VERSION "HNNBNNNYNNNNNNNNNNNNNNNNNNNNNNNNNNNNNNNNNN/4/%%%/4/'%**4NNN///"

NS_ :

BS_:

BU_: AEM BAP_Tester E_Sound FBK FLA Gateway Gateway_PAG ISE MRR_HL MRR_HR NightVision RDK SAK SAK2 SCR STH_MLBevo TopView

BO_ 977 TSG_BT_01: 8 Gateway
 SG_ BT_Tuer_geoeffnet : 0|1@1+ (1.0,0.0) [0.0|1] ""  Vector__XXX
 SG_ BT_verriegelt : 1|1@1+ (1.0,0.0) [0.0|1] ""  Vector__XXX
 SG_ BT_gesafet : 2|1@1+ (1.0,0.0) [0.0|1] ""  Vector__XXX
 SG_ BT_Schluesselschalter_auf : 3|1@1+ (1.0,0.0) [0.0|1] ""  Vector__XXX
 SG_ BT_Schluesselschalter_zu : 4|1@1+ (1.0,0.0) [0.0|1] ""  Vector__XXX
 SG_ BT_Unlock_Taster : 5|1@1+ (1.0,0.0) [0.0|1] ""  Vector__XXX
 SG_ BT_Lock_Taster : 6|1@1+ (1.0,0.0) [0.0|1] ""  Vector__XXX
 SG_ BT_Sperrklinke : 7|1@1+ (1.0,0.0) [0.0|1] ""  Vector__XXX
 SG_ BT_TAG_betaetigt : 8|1@1+ (1.0,0.0) [0.0|1] ""  Vector__XXX
 SG_ BT_TIG_betaetigt : 9|1@1+ (1.0,0.0) [0.0|1] ""  Vector__XXX
 SG_ BT_EC_Spiegel_Helligkeit : 10|5@1+ (3.125,0) [0.000|96.875] "Unit_PerCent"  Vector__XXX
 SG_ BT_Sp_Heizung_Anf : 15|1@1+ (100,0) [0|100] "Unit_PerCent"  Vector__XXX
 SG_ BT_Tuer_Status : 16|2@1+ (1.0,0.0) [0.0|3] ""  Vector__XXX
 SG_ BT_TSG_hinten_verbaut : 18|1@1+ (1.0,0.0) [0.0|1] ""  Vector__XXX
 SG_ BT_Sp_Blk_def : 19|1@1+ (1.0,0.0) [0.0|1] ""  Vector__XXX
 SG_ BT_FH_S_ManHoch : 20|1@1+ (1.0,0.0) [0.0|1] ""  Vector__XXX
 SG_ BT_FH_S_AutoHoch : 21|1@1+ (1.0,0.0) [0.0|1] ""  Vector__XXX
 SG_ BT_FH_S_ManTief : 22|1@1+ (1.0,0.0) [0.0|1] ""  Vector__XXX
 SG_ BT_FH_S_AutoTief : 23|1@1+ (1.0,0.0) [0.0|1] ""  Vector__XXX
 SG_ BT_FH_Oeffnung : 24|8@1+ (0.5,0) [0.0|100.0] "Unit_PerCent"  Vector__XXX
 SG_ BT_FH_Bew_hoch : 32|1@1+ (1.0,0.0) [0.0|1] ""  Vector__XXX
 SG_ BT_FH_Bew_tief : 33|1@1+ (1.0,0.0) [0.0|1] ""  Vector__XXX
 SG_ BT_FH_Fang : 34|1@1+ (1.0,0.0) [0.0|1] ""  Vector__XXX
 SG_ BT_FH_Block : 35|1@1+ (1.0,0.0) [0.0|1] ""  Vector__XXX
 SG_ BT_FH_Thermo : 36|1@1+ (1.0,0.0) [0.0|1] ""  Vector__XXX
 SG_ BT_UEKB_aktiviert : 37|1@1+ (1.0,0.0) [0.0|1] ""  Vector__XXX
 SG_ BT_Kisi_Fehler : 38|1@1+ (1.0,0.0) [0.0|1] ""  Vector__XXX
 SG_ BT_FH_normiert : 39|1@1+ (1.0,0.0) [0.0|1] ""  Vector__XXX
 SG_ BT_Schliesstaster : 40|1@1+ (1.0,0.0) [0.0|1] ""  Vector__XXX
 SG_ BT_Zuziehhilfe_aktiv : 41|1@1+ (1.0,0.0) [0.0|1] ""  Vector__XXX
 SG_ BT_SP_ausgerastet : 42|1@1+ (1.0,0.0) [0.0|1] ""  Vector__XXX
 SG_ BT_SP_lr_aktiv : 43|1@1+ (1.0,0.0) [0.0|1] ""  Vector__XXX
 SG_ BT_SP_ht_aktiv : 44|1@1+ (1.0,0.0) [0.0|1] ""  Vector__XXX
 SG_ BT_SP_Heizung_aktiv : 45|1@1+ (1.0,0.0) [0.0|1] ""  Vector__XXX
 SG_ BT_Oben_Block_erw : 46|1@1+ (1.0,0.0) [0.0|1] ""  Vector__XXX
 SG_ BT_Unten_Block_erw : 47|1@1+ (1.0,0.0) [0.0|1] ""  Vector__XXX
 SG_ BT_Tuer_Status_QBit : 48|1@1+ (1.0,0.0) [0.0|1] ""  Vector__XXX
 SG_ BFS_Status_eTAG : 49|2@1+ (1.0,0.0) [0.0|3] ""  Vector__XXX
 SG_ BT_TCR_Mode_aktiv : 51|1@1+ (1.0,0.0) [0.0|1] ""  Vector__XXX
 SG_ BT_SP_Heizung_Status : 55|1@1+ (1.0,0.0) [0.0|1] ""  Vector__XXX
 SG_ ASW_Warnung_aktiv_BFS : 56|1@1+ (1.0,0.0) [0.0|1] ""  MRR_HL,MRR_HR
 SG_ BT_FH_Pos_oben : 57|1@1+ (1.0,0.0) [0.0|1] ""  Vector__XXX
 SG_ BT_Tuerschloss_defekt : 58|1@1+ (1.0,0.0) [0.0|1] ""  Vector__XXX
 SG_ BT_Tueroeffnen_Warnung : 59|1@1+ (1.0,0.0) [0.0|1] ""  Vector__XXX
 SG_ BT_Lock_Taster_inv : 60|1@1+ (1.0,0.0) [0.0|1] ""  Vector__XXX
 SG_ BT_Schluesselschalter_zu_inv : 61|1@1+ (1.0,0.0) [0.0|1] ""  Vector__XXX
 SG_ BT_SWA_HMI_defekt : 62|1@1+ (1.0,0.0) [0.0|1] ""  Vector__XXX
 SG_ BT_ASW_HMI_defekt : 63|1@1+ (1.0,0.0) [0.0|1] ""  Vector__XXX

BO_ 976 TSG_FT_01: 8 Gateway
 SG_ FT_Tuer_geoeffnet : 0|1@1+ (1.0,0.0) [0.0|1] ""  Vector__XXX
 SG_ FT_verriegelt : 1|1@1+ (1.0,0.0) [0.0|1] ""  Vector__XXX
 SG_ FT_gesafet : 2|1@1+ (1.0,0.0) [0.0|1] ""  Vector__XXX
 SG_ FT_Schluesselschalter_auf : 3|1@1+ (1.0,0.0) [0.0|1] ""  Vector__XXX
 SG_ FT_Schluesselschalter_zu : 4|1@1+ (1.0,0.0) [0.0|1] ""  Vector__XXX
 SG_ FT_Unlock_Taster : 5|1@1+ (1.0,0.0) [0.0|1] ""  Vector__XXX
 SG_ FT_Lock_Taster : 6|1@1+ (1.0,0.0) [0.0|1] ""  Vector__XXX
 SG_ FT_Sperrklinke : 7|1@1+ (1.0,0.0) [0.0|1] ""  Vector__XXX
 SG_ FT_TAG_betaetigt : 8|1@1+ (1.0,0.0) [0.0|1] ""  Vector__XXX
 SG_ FT_TIG_betaetigt : 9|1@1+ (1.0,0.0) [0.0|1] ""  Vector__XXX
 SG_ FT_IRUE_Taste : 10|1@1+ (1.0,0.0) [0.0|1] ""  Vector__XXX
 SG_ FT_HD_Taste : 11|1@1+ (1.0,0.0) [0.0|1] ""  Vector__XXX
 SG_ FT_TD_Taste_Fehler : 12|1@1+ (1.0,0.0) [0.0|1] ""  Vector__XXX
 SG_ FT_TD_Taste : 13|1@1+ (1.0,0.0) [0.0|1] ""  Vector__XXX
 SG_ SSR_Temp_Freigabe : 14|1@1+ (1.0,0.0) [0.0|1] ""  Vector__XXX
 SG_ FT_Sp_Heizung_Anf : 15|1@1+ (100,0) [0|100] "Unit_PerCent"  Vector__XXX
 SG_ FT_HD_Taste_2 : 16|1@1+ (1.0,0.0) [0.0|1] ""  Vector__XXX
 SG_ FT_TSG_hinten_verbaut : 18|1@1+ (1.0,0.0) [0.0|1] ""  Vector__XXX
 SG_ FT_Sp_Blk_def : 19|1@1+ (1.0,0.0) [0.0|1] ""  Vector__XXX
 SG_ FT_FH_S_ManHoch : 20|1@1+ (1.0,0.0) [0.0|1] ""  Vector__XXX
 SG_ FT_FH_S_AutoHoch : 21|1@1+ (1.0,0.0) [0.0|1] ""  Vector__XXX
 SG_ FT_FH_S_ManTief : 22|1@1+ (1.0,0.0) [0.0|1] ""  Vector__XXX
 SG_ FT_FH_S_AutoTief : 23|1@1+ (1.0,0.0) [0.0|1] ""  Vector__XXX
 SG_ FT_FH_Oeffnung : 24|8@1+ (0.5,0) [0.0|100.0] "Unit_PerCent"  Vector__XXX
 SG_ FT_FH_Bew_hoch : 32|1@1+ (1.0,0.0) [0.0|1] ""  Vector__XXX
 SG_ FT_FH_Bew_tief : 33|1@1+ (1.0,0.0) [0.0|1] ""  Vector__XXX
 SG_ FT_FH_Fang : 34|1@1+ (1.0,0.0) [0.0|1] ""  Vector__XXX
 SG_ FT_FH_Block : 35|1@1+ (1.0,0.0) [0.0|1] ""  Vector__XXX
 SG_ FT_FH_Thermo : 36|1@1+ (1.0,0.0) [0.0|1] ""  Vector__XXX
 SG_ FT_UEKB_aktiviert : 37|1@1+ (1.0,0.0) [0.0|1] ""  Vector__XXX
 SG_ ASW_HMI_defekt : 38|1@1+ (1.0,0.0) [0.0|1] ""  MRR_HL,MRR_HR
 SG_ FT_FH_normiert : 39|1@1+ (1.0,0.0) [0.0|1] ""  Vector__XXX
 SG_ FT_Schliesstaster : 40|1@1+ (1.0,0.0) [0.0|1] ""  Vector__XXX
 SG_ FT_Zuziehhilfe_aktiv : 41|1@1+ (1.0,0.0) [0.0|1] ""  Vector__XXX
 SG_ FT_SP_ausgerastet : 42|1@1+ (1.0,0.0) [0.0|1] ""  Vector__XXX
 SG_ FT_SP_lr_aktiv : 43|1@1+ (1.0,0.0) [0.0|1] ""  Vector__XXX
 SG_ FT_SP_ht_aktiv : 44|1@1+ (1.0,0.0) [0.0|1] ""  Vector__XXX
 SG_ ASW_wakeup : 45|1@1+ (1.0,0.0) [0.0|1] ""  MRR_HL,MRR_HR
 SG_ FT_Oben_Block_erw : 46|1@1+ (1.0,0.0) [0.0|1] ""  Vector__XXX
 SG_ FT_Unten_Block_erw : 47|1@1+ (1.0,0.0) [0.0|1] ""  Vector__XXX
 SG_ FT_Kisi_li_aktiv : 48|1@1+ (1.0,0.0) [0.0|1] ""  Vector__XXX
 SG_ FT_Kisi_re_aktiv : 49|1@1+ (1.0,0.0) [0.0|1] ""  Vector__XXX
 SG_ FT_Kisi_Taster_li : 50|1@1+ (1.0,0.0) [0.0|1] ""  Vector__XXX
 SG_ FT_Kisi_Taster_re : 51|1@1+ (1.0,0.0) [0.0|1] ""  Vector__XXX
 SG_ FT_BFS_Fond_Freigabe : 52|1@1+ (1.0,0.0) [0.0|1] ""  Vector__XXX
 SG_ FT_Kisi_Fehler : 53|1@1+ (1.0,0.0) [0.0|1] ""  Vector__XXX
 SG_ FT_Daemmglas : 54|1@1+ (1.0,0.0) [0.0|1] ""  Vector__XXX
 SG_ FT_SP_Heizung_Status : 55|1@1+ (1.0,0.0) [0.0|1] ""  Vector__XXX
 SG_ ASW_Warnung_aktiv_FS : 56|1@1+ (1.0,0.0) [0.0|1] ""  MRR_HL,MRR_HR
 SG_ FT_FH_Pos_oben : 57|1@1+ (1.0,0.0) [0.0|1] ""  Vector__XXX
 SG_ FT_Tuerschloss_defekt : 58|1@1+ (1.0,0.0) [0.0|1] ""  Vector__XXX
 SG_ FT_SWA_Taster : 59|1@1+ (1.0,0.0) [0.0|1] ""  MRR_HR
 SG_ SWA_HMI_Diagnose : 60|2@1+ (1.0,0.0) [0.0|3] ""  MRR_HL,MRR_HR
 SG_ FS_Status_eTAG : 62|2@1+ (1.0,0.0) [0.0|3] ""  Vector__XXX

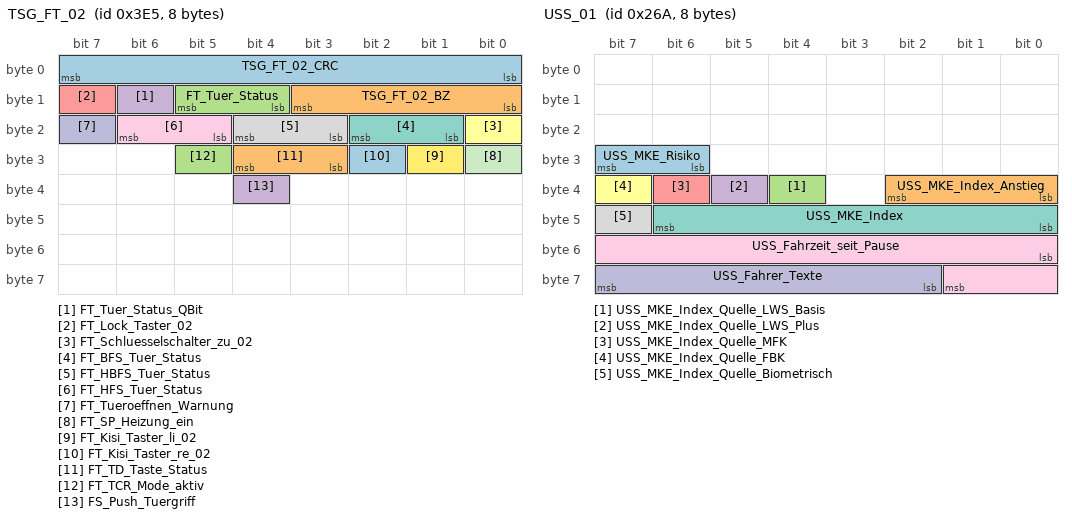
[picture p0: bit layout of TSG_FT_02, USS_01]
BO_ 997 TSG_FT_02: 8 Gateway
 SG_ TSG_FT_02_CRC : 0|8@1+ (1,0) [0|255] ""  Vector__XXX
 SG_ TSG_FT_02_BZ : 8|4@1+ (1,0) [0|15] ""  Vector__XXX
 SG_ FT_Tuer_Status : 12|2@1+ (1.0,0.0) [0.0|3] ""  FBK
 SG_ FT_Tuer_Status_QBit : 14|1@1+ (1.0,0.0) [0.0|1] ""  FBK
 SG_ FT_Lock_Taster_02 : 15|1@1+ (1.0,0.0) [0.0|1] ""  Vector__XXX
 SG_ FT_Schluesselschalter_zu_02 : 16|1@1+ (1.0,0.0) [0.0|1] ""  Vector__XXX
 SG_ FT_BFS_Tuer_Status : 17|2@1+ (1.0,0.0) [0.0|3] ""  Vector__XXX
 SG_ FT_HBFS_Tuer_Status : 19|2@1+ (1.0,0.0) [0.0|3] ""  Vector__XXX
 SG_ FT_HFS_Tuer_Status : 21|2@1+ (1.0,0.0) [0.0|3] ""  Vector__XXX
 SG_ FT_Tueroeffnen_Warnung : 23|1@1+ (1.0,0.0) [0.0|1] ""  Vector__XXX
 SG_ FT_SP_Heizung_ein : 24|1@1+ (1.0,0.0) [0.0|1] ""  Vector__XXX
 SG_ FT_Kisi_Taster_li_02 : 25|1@1+ (1.0,0.0) [0.0|1] ""  Vector__XXX
 SG_ FT_Kisi_Taster_re_02 : 26|1@1+ (1.0,0.0) [0.0|1] ""  Vector__XXX
 SG_ FT_TD_Taste_Status : 27|2@1+ (1.0,0.0) [0.0|3] ""  Vector__XXX
 SG_ FT_TCR_Mode_aktiv : 29|1@1+ (1.0,0.0) [0.0|1] ""  Vector__XXX
 SG_ FS_Push_Tuergriff : 36|1@1+ (1.0,0.0) [0.0|1] ""  Vector__XXX

BO_ 975 TSG_HBFS_01: 8 Gateway
 SG_ HBFS_Tuer_geoeffnet : 0|1@1+ (1.0,0.0) [0.0|1] ""  Vector__XXX
 SG_ HBFS_verriegelt : 1|1@1+ (1.0,0.0) [0.0|1] ""  Vector__XXX
 SG_ HBFS_gesafet : 2|1@1+ (1.0,0.0) [0.0|1] ""  Vector__XXX
 SG_ HBFS_Heckrollotaster_betaetigt : 3|1@1+ (1.0,0.0) [0.0|1] ""  Vector__XXX
 SG_ HBFS_Tuerschloss_defekt : 4|1@1+ (1.0,0.0) [0.0|1] ""  Vector__XXX
 SG_ HBFS_Unlock_Taster : 5|1@1+ (1.0,0.0) [0.0|1] ""  Vector__XXX
 SG_ HBFS_Lock_Taster : 6|1@1+ (1.0,0.0) [0.0|1] ""  Vector__XXX
 SG_ HBFS_Sperrklinke : 7|1@1+ (1.0,0.0) [0.0|1] ""  Vector__XXX
 SG_ HBFS_TAG_betaetigt : 8|1@1+ (1.0,0.0) [0.0|1] ""  Vector__XXX
 SG_ HBFS_TIG_betaetigt : 9|1@1+ (1.0,0.0) [0.0|1] ""  Vector__XXX
 SG_ HBFS_FH_S_HFS_AutoHoch : 10|1@1+ (1.0,0.0) [0.0|1] ""  Vector__XXX
 SG_ HBFS_FH_S_HFS_AutoTief : 11|1@1+ (1.0,0.0) [0.0|1] ""  Vector__XXX
 SG_ HBFS_FH_S_HFS_ManHoch : 12|1@1+ (1.0,0.0) [0.0|1] ""  Vector__XXX
 SG_ HBFS_FH_S_HFS_ManTief : 13|1@1+ (1.0,0.0) [0.0|1] ""  Vector__XXX
 SG_ HBFS_Tuer_Status : 14|2@1+ (1.0,0.0) [0.0|3] ""  Vector__XXX
 SG_ HBFS_SAD_Schalter : 16|4@1+ (1.0,0.0) [0.0|15] ""  Vector__XXX
 SG_ HBFS_FH_S_ManHoch : 20|1@1+ (1.0,0.0) [0.0|1] ""  Vector__XXX
 SG_ HBFS_FH_S_AutoHoch : 21|1@1+ (1.0,0.0) [0.0|1] ""  Vector__XXX
 SG_ HBFS_FH_S_ManTief : 22|1@1+ (1.0,0.0) [0.0|1] ""  Vector__XXX
 SG_ HBFS_FH_S_AutoTief : 23|1@1+ (1.0,0.0) [0.0|1] ""  Vector__XXX
 SG_ HBFS_FH_Oeffnung : 24|8@1+ (0.5,0) [0.0|100.0] "Unit_PerCent"  Vector__XXX
 SG_ HBFS_FH_Bew_hoch : 32|1@1+ (1.0,0.0) [0.0|1] ""  Vector__XXX
 SG_ HBFS_FH_Bew_tief : 33|1@1+ (1.0,0.0) [0.0|1] ""  Vector__XXX
 SG_ HBFS_FH_Fang : 34|1@1+ (1.0,0.0) [0.0|1] ""  Vector__XXX
 SG_ HBFS_FH_Block : 35|1@1+ (1.0,0.0) [0.0|1] ""  Vector__XXX
 SG_ HBFS_FH_Thermo : 36|1@1+ (1.0,0.0) [0.0|1] ""  Vector__XXX
 SG_ HBFS_UEKB_aktiviert : 37|1@1+ (1.0,0.0) [0.0|1] ""  Vector__XXX
 SG_ HBFS_Tueroeffnen_Warnung : 38|1@1+ (1.0,0.0) [0.0|1] ""  Vector__XXX
 SG_ HBFS_FH_normiert : 39|1@1+ (1.0,0.0) [0.0|1] ""  Vector__XXX
 SG_ ASW_Warnung_aktiv_HBFS : 40|1@1+ (1.0,0.0) [0.0|1] ""  MRR_HL,MRR_HR
 SG_ HBFS_Zuziehhilfe_aktiv : 41|1@1+ (1.0,0.0) [0.0|1] ""  Vector__XXX
 SG_ HBFS_Seitenrollo_hoch : 42|1@1+ (1.0,0.0) [0.0|1] ""  Vector__XXX
 SG_ HBFS_Seitenrollo_tief : 43|1@1+ (1.0,0.0) [0.0|1] ""  Vector__XXX
 SG_ HBFS_Status_KiSi : 44|1@1+ (1.0,0.0) [0.0|1] ""  Vector__XXX
 SG_ SSR_HBFS_Pos_Unten : 45|1@1+ (1.0,0.0) [0.0|1] ""  Vector__XXX
 SG_ HBFS_Oben_Block_erw : 46|1@1+ (1.0,0.0) [0.0|1] ""  Vector__XXX
 SG_ HBFS_Unten_Block_erw : 47|1@1+ (1.0,0.0) [0.0|1] ""  Vector__XXX
 SG_ MTHBFS_M_Taste : 48|1@1+ (1.0,0.0) [0.0|1] ""  Vector__XXX
 SG_ MTHBFS_Pos1 : 49|1@1+ (1.0,0.0) [0.0|1] ""  Vector__XXX
 SG_ MTHBFS_Pos2 : 50|1@1+ (1.0,0.0) [0.0|1] ""  Vector__XXX
 SG_ MTHBFS_Pos3 : 51|1@1+ (1.0,0.0) [0.0|1] ""  Vector__XXX
 SG_ HBFS_MRollo_Schalter : 52|3@1+ (1.0,0.0) [0.0|7] ""  Vector__XXX
 SG_ HBFS_Lock_Taster_inv : 55|1@1+ (1.0,0.0) [0.0|1] ""  Vector__XXX
 SG_ HBFS_Status_KiSi_inv : 56|1@1+ (1.0,0.0) [0.0|1] ""  Vector__XXX
 SG_ HBFS_Status_eTAG : 57|2@1+ (1.0,0.0) [0.0|3] ""  Vector__XXX
 SG_ HBFS_Tuer_Status_QBit : 59|1@1+ (1.0,0.0) [0.0|1] ""  Vector__XXX
 SG_ HBFS_TIG_betaetigt_schliessen : 60|1@1+ (1.0,0.0) [0.0|1] ""  Vector__XXX

BO_ 974 TSG_HFS_01: 8 Gateway
 SG_ HFS_Tuer_geoeffnet : 0|1@1+ (1.0,0.0) [0.0|1] ""  Vector__XXX
 SG_ HFS_verriegelt : 1|1@1+ (1.0,0.0) [0.0|1] ""  Vector__XXX
 SG_ HFS_gesafet : 2|1@1+ (1.0,0.0) [0.0|1] ""  Vector__XXX
 SG_ HFS_Heckrollotaster_betaetigt : 3|1@1+ (1.0,0.0) [0.0|1] ""  Vector__XXX
 SG_ HFS_Tuerschloss_defekt : 4|1@1+ (1.0,0.0) [0.0|1] ""  Vector__XXX
 SG_ HFS_Unlock_Taster : 5|1@1+ (1.0,0.0) [0.0|1] ""  Vector__XXX
 SG_ HFS_Lock_Taster : 6|1@1+ (1.0,0.0) [0.0|1] ""  Vector__XXX
 SG_ HFS_Sperrklinke : 7|1@1+ (1.0,0.0) [0.0|1] ""  Vector__XXX
 SG_ HFS_TAG_betaetigt : 8|1@1+ (1.0,0.0) [0.0|1] ""  Vector__XXX
 SG_ HFS_TIG_betaetigt : 9|1@1+ (1.0,0.0) [0.0|1] ""  Vector__XXX
 SG_ HFS_FH_S_HBFS_AutoHoch : 10|1@1+ (1.0,0.0) [0.0|1] ""  Vector__XXX
 SG_ HFS_FH_S_HBFS_AutoTief : 11|1@1+ (1.0,0.0) [0.0|1] ""  Vector__XXX
 SG_ HFS_FH_S_HBFS_ManHoch : 12|1@1+ (1.0,0.0) [0.0|1] ""  Vector__XXX
 SG_ HFS_FH_S_HBFS_ManTief : 13|1@1+ (1.0,0.0) [0.0|1] ""  Vector__XXX
 SG_ HFS_Tuer_Status : 14|2@1+ (1.0,0.0) [0.0|3] ""  Vector__XXX
 SG_ HFS_SAD_Schalter : 16|4@1+ (1.0,0.0) [0.0|15] ""  Vector__XXX
 SG_ HFS_FH_S_ManHoch : 20|1@1+ (1.0,0.0) [0.0|1] ""  Vector__XXX
 SG_ HFS_FH_S_AutoHoch : 21|1@1+ (1.0,0.0) [0.0|1] ""  Vector__XXX
 SG_ HFS_FH_S_ManTief : 22|1@1+ (1.0,0.0) [0.0|1] ""  Vector__XXX
 SG_ HFS_FH_S_AutoTief : 23|1@1+ (1.0,0.0) [0.0|1] ""  Vector__XXX
 SG_ HFS_FH_Oeffnung : 24|8@1+ (0.5,0) [0.0|100.0] "Unit_PerCent"  Vector__XXX
 SG_ HFS_FH_Bew_hoch : 32|1@1+ (1.0,0.0) [0.0|1] ""  Vector__XXX
 SG_ HFS_FH_Bew_tief : 33|1@1+ (1.0,0.0) [0.0|1] ""  Vector__XXX
 SG_ HFS_FH_Fang : 34|1@1+ (1.0,0.0) [0.0|1] ""  Vector__XXX
 SG_ HFS_FH_Block : 35|1@1+ (1.0,0.0) [0.0|1] ""  Vector__XXX
 SG_ HFS_FH_Thermo : 36|1@1+ (1.0,0.0) [0.0|1] ""  Vector__XXX
 SG_ HFS_UEKB_aktiviert : 37|1@1+ (1.0,0.0) [0.0|1] ""  Vector__XXX
 SG_ HFS_Tueroeffnen_Warnung : 38|1@1+ (1.0,0.0) [0.0|1] ""  Vector__XXX
 SG_ HFS_FH_normiert : 39|1@1+ (1.0,0.0) [0.0|1] ""  Vector__XXX
 SG_ ASW_Warnung_aktiv_HFS : 40|1@1+ (1.0,0.0) [0.0|1] ""  MRR_HL,MRR_HR
 SG_ HFS_Zuziehhilfe_aktiv : 41|1@1+ (1.0,0.0) [0.0|1] ""  Vector__XXX
 SG_ HFS_Seitenrollo_hoch : 42|1@1+ (1.0,0.0) [0.0|1] ""  Vector__XXX
 SG_ HFS_Seitenrollo_tief : 43|1@1+ (1.0,0.0) [0.0|1] ""  Vector__XXX
 SG_ HFS_Status_KiSi : 44|1@1+ (1.0,0.0) [0.0|1] ""  Vector__XXX
 SG_ SSR_HFS_Pos_Unten : 45|1@1+ (1.0,0.0) [0.0|1] ""  Vector__XXX
 SG_ HFS_Oben_Block_erw : 46|1@1+ (1.0,0.0) [0.0|1] ""  Vector__XXX
 SG_ HFS_Unten_Block_erw : 47|1@1+ (1.0,0.0) [0.0|1] ""  Vector__XXX
 SG_ MTHFS_M_Taste : 48|1@1+ (1.0,0.0) [0.0|1] ""  Vector__XXX
 SG_ MTHFS_Pos1 : 49|1@1+ (1.0,0.0) [0.0|1] ""  Vector__XXX
 SG_ MTHFS_Pos2 : 50|1@1+ (1.0,0.0) [0.0|1] ""  Vector__XXX
 SG_ MTHFS_Pos3 : 51|1@1+ (1.0,0.0) [0.0|1] ""  Vector__XXX
 SG_ HFS_MRollo_Schalter : 52|3@1+ (1.0,0.0) [0.0|7] ""  Vector__XXX
 SG_ HFS_Lock_Taster_inv : 55|1@1+ (1.0,0.0) [0.0|1] ""  Vector__XXX
 SG_ HFS_Status_eTAG : 56|2@1+ (1.0,0.0) [0.0|3] ""  Vector__XXX
 SG_ HFS_Tuer_Status_QBit : 58|1@1+ (1.0,0.0) [0.0|1] ""  Vector__XXX
 SG_ HFS_TCR_Mode_aktiv : 59|1@1+ (1.0,0.0) [0.0|1] ""  Vector__XXX

BO_ 618 USS_01: 8 Gateway
 SG_ USS_MKE_Risiko : 30|2@1+ (1.0,0.0) [0.0|3] ""  NightVision
 SG_ USS_MKE_Index_Anstieg : 32|3@1+ (1.0,0.0) [0.0|7] ""  NightVision
 SG_ USS_MKE_Index_Quelle_LWS_Basis : 36|1@1+ (1.0,0.0) [0.0|1] ""  NightVision
 SG_ USS_MKE_Index_Quelle_LWS_Plus : 37|1@1+ (1.0,0.0) [0.0|1] ""  NightVision
 SG_ USS_MKE_Index_Quelle_MFK : 38|1@1+ (1.0,0.0) [0.0|1] ""  NightVision
 SG_ USS_MKE_Index_Quelle_FBK : 39|1@1+ (1.0,0.0) [0.0|1] ""  NightVision
 SG_ USS_MKE_Index : 40|7@1+ (0.1,0) [0.0|10.0] ""  NightVision
 SG_ USS_MKE_Index_Quelle_Biometrisch : 47|1@1+ (1.0,0.0) [0.0|1] ""  NightVision
 SG_ USS_Fahrzeit_seit_Pause : 48|10@1+ (1,0) [0|1020] "Unit_Minut"  NightVision
 SG_ USS_Fahrer_Texte : 58|6@1+ (1.0,0.0) [0.0|63] ""  NightVision

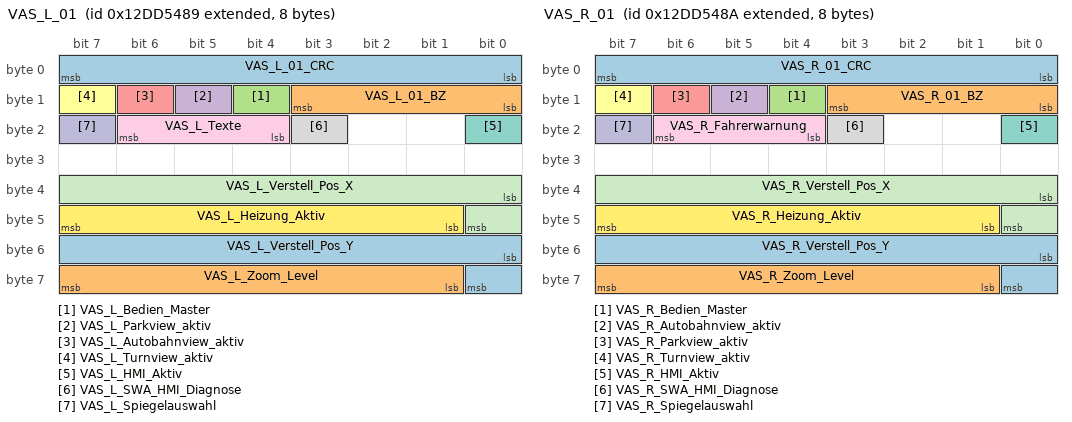
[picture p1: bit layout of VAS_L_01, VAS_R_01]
BO_ 2463978633 VAS_L_01: 8 Gateway
 SG_ VAS_L_01_CRC : 0|8@1+ (1,0) [0|255] ""  Vector__XXX
 SG_ VAS_L_01_BZ : 8|4@1+ (1,0) [0|15] ""  Vector__XXX
 SG_ VAS_L_Bedien_Master : 12|1@1+ (1.0,0.0) [0.0|1] ""  Vector__XXX
 SG_ VAS_L_Parkview_aktiv : 13|1@1+ (1.0,0.0) [0.0|1] ""  Vector__XXX
 SG_ VAS_L_Autobahnview_aktiv : 14|1@1+ (1.0,0.0) [0.0|1] ""  Vector__XXX
 SG_ VAS_L_Turnview_aktiv : 15|1@1+ (1.0,0.0) [0.0|1] ""  Vector__XXX
 SG_ VAS_L_HMI_Aktiv : 16|1@1+ (1.0,0.0) [0.0|1] ""  Vector__XXX
 SG_ VAS_L_SWA_HMI_Diagnose : 19|1@1+ (1.0,0.0) [0.0|1] ""  MRR_HL,MRR_HR
 SG_ VAS_L_Texte : 20|3@1+ (1.0,0.0) [0.0|7] ""  Vector__XXX
 SG_ VAS_L_Spiegelauswahl : 23|1@1+ (1.0,0.0) [0.0|1] ""  Vector__XXX
 SG_ VAS_L_Verstell_Pos_X : 32|9@1+ (1,0) [0|400] "Unit_None"  Vector__XXX
 SG_ VAS_L_Heizung_Aktiv : 41|7@1+ (1,0) [0|100] "Unit_PerCent"  Vector__XXX
 SG_ VAS_L_Verstell_Pos_Y : 48|9@1+ (1,0) [0|400] "Unit_None"  Vector__XXX
 SG_ VAS_L_Zoom_Level : 57|7@1+ (1,0) [0|100] "Unit_PerCent"  Vector__XXX

BO_ 2463978634 VAS_R_01: 8 Gateway
 SG_ VAS_R_01_CRC : 0|8@1+ (1,0) [0|255] ""  Vector__XXX
 SG_ VAS_R_01_BZ : 8|4@1+ (1,0) [0|15] ""  Vector__XXX
 SG_ VAS_R_Bedien_Master : 12|1@1+ (1.0,0.0) [0.0|1] ""  Vector__XXX
 SG_ VAS_R_Autobahnview_aktiv : 13|1@1+ (1.0,0.0) [0.0|1] ""  Vector__XXX
 SG_ VAS_R_Parkview_aktiv : 14|1@1+ (1.0,0.0) [0.0|1] ""  Vector__XXX
 SG_ VAS_R_Turnview_aktiv : 15|1@1+ (1.0,0.0) [0.0|1] ""  Vector__XXX
 SG_ VAS_R_HMI_Aktiv : 16|1@1+ (1.0,0.0) [0.0|1] ""  Vector__XXX
 SG_ VAS_R_SWA_HMI_Diagnose : 19|1@1+ (1.0,0.0) [0.0|1] ""  MRR_HL,MRR_HR
 SG_ VAS_R_Fahrerwarnung : 20|3@1+ (1.0,0.0) [0.0|7] ""  Vector__XXX
 SG_ VAS_R_Spiegelauswahl : 23|1@1+ (1.0,0.0) [0.0|1] ""  Vector__XXX
 SG_ VAS_R_Verstell_Pos_X : 32|9@1+ (1,0) [0|400] "Unit_None"  Vector__XXX
 SG_ VAS_R_Heizung_Aktiv : 41|7@1+ (1,0) [0|100] "Unit_PerCent"  Vector__XXX
 SG_ VAS_R_Verstell_Pos_Y : 48|9@1+ (1,0) [0|400] "Unit_None"  Vector__XXX
 SG_ VAS_R_Zoom_Level : 57|7@1+ (1,0) [0|100] "Unit_PerCent"  Vector__XXX

BO_ 995 Verdeck_01: 8 Gateway
 SG_ Verdeck_01_CRC : 0|8@1+ (1,0) [0|255] ""  Vector__XXX
 SG_ Verdeck_01_BZ : 8|4@1+ (1,0) [0|15] ""  Vector__XXX
 SG_ VS_VD_zu_ver : 16|1@1+ (1.0,0.0) [0.0|1] ""  ISE,SAK,SAK2
 SG_ VS_VD_entriegelt : 17|1@1+ (1.0,0.0) [0.0|1] ""  SAK,SAK2
 SG_ VS_VD_offen_ver : 18|1@1+ (1.0,0.0) [0.0|1] ""  ISE,SAK,SAK2
 SG_ VS_VD_Zwischenposition : 19|1@1+ (1.0,0.0) [0.0|1] ""  SAK,SAK2
 SG_ VS_VD_Bew_auf : 20|1@1+ (1.0,0.0) [0.0|1] ""  Vector__XXX
 SG_ VS_VD_Bew_zu : 21|1@1+ (1.0,0.0) [0.0|1] ""  Vector__XXX
 SG_ VS_Verdeck_Anf : 22|1@1+ (1.0,0.0) [0.0|1] ""  Vector__XXX
 SG_ VS_Hardtop : 23|1@1+ (1.0,0.0) [0.0|1] ""  Vector__XXX
 SG_ VS_VD_Fehler : 24|1@1+ (1.0,0.0) [0.0|1] ""  Vector__XXX
 SG_ VS_Lampe_Blk : 25|1@1+ (1.0,0.0) [0.0|1] ""  Vector__XXX
 SG_ VS_Buzzer : 26|1@1+ (1.0,0.0) [0.0|1] ""  Vector__XXX
 SG_ VS_HD_sperren : 27|1@1+ (1.0,0.0) [0.0|1] ""  Vector__XXX
 SG_ VS_HHS_enable : 28|1@1+ (1.0,0.0) [0.0|1] ""  Vector__XXX
 SG_ VD_SpannungsAnf : 29|2@1+ (1.0,0.0) [0.0|3] ""  Vector__XXX
 SG_ VS_VDKD_auf : 31|1@1+ (1.0,0.0) [0.0|1] ""  Vector__XXX
 SG_ VS_FS_AutoHoch : 32|1@1+ (1.0,0.0) [0.0|1] ""  Vector__XXX
 SG_ VS_FS_AutoTief : 33|1@1+ (1.0,0.0) [0.0|1] ""  Vector__XXX
 SG_ VS_FS_ManHoch : 34|1@1+ (1.0,0.0) [0.0|1] ""  Vector__XXX
 SG_ VS_FS_ManTief : 35|1@1+ (1.0,0.0) [0.0|1] ""  Vector__XXX
 SG_ VS_BFS_AutoHoch : 36|1@1+ (1.0,0.0) [0.0|1] ""  Vector__XXX
 SG_ VS_BFS_AutoTief : 37|1@1+ (1.0,0.0) [0.0|1] ""  Vector__XXX
 SG_ VS_BFS_ManHoch : 38|1@1+ (1.0,0.0) [0.0|1] ""  Vector__XXX
 SG_ VS_BFS_ManTief : 39|1@1+ (1.0,0.0) [0.0|1] ""  Vector__XXX
 SG_ VS_HFS_AutoHoch : 40|1@1+ (1.0,0.0) [0.0|1] ""  Vector__XXX
 SG_ VS_HFS_AutoTief : 41|1@1+ (1.0,0.0) [0.0|1] ""  Vector__XXX
 SG_ VS_HFS_ManHoch : 42|1@1+ (1.0,0.0) [0.0|1] ""  Vector__XXX
 SG_ VS_HFS_ManTief : 43|1@1+ (1.0,0.0) [0.0|1] ""  Vector__XXX
 SG_ VS_HBFS_AutoHoch : 44|1@1+ (1.0,0.0) [0.0|1] ""  Vector__XXX
 SG_ VS_HBFS_AutoTief : 45|1@1+ (1.0,0.0) [0.0|1] ""  Vector__XXX
 SG_ VS_HBFS_ManHoch : 46|1@1+ (1.0,0.0) [0.0|1] ""  Vector__XXX
 SG_ VS_HBFS_ManTief : 47|1@1+ (1.0,0.0) [0.0|1] ""  Vector__XXX
 SG_ VS_FH_FT_Langhub : 49|1@1+ (1.0,0.0) [0.0|1] ""  Vector__XXX
 SG_ VS_Windschott_nicht_abgelegt : 50|1@1+ (1.0,0.0) [0.0|1] ""  Vector__XXX
 SG_ VS_FH_BT_Langhub : 51|1@1+ (1.0,0.0) [0.0|1] ""  Vector__XXX
 SG_ VS_FH_HFS_Langhub : 53|1@1+ (1.0,0.0) [0.0|1] ""  Vector__XXX
 SG_ VS_Heckschloss_auf : 54|1@1+ (1.0,0.0) [0.0|1] ""  Vector__XXX
 SG_ VS_FH_HBFS_Langhub : 55|1@1+ (1.0,0.0) [0.0|1] ""  Vector__XXX
 SG_ VSG_Meldungen : 56|6@1+ (1,0) [1|63] "Unit_None"  Vector__XXX
 SG_ VS_StartStopp_Info : 62|2@1+ (1.0,0.0) [0.0|3] ""  Vector__XXX

BO_ 1716 VIN_01: 8 Gateway
 SG_ VIN_01_MUX M  : 0|2@1+ (1,0) [0|3] ""  AEM,E_Sound,ISE,NightVision,SAK,SAK2,SCR
 SG_ KS_Geheimnis_1 m0  : 8|8@1+ (1,0) [0|255] ""  Vector__XXX
 SG_ VIN_4 m1  : 8|8@1+ (1,0) [0|255] ""  AEM,E_Sound,ISE,NightVision,SAK,SAK2
 SG_ VIN_11 m2  : 8|8@1+ (1,0) [0|255] ""  AEM,E_Sound,ISE,NightVision,SAK,SAK2
 SG_ KS_Geheimnis_2 m0  : 16|8@1+ (1,0) [0|255] ""  Vector__XXX
 SG_ VIN_5 m1  : 16|8@1+ (1,0) [0|255] ""  AEM,E_Sound,ISE,NightVision,SAK,SAK2
 SG_ VIN_12 m2  : 16|8@1+ (1,0) [0|255] ""  AEM,E_Sound,ISE,NightVision,SAK,SAK2
 SG_ KS_Geheimnis_3 m0  : 24|8@1+ (1,0) [0|255] ""  Vector__XXX
 SG_ VIN_6 m1  : 24|8@1+ (1,0) [0|255] ""  AEM,E_Sound,ISE,NightVision,SAK,SAK2
 SG_ VIN_13 m2  : 24|8@1+ (1,0) [0|255] ""  AEM,E_Sound,ISE,NightVision,SAK,SAK2
 SG_ KS_Geheimnis_4 m0  : 32|8@1+ (1,0) [0|255] ""  Vector__XXX
 SG_ VIN_7 m1  : 32|8@1+ (1,0) [0|255] ""  AEM,E_Sound,ISE,NightVision,SAK,SAK2,SCR
 SG_ VIN_14 m2  : 32|8@1+ (1,0) [0|255] ""  AEM,E_Sound,ISE,NightVision,SAK,SAK2
 SG_ VIN_1 m0  : 40|8@1+ (1,0) [0|255] ""  AEM,E_Sound,ISE,NightVision,SAK,SAK2
 SG_ VIN_8 m1  : 40|8@1+ (1,0) [0|255] ""  AEM,E_Sound,ISE,NightVision,SAK,SAK2,SCR
 SG_ VIN_15 m2  : 40|8@1+ (1,0) [0|255] ""  AEM,E_Sound,ISE,NightVision,SAK,SAK2
 SG_ VIN_2 m0  : 48|8@1+ (1,0) [0|255] ""  AEM,E_Sound,ISE,NightVision,SAK,SAK2
 SG_ VIN_9 m1  : 48|8@1+ (1,0) [0|255] ""  AEM,E_Sound,ISE,NightVision,SAK,SAK2
 SG_ VIN_16 m2  : 48|8@1+ (1,0) [0|255] ""  AEM,E_Sound,ISE,NightVision,SAK,SAK2
 SG_ VIN_3 m0  : 56|8@1+ (1,0) [0|255] ""  AEM,E_Sound,ISE,NightVision,SAK,SAK2
 SG_ VIN_10 m1  : 56|8@1+ (1,0) [0|255] ""  AEM,E_Sound,ISE,NightVision,SAK,SAK2
 SG_ VIN_17 m2  : 56|8@1+ (1,0) [0|255] ""  AEM,E_Sound,ISE,NightVision,SAK,SAK2,SCR

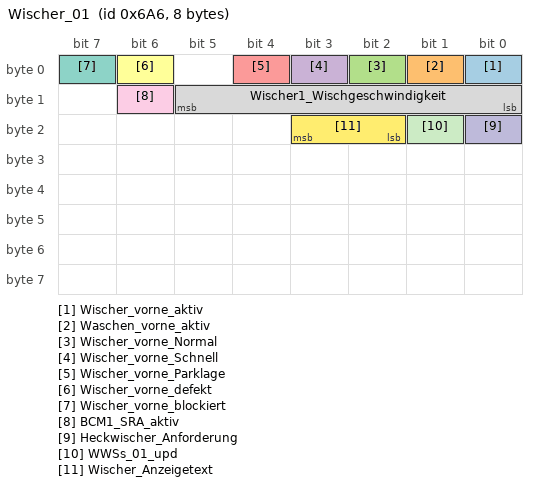
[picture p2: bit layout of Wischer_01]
BO_ 1702 Wischer_01: 8 Gateway
 SG_ Wischer_vorne_aktiv : 0|1@1+ (1.0,0.0) [0.0|1] ""  Vector__XXX
 SG_ Waschen_vorne_aktiv : 1|1@1+ (1.0,0.0) [0.0|1] ""  Vector__XXX
 SG_ Wischer_vorne_Normal : 2|1@1+ (1.0,0.0) [0.0|1] ""  Vector__XXX
 SG_ Wischer_vorne_Schnell : 3|1@1+ (1.0,0.0) [0.0|1] ""  Vector__XXX
 SG_ Wischer_vorne_Parklage : 4|1@1+ (1.0,0.0) [0.0|1] ""  Vector__XXX
 SG_ Wischer_vorne_defekt : 6|1@1+ (1.0,0.0) [0.0|1] ""  Vector__XXX
 SG_ Wischer_vorne_blockiert : 7|1@1+ (1.0,0.0) [0.0|1] ""  Vector__XXX
 SG_ Wischer1_Wischgeschwindigkeit : 8|6@1+ (1,9) [10|70] "Unit_MinutInver"  Vector__XXX
 SG_ BCM1_SRA_aktiv : 14|1@1+ (1.0,0.0) [0.0|1] ""  NightVision
 SG_ Heckwischer_Anforderung : 16|1@1+ (1.0,0.0) [0.0|1] ""  Vector__XXX
 SG_ WWSs_01_upd : 17|1@1+ (1.0,0.0) [0.0|1] ""  Vector__XXX
 SG_ Wischer_Anzeigetext : 18|2@1+ (1.0,0.0) [0.0|3] ""  Vector__XXX

BO_ 2617079296 XCP_AEM_CRO_01: 8 Vector__XXX
 SG_ XCP_AEM_CRO_01_Data : 0|64@1+ (1,0) [0|1] ""  AEM

BO_ 2617079297 XCP_AEM_DTO_01: 8 AEM
 SG_ XCP_AEM_DTO_01_Data : 0|64@1+ (1,0) [0|1] ""  Vector__XXX

BO_ 2617083392 XCP_FLA_CRO_01: 8 Vector__XXX
 SG_ XCP_FLA_CRO_01_Data : 0|64@1+ (1,0) [0|1] ""  FLA

BO_ 2617083393 XCP_FLA_DTO_01: 8 FLA
 SG_ XCP_FLA_DTO_01_Data : 0|64@1+ (1,0) [0|1] ""  Vector__XXX

BO_ 2617064960 XCP_Nightvision_CRO_01: 8 Vector__XXX
 SG_ XCP_Nightvision_CRO_01_Data : 0|64@1+ (1,0) [0|1] ""  NightVision

BO_ 2617064961 XCP_Nightvision_DTO_01: 8 NightVision
 SG_ XCP_Nightvision_DTO_01_Data : 0|64@1+ (1,0) [0|1] ""  Vector__XXX

BO_ 2617007616 XCP_RDK_CRO_01: 8 Vector__XXX
 SG_ XCP_RDK_CRO_01_Data : 0|64@1+ (1,0) [0|1] ""  RDK

BO_ 2617007617 XCP_RDK_DTO_01: 8 RDK
 SG_ XCP_RDK_DTO_01_Data : 0|64@1+ (1,0) [0|1] ""  Vector__XXX

BO_ 2617200128 XCP_RearView_CRO_01: 8 Vector__XXX
 SG_ XCP_TopView_CRO_01_Data : 0|64@1+ (1,0) [0|1] ""  TopView

BO_ 2617200129 XCP_RearView_DTO_01: 8 TopView
 SG_ XCP_TopView_DTO_01_Data : 0|64@1+ (1,0) [0|1] ""  Vector__XXX

BO_ 2617071104 XCP_SCR_CRO_01: 8 Vector__XXX
 SG_ XCP_SCR_CRO_01_Data : 0|64@1+ (1,0) [0|1] ""  SCR

BO_ 2617071105 XCP_SCR_DTO_01: 8 SCR
 SG_ XCP_SCR_DTO_01_Data : 0|64@1+ (1,0) [0|1] ""  Vector__XXX

BO_ 2617202176 XCP_STH_CRO_01: 8 Vector__XXX
 SG_ XCP_STH_CRO_01_Data : 0|64@1+ (1,0) [0|1] ""  STH_MLBevo

BO_ 2617202177 XCP_STH_DTO_01: 8 STH_MLBevo
 SG_ XCP_STH_DTO_01_Data : 0|64@1+ (1,0) [0|1] ""  Vector__XXX

BO_ 2617005824 XCP_SWA_2_CRO_01: 8 Vector__XXX
 SG_ XCP_SWA_2_CRO_01_Data : 0|64@1+ (1,0) [0|1] ""  MRR_HL

BO_ 2617005825 XCP_SWA_2_DTO_01: 8 MRR_HL
 SG_ XCP_SWA_2_DTO_01_Data : 0|64@1+ (1,0) [0|1] ""  Vector__XXX

BO_ 2617144832 XCP_SWA_CRO_01: 8 Vector__XXX
 SG_ XCP_SWA_CRO_01_Data : 0|64@1+ (1,0) [0|1] ""  MRR_HR

BO_ 2617144833 XCP_SWA_DTO_01: 8 MRR_HR
 SG_ XCP_SWA_DTO_01_Data : 0|64@1+ (1,0) [0|1] ""  Vector__XXX

BO_ 1411 ZV_02: 8 Gateway
 SG_ BCM_FH_Freigabe : 12|1@1+ (1.0,0.0) [0.0|1] ""  Vector__XXX
 SG_ BCM_Komfortfkt_Freigabe : 13|1@1+ (1.0,0.0) [0.0|1] ""  Vector__XXX
 SG_ BCM_HSK_Freigabe : 14|1@1+ (1.0,0.0) [0.0|1] ""  Vector__XXX
 SG_ BCM_Verdeck_Freigabe : 15|1@1+ (1.0,0.0) [0.0|1] ""  Vector__XXX
 SG_ ZV_verriegelt_intern_ist : 16|1@1+ (1.0,0.0) [0.0|1] ""  Vector__XXX
 SG_ ZV_verriegelt_extern_ist : 17|1@1+ (1.0,0.0) [0.0|1] ""  Vector__XXX
 SG_ ZV_verriegelt_intern_soll : 18|1@1+ (1.0,0.0) [0.0|1] ""  Vector__XXX
 SG_ ZV_verriegelt_extern_soll : 19|1@1+ (1.0,0.0) [0.0|1] ""  MRR_HL,MRR_HR
 SG_ ZV_gesafet_extern_ist : 20|1@1+ (1.0,0.0) [0.0|1] ""  Vector__XXX
 SG_ ZV_gesafet_extern_soll : 21|1@1+ (1.0,0.0) [0.0|1] ""  Vector__XXX
 SG_ ZV_Einzeltuerentriegelung : 22|1@1+ (1.0,0.0) [0.0|1] ""  Vector__XXX
 SG_ ZV_Heckeinzelentriegelung : 23|1@1+ (1.0,0.0) [0.0|1] ""  Vector__XXX
 SG_ ZV_FT_offen : 24|1@1+ (1.0,0.0) [0.0|1] ""  TopView
 SG_ ZV_BT_offen : 25|1@1+ (1.0,0.0) [0.0|1] ""  TopView
 SG_ ZV_HFS_offen : 26|1@1+ (1.0,0.0) [0.0|1] ""  Vector__XXX
 SG_ ZV_HBFS_offen : 27|1@1+ (1.0,0.0) [0.0|1] ""  Vector__XXX
 SG_ ZV_HD_offen : 28|1@1+ (1.0,0.0) [0.0|1] ""  TopView
 SG_ ZV_HS_offen : 29|1@1+ (1.0,0.0) [0.0|1] ""  Vector__XXX
 SG_ IRUE_aktiv : 30|1@1+ (1.0,0.0) [0.0|1] ""  Vector__XXX
 SG_ DWA_aktiv : 31|1@1+ (1.0,0.0) [0.0|1] ""  Vector__XXX
 SG_ HD_Hauptraste : 32|1@1+ (1.0,0.0) [0.0|1] ""  Vector__XXX
 SG_ HD_Vorraste : 33|1@1+ (1.0,0.0) [0.0|1] ""  Vector__XXX
 SG_ FFB_CarFinder : 38|1@1+ (1.0,0.0) [0.0|1] ""  Vector__XXX
 SG_ FFB_Komfortoeffnen : 39|1@1+ (1.0,0.0) [0.0|1] ""  Vector__XXX
 SG_ FFB_Komfortschliessen : 40|1@1+ (1.0,0.0) [0.0|1] ""  Vector__XXX
 SG_ ZV_Schluessel_Zugang : 42|4@1+ (1.0,0.0) [0.0|15] ""  MRR_HR
 SG_ ZV_SafeFunktion_aktiv : 46|1@1+ (1.0,0.0) [0.0|1] ""  Vector__XXX
 SG_ FBS_Warn_Schluessel_Batt : 47|1@1+ (1.0,0.0) [0.0|1] ""  Vector__XXX
 SG_ ZV_Oeffnungsmodus : 48|2@1+ (1.0,0.0) [0.0|3] ""  Vector__XXX
 SG_ HFS_verriegelt : 50|1@1+ (1.0,0.0) [0.0|1] ""  Vector__XXX
 SG_ HFS_gesafet : 51|1@1+ (1.0,0.0) [0.0|1] ""  Vector__XXX
 SG_ HBFS_verriegelt : 52|1@1+ (1.0,0.0) [0.0|1] ""  Vector__XXX
 SG_ HBFS_gesafet : 53|1@1+ (1.0,0.0) [0.0|1] ""  Vector__XXX
 SG_ ZV_ist_Zustand_verfuegbar : 54|1@1+ (1.0,0.0) [0.0|1] ""  Vector__XXX
 SG_ IRUE_Taster_Fkts_LED : 55|1@1+ (1.0,0.0) [0.0|1] ""  Vector__XXX
 SG_ ZV_Tankklappe_offen : 56|1@1+ (1.0,0.0) [0.0|1] ""  Vector__XXX
 SG_ ZV_Rollo_auf : 57|1@1+ (1.0,0.0) [0.0|1] ""  Vector__XXX
 SG_ ZV_Rollo_zu : 58|1@1+ (1.0,0.0) [0.0|1] ""  Vector__XXX
 SG_ ZV_SAD_auf : 59|1@1+ (1.0,0.0) [0.0|1] ""  Vector__XXX
 SG_ ZV_SAD_zu : 60|1@1+ (1.0,0.0) [0.0|1] ""  Vector__XXX
 SG_ BCM_Tankklappensteller_Fehler : 61|1@1+ (1.0,0.0) [0.0|1] ""  Vector__XXX
 SG_ ZV_verriegelt_soll : 62|2@1+ (1.0,0.0) [0.0|3] ""  Vector__XXX

BO_TX_BU_ 977 :Gateway,Gateway_PAG;
BO_TX_BU_ 976 :Gateway,Gateway_PAG;
BO_TX_BU_ 997 :Gateway,Gateway_PAG;
BO_TX_BU_ 975 :Gateway,Gateway_PAG;
BO_TX_BU_ 974 :Gateway,Gateway_PAG;
BO_TX_BU_ 618 :Gateway,Gateway_PAG;
BO_TX_BU_ 2463978633 :Gateway,Gateway_PAG;
BO_TX_BU_ 2463978634 :Gateway,Gateway_PAG;
BO_TX_BU_ 995 :Gateway,Gateway_PAG;
BO_TX_BU_ 1716 :Gateway,Gateway_PAG;
BO_TX_BU_ 1702 :Gateway,Gateway_PAG;
BO_TX_BU_ 1411 :Gateway,Gateway_PAG;
CM_ BO_ 977 "ab MQB 7.05";
CM_ BO_ 976 "ab MQB 7.05";
CM_ BO_ 995 "ab MQB IS5";
CM_ BO_ 1716 "200ms bei D4 und folgende";
CM_ BO_ 1702 "MLBevo";

CM_ SG_ 977 ASW_Warnung_aktiv_BFS "Abschaltung der Ambientefunktion Beifahrertür bei aktiver ASW Warnung an der Fahrertür";
CM_ SG_ 977 BFS_Status_eTAG "Status des elektrischen Tueraussengriffes Beifahrertuer";
CM_ SG_ 977 BT_ASW_HMI_defekt "Zeigt an, ob die ASW-Anzeige defekt ist.";
CM_ SG_ 977 BT_EC_Spiegel_Helligkeit "Dimmung für den Aussenspiegel in %";
CM_ SG_ 977 BT_FH_Bew_hoch "Fensterheber in Bewegung Richtung hoch";
CM_ SG_ 977 BT_FH_Bew_tief "Fensterheber in Bewegung Richtung tief";
CM_ SG_ 977 BT_FH_Block "Fensterscheibe befindet sich im mechanischen Block (oben oder unten)";
CM_ SG_ 977 BT_FH_Fang "Fangbereich ist 4mm von oberer Lippendichtung";
CM_ SG_ 977 BT_FH_normiert "Die Position der Fensterheberscheibe ist bekannt";
CM_ SG_ 977 BT_FH_Oeffnung "Gibt den Fensteröffnungswert in % an.";
CM_ SG_ 977 BT_FH_S_AutoHoch "FH Schalter automatisch hoch gedrückt";
CM_ SG_ 977 BT_FH_S_AutoTief "FH Schalter automatisch tief gedrückt";
CM_ SG_ 977 BT_FH_S_ManHoch "FH Schalter manuell hoch gedrückt";
CM_ SG_ 977 BT_FH_S_ManTief "FH Schalter manuell tief gedrückt";
CM_ SG_ 977 BT_FH_Thermo "gibt an ob Fensterheber im Thermoschutz ist";
CM_ SG_ 977 BT_gesafet "Im Zustand Safe wird auch das Signal BT_verriegelt = 1 gesendet";
CM_ SG_ 977 BT_Kisi_Fehler "Fehlerstatus Kindersicherungsfunktion";
CM_ SG_ 977 BT_Lock_Taster "Verriegelungstaster";
CM_ SG_ 977 BT_Lock_Taster_inv "Lock Taster nicht betätigt";
CM_ SG_ 977 BT_Oben_Block_erw "Fensterheber in Blockerwartung oben";
CM_ SG_ 977 BT_Schluesselschalter_auf "Schlüsselschalter Richtung auf betätigt";
CM_ SG_ 977 BT_Schluesselschalter_zu "Schluesselschalter Richtung zu betaetigt";
CM_ SG_ 977 BT_Schluesselschalter_zu_inv "Schluesselschalter zu nicht betaetigt";
CM_ SG_ 977 BT_SP_ausgerastet "Spiegel ausgerastet";
CM_ SG_ 977 BT_Sp_Blk_def "Blinker am Spiegel defekt";
CM_ SG_ 977 BT_Sp_Heizung_Anf "Kundenanforderung der Außenspiegelheizung Beifahrertür";
CM_ SG_ 977 BT_SP_Heizung_Status "Status der Spiegelheizung";
CM_ SG_ 977 BT_SP_ht_aktiv "Spiegelverstellung in Richtung hoch/tief aktiv";
CM_ SG_ 977 BT_SP_lr_aktiv "Spiegelverstellung in Richtung links/rechts aktiv";
CM_ SG_ 977 BT_Sperrklinke "Vorraste für Schloß

zwischen Vor- und Hauptraste Signal kurz auf 1, danach wieder auf 0 wenn Tür in Hauptraste (Tür ist sicher zu wenn Sperrklinke und Türkontakt auf 0 sind)";
CM_ SG_ 977 BT_SWA_HMI_defekt "Zeigt an, ob die SWA-Anzeige defekt ist.";
CM_ SG_ 977 BT_TAG_betaetigt "Türaussengriff";
CM_ SG_ 977 BT_TCR_Mode_aktiv "Signal zeigt eine aktive mechanische Redundanz am Türschloss an.";
CM_ SG_ 977 BT_TIG_betaetigt "Türinnengriff";
CM_ SG_ 977 BT_Tuer_geoeffnet "Zeigt eine geöffnete Tür an";
CM_ SG_ 977 BT_Tuer_Status "Türstatus mit Fehler und Initwert";
CM_ SG_ 977 BT_Tuer_Status_QBit "Dieses Bit gibt die Zuverlässigkeit des Türkontakts an. Ein auf dieses Bit folgender Fehlereintrag ist mit dem Sender des Bits abzustimmen (gültig ab PPE).";
CM_ SG_ 977 BT_Tueroeffnen_Warnung "Bit wird gesetzt, wenn Tür während der Fahrt geoeffnet werden soll.";
CM_ SG_ 977 BT_Tuerschloss_defekt "Das Beifahrertürschloss ist nicht mehr funktionsfähig.";
CM_ SG_ 977 BT_UEKB_aktiviert "Überschutzbegrenzungskraft bei Reversieren";
CM_ SG_ 977 BT_Unlock_Taster "Entriegelungstaster betätigt";
CM_ SG_ 977 BT_Unten_Block_erw "Fensterheber in Blockerwartung unten";
CM_ SG_ 977 BT_verriegelt "Zeigt eine verriegelte Tür an ( Status wird erst nach vollständiger Schlossansteuerung ausgegeben (<=1,5sek))";
CM_ SG_ 977 BT_Zuziehhilfe_aktiv "Zuziehhilfe aktiv";

CM_ SG_ 976 ASW_HMI_defekt "HMI Status der Funktion AusstiegsWarnung (ASW). HMI wird durch das TSG angesteuert.";
CM_ SG_ 976 ASW_wakeup "Trigger Start Nachlaufzeit t_1 für die Funktion Ausstieswarnung (ASW)";
CM_ SG_ 976 ASW_Warnung_aktiv_FS "Abschaltung der Ambientefunktion Fahrertür bei aktiver ASW Warnung an der Fahrertür";
CM_ SG_ 976 FS_Status_eTAG "Status des elektrischen Tueraussengriffes Fahrertuer";
CM_ SG_ 976 FT_BFS_Fond_Freigabe "Freigabe für Fondverstellung";
CM_ SG_ 976 FT_Daemmglas "Daemmglas verbaut";
CM_ SG_ 976 FT_FH_Bew_hoch "Fensterheber in Bewegung Richtung hoch";
CM_ SG_ 976 FT_FH_Bew_tief "Fensterheber in Bewegung Richtung tief";
CM_ SG_ 976 FT_FH_Block "Fensterscheibe befindet sich im mechanischen Block (oben oder unten)";
CM_ SG_ 976 FT_FH_Fang "Fangbereich ist 4mm von oberer Lippendichtung";
CM_ SG_ 976 FT_FH_normiert "Die Position der Fensterheberscheibe ist bekannt";
CM_ SG_ 976 FT_FH_Oeffnung "Gibt den Fensteröffnungswert in % an.";
CM_ SG_ 976 FT_FH_S_AutoHoch "FH Schalter automatisch hoch gedrückt";
CM_ SG_ 976 FT_FH_S_AutoTief "FH Schalter automatisch tief gedrückt";
CM_ SG_ 976 FT_FH_S_ManHoch "FH Schalter manuell hoch gedrückt";
CM_ SG_ 976 FT_FH_S_ManTief "FH Schalter manuell tief gedrückt";
CM_ SG_ 976 FT_FH_Thermo "gibt an ob Fensterheber im Thermoschutz ist";
CM_ SG_ 976 FT_gesafet "Im Zustand Safe wird auch das Signal FT_verriegelt = 1 gesendet";
CM_ SG_ 976 FT_HD_Taste "Taste in der Fahrertür zum Öffnen des Heckschlosses";
CM_ SG_ 976 FT_HD_Taste_2 "2. HD-Taste im Bedienfeld 
Funktion: Heckdeckel schließen";
CM_ SG_ 976 FT_IRUE_Taste "Betätigung IRUE-Taster (Innenraumüberwachung)
MQB: Bei Verbau eines einzelnen Taster zur Deaktivierung von IRUE und NGS wird dieses Signal als Deaktivierungsanforderung beider DWA-Alarmquellen gesendet.";
CM_ SG_ 976 FT_Kisi_Fehler "Fehlerstatus Kindersicherungsfunktion";
CM_ SG_ 976 FT_Kisi_li_aktiv "Aktivierungsstatus der Kindersicherung links";
CM_ SG_ 976 FT_Kisi_re_aktiv "Aktivierungsstatus der Kindersicherung rechts";
CM_ SG_ 976 FT_Kisi_Taster_li "Linker Kisi Taster betaetigt";
CM_ SG_ 976 FT_Kisi_Taster_re "Rechter Kisi Taster betaetigt";
CM_ SG_ 976 FT_Lock_Taster "Verriegelungstaster betätigt";
CM_ SG_ 976 FT_Oben_Block_erw "Fensterheber in Blockerwartung oben";
CM_ SG_ 976 FT_Schliesstaster "Vorhalt";
CM_ SG_ 976 FT_Schluesselschalter_auf "Schlüsselschalter Richtung auf betätigt";
CM_ SG_ 976 FT_SP_ausgerastet "Spiegel ausgerastet";
CM_ SG_ 976 FT_Sp_Blk_def "Blinker am Spiegel defekt";
CM_ SG_ 976 FT_Sp_Heizung_Anf "Kundenanforderung der Außenspiegelheizung Fahrertür";
CM_ SG_ 976 FT_SP_Heizung_Status "Status der Spiegelheizung";
CM_ SG_ 976 FT_SP_ht_aktiv "Spiegelverstellung in Richtung hoch/tief aktiv";
CM_ SG_ 976 FT_SP_lr_aktiv "Spiegelverstellung in Richtung links/rechts aktiv";
CM_ SG_ 976 FT_Sperrklinke "Vorraste für Schloß

zwischen Vor- und Hauptraste Signal kurz auf 1, danach wieder auf 0 wenn Tür in Hauptraste (Tür ist sicher zu wenn Sperrklinke und Türkontakt auf 0 sind)";
CM_ SG_ 976 FT_SWA_Taster "SWA/ASW Taster Fahrertür";
CM_ SG_ 976 FT_TAG_betaetigt "Türaussengriff

wird nicht im MLB-B8 verwendet";
CM_ SG_ 976 FT_TD_Taste "Tankdeckelentriegelungs-Taste betätigt";
CM_ SG_ 976 FT_TD_Taste_Fehler "Fehlerstatus des Tankdeckelentriegelungstasters. Wird bei Drucktankkonzepten vom MSG zusammen mit dem Signal FT_TD_Taste ausgewertet, um Tankbereitschaft herzustellen.
Der Fehler beschreibt einen hängenden TD_Taster. Ein Kurzschluss oder Leitungsunterbre";
CM_ SG_ 976 FT_TIG_betaetigt "Türinnengriff

wird nicht im MLB-B8 verwendet";
CM_ SG_ 976 FT_Tuer_geoeffnet "Zeigt eine geöffnete Tür an";
CM_ SG_ 976 FT_Tuerschloss_defekt "Das Fahrertürschloss ist nicht mehr funktionsfähig.";
CM_ SG_ 976 FT_UEKB_aktiviert "Überschutzbegrenzungskraft bei Reversieren";
CM_ SG_ 976 FT_Unlock_Taster "Entriegelungstaster betätigt";
CM_ SG_ 976 FT_Unten_Block_erw "Fensterheber in Blockerwartung unten";
CM_ SG_ 976 FT_verriegelt "Zeigt eine verriegelte Tür an ( Status wird erst nach vollständiger Schlossansteuerung ausgegeben (<=1,5sek))";
CM_ SG_ 976 FT_Zuziehhilfe_aktiv "Zuziehhilfe aktiv";
CM_ SG_ 976 SSR_Temp_Freigabe "Freigabe des Seitenscheibenrollos. Bit wird  für die Deaktivierung des SSR bei Innenraumtemperaturen kleiner -10 Grad verwendet.";
CM_ SG_ 976 SWA_HMI_Diagnose "SWA HMI Diagnose beim TSG";

CM_ SG_ 997 FS_Push_Tuergriff "Push zum Ausfahren der Flush-Tuergriffe";
CM_ SG_ 997 FT_BFS_Tuer_Status "Gesammelte Türstatusbotschaft";
CM_ SG_ 997 FT_HBFS_Tuer_Status "Türstatus mit Fehler und Initwert";
CM_ SG_ 997 FT_HFS_Tuer_Status "Türstatus mit Fehler und Initwert";
CM_ SG_ 997 FT_Kisi_Taster_li_02 "Der Kindersicherungstaster hinten links aktiv.";
CM_ SG_ 997 FT_Kisi_Taster_re_02 "Der Kindersicherungstaster hinten rechts aktiv.";
CM_ SG_ 997 FT_Lock_Taster_02 "Lock-Taster betätigt";
CM_ SG_ 997 FT_Schluesselschalter_zu_02 "Schlüsselschalter für Schließen betätigt";
CM_ SG_ 997 FT_SP_Heizung_ein "Dieses Signal zeigt die tatsächliche Ansteuerung der  Spiegelheizung incl. PWM an. 
Zudem wird aufgrund des Teilnetzbetriebs das Signal zur Ansteuerung der Beifahrer-Spiegelheizung benutzt.

";
CM_ SG_ 997 FT_TCR_Mode_aktiv "Signal zeigt eine aktive mechanische Redundanz am Türschloss an.";
CM_ SG_ 997 FT_TD_Taste_Status "Status Taste für Tankdeckel";
CM_ SG_ 997 FT_Tuer_Status "Tür geöffnet oder Tür geschlossen";
CM_ SG_ 997 FT_Tuer_Status_QBit "Dieses Bit gibt die Zuverlässigkeit des Türkontakts an.";
CM_ SG_ 997 FT_Tueroeffnen_Warnung "Bit wird gesetzt, wenn Tür während der Fahrt geoeffnet werden soll.";
CM_ SG_ 997 TSG_FT_02_BZ "4bit Botschaftszaehler, wird mit jeder Sendebotschaft inkrementiert";
CM_ SG_ 997 TSG_FT_02_CRC "Für MLB:
'Berechnung siehe Lastenheft 'Kommunikationsabsicherung für FlexRay und CAN''

Ab MQB und MLBevo:
'Berechnung siehe Lastenheft 'End-to-End Kommunikationsabsicherung''

Endwerte siehe Begleitdokument 'S-PDU Kennungsfolgen'";

CM_ SG_ 975 ASW_Warnung_aktiv_HBFS "Abschaltung der Ambientefunktion Tür hinten der Beifahrerseite bei aktiver ASW Warnung an der Fahrertür";
CM_ SG_ 975 HBFS_FH_Bew_hoch "HBFS Fenster bewegt sich in Richtung hoch";
CM_ SG_ 975 HBFS_FH_Bew_tief "HBFS Fenster bewegt sich in Richtung tief";
CM_ SG_ 975 HBFS_FH_Block "Fensterscheibe befindet sich im mechanischen Block (oben oder unten)";
CM_ SG_ 975 HBFS_FH_Fang "Fangbereich ist 4mm von oberer Lippendichtung";
CM_ SG_ 975 HBFS_FH_normiert "Die Position der Fensterheberscheibe ist bekannt.";
CM_ SG_ 975 HBFS_FH_Oeffnung "Gibt den Fensteröffnungswert in % an.";
CM_ SG_ 975 HBFS_FH_S_AutoHoch "Betaetigung FH Schalter auto tief ";
CM_ SG_ 975 HBFS_FH_S_AutoTief "Betaetigung FH Schalter auto hoch";
CM_ SG_ 975 HBFS_FH_S_HFS_AutoHoch "Automatisches Hochfahren der Seitenscheibe HFS";
CM_ SG_ 975 HBFS_FH_S_HFS_AutoTief "Automatisches Absenken der Seitenscheibe HFS";
CM_ SG_ 975 HBFS_FH_S_HFS_ManHoch "Manuelles Hochfahren der Seitenscheibe HFS";
CM_ SG_ 975 HBFS_FH_S_HFS_ManTief "Manuelles Absenken der Seitenscheibe HFS";
CM_ SG_ 975 HBFS_FH_S_ManHoch "Betaetigung FH Schalter man hoch ";
CM_ SG_ 975 HBFS_FH_S_ManTief "Betaetigung FH Schalter man tief";
CM_ SG_ 975 HBFS_FH_Thermo "gibt an ob Fensterheber im Thermoschutz ist";
CM_ SG_ 975 HBFS_gesafet "HBFS Tuer gesafet.
Im Zustand Safe wird auch das Signal HBFS_verriegelt = 1 gesendet.";
CM_ SG_ 975 HBFS_Heckrollotaster_betaetigt "Verfahren des Heckrollos in Richtung Hoch

Bei Einfachtaster wird Bit als Togglebit verwendet (Heckrollo hoch, tief)";
CM_ SG_ 975 HBFS_Lock_Taster "Betaetigung Lock-Taster";
CM_ SG_ 975 HBFS_Lock_Taster_inv "Lock Taster nicht betätigt";
CM_ SG_ 975 HBFS_MRollo_Schalter "  | MRollo2
-----------------------------
0 | nicht_betaetigt
1 | (m) Zu
2 | (a) Zu
3 | (m) Auf
4 | (a) Auf
5 | Schalter nicht verfuegbar
6 | Init
7 | Fehlerfall";
CM_ SG_ 975 HBFS_Oben_Block_erw "Fensterheber in Blockerwartung oben";
CM_ SG_ 975 HBFS_SAD_Schalter "  |   Ausstelldach MD3
-----------------------------
0 | nicht_betaetigt
1 |
2 |
3 |
4 |
5 | (m) Auf
6 | (a) Auf
7 | (m) Zu
8 | (a) Zu
13| Schalter nicht verfuegbar
14| Init
15| Fehlerfall";
CM_ SG_ 975 HBFS_Seitenrollo_tief "Seitenrollo in Bewegung Richtung tief";
CM_ SG_ 975 HBFS_Sperrklinke "Vorraste für Schloß

zwischen Vor- und Hauptraste Signal kurz auf 1, danach wieder auf 0 wenn Tür in Hauptraste (Tür ist sicher zu wenn Sperrklinke und Türkontakt auf 0 sind)";
CM_ SG_ 975 HBFS_Status_eTAG "Status des elektrischen Tueraussengriffes Tuer Beifahrerseite hinten";
CM_ SG_ 975 HBFS_Status_KiSi "Status Kindersicherung HBFS
";
CM_ SG_ 975 HBFS_Status_KiSi_inv "Inverser Status der elektrischen Kindersicherung Beifahrerseite hinten";
CM_ SG_ 975 HBFS_TAG_betaetigt "Betaetigung Türaussengriff";
CM_ SG_ 975 HBFS_TIG_betaetigt "Betaetigung Tuerinnengriff";
CM_ SG_ 975 HBFS_TIG_betaetigt_schliessen "Türinnenbetätigung, Taster Tür schließen.";
CM_ SG_ 975 HBFS_Tuer_geoeffnet "HBFS Tuer geoeffnet";
CM_ SG_ 975 HBFS_Tuer_Status "Türstatus mit Fehler und Initwert";
CM_ SG_ 975 HBFS_Tuer_Status_QBit "Dieses Bit gibt die Zuverlässigkeit des Türkontakts an. Ein auf dieses Bit folgender Fehlereintrag ist mit dem Sender des Bits abzustimmen (gültig ab PPE).";
CM_ SG_ 975 HBFS_Tueroeffnen_Warnung "Bit wird gesetzt, wenn Tür während der Fahrt geoeffnet werden soll.";
CM_ SG_ 975 HBFS_Tuerschloss_defekt "Das hintere Tuerschloss auf der Beifahrerseite ist nicht mehr funktionsfähig.";
CM_ SG_ 975 HBFS_UEKB_aktiviert "Überschutzbegrenzungskraft bei Reversieren";
CM_ SG_ 975 HBFS_Unlock_Taster "Betaetigung Unlock Taster";
CM_ SG_ 975 HBFS_Unten_Block_erw "Fensterheber in Blockerwartung unten";
CM_ SG_ 975 HBFS_verriegelt "Verriegelungsstatus Tür";
CM_ SG_ 975 HBFS_Zuziehhilfe_aktiv "Zuziehhilfe aktiv";
CM_ SG_ 975 MTHBFS_M_Taste "Betätigung M-Taste HBFS";
CM_ SG_ 975 MTHBFS_Pos1 "Betätigung Postionstaste 1 HBFS";
CM_ SG_ 975 MTHBFS_Pos2 "Betätigung Postionstaste 2 HBFS
";
CM_ SG_ 975 MTHBFS_Pos3 "Betätigung Postionstaste 3 HBFS";
CM_ SG_ 975 SSR_HBFS_Pos_Unten "Signal für die 'Global Close'. Über dieses Bit wissen die anderen TSGs, ob der SSR oder der FH verfahren werden darf.";

CM_ SG_ 974 ASW_Warnung_aktiv_HFS "Abschaltung der Ambientefunktion Tür hinten der Fahrerseite bei aktiver ASW Warnung an der Fahrertür";
CM_ SG_ 974 HFS_FH_Bew_hoch "HFS Fenster bewegt sich in Richtung hoch";
CM_ SG_ 974 HFS_FH_Bew_tief "HFS Fenster bewegt sich in Richtung tief";
CM_ SG_ 974 HFS_FH_Block "Fensterscheibe befindet sich im mechanischen Block (oben oder unten)";
CM_ SG_ 974 HFS_FH_Fang "Fangbereich ist 4mm von oberer Lippendichtung";
CM_ SG_ 974 HFS_FH_normiert "Die Position der Fensterheberscheibe ist bekannt.";
CM_ SG_ 974 HFS_FH_Oeffnung "Gibt den Fensteröffnungswert in % an.";
CM_ SG_ 974 HFS_FH_S_AutoHoch "Betaetigung FH Schalter auto hoch";
CM_ SG_ 974 HFS_FH_S_AutoTief "Betaetigung FH Schalter auto tief ";
CM_ SG_ 974 HFS_FH_S_HBFS_AutoHoch "Automatisches Hochfahren der Seitenscheibe HBFS";
CM_ SG_ 974 HFS_FH_S_HBFS_AutoTief "Automatisches Absenken der Seitenscheibe HBFS";
CM_ SG_ 974 HFS_FH_S_HBFS_ManHoch "Manuelles Hochfahren der Seitenscheibe HBFS";
CM_ SG_ 974 HFS_FH_S_HBFS_ManTief "Manuelles Absenken der Seitenscheibe HBFS";
CM_ SG_ 974 HFS_FH_S_ManHoch "Betaetigung FH Schalter man hoch ";
CM_ SG_ 974 HFS_FH_S_ManTief "Betaetigung FH Schalter man tief";
CM_ SG_ 974 HFS_FH_Thermo "gibt an ob Fensterheber im Thermoschutz ist";
CM_ SG_ 974 HFS_gesafet "HFS Tuer gesafet.
Im Zustand Safe wird auch das Signal HFS_verriegelt = 1 gesendet.";
CM_ SG_ 974 HFS_Heckrollotaster_betaetigt "Verfahren des Heckrollos in Richtung Hoch

Bei Einfachtaster wird Bit als Togglebit verwendet (Heckrollo hoch, tief)";
CM_ SG_ 974 HFS_Lock_Taster "Betätigung Lock-Taster";
CM_ SG_ 974 HFS_Lock_Taster_inv "Lock Taster nicht betätigt";
CM_ SG_ 974 HFS_MRollo_Schalter "  | MRollo2
-----------------------------
0 | nicht_betaetigt
1 | (m) Zu
2 | (a) Zu
3 | (m) Auf
4 | (a) Auf
5 | Schalter nicht verfuegbar
6 | Init
7 | Fehlerfall";
CM_ SG_ 974 HFS_Oben_Block_erw "Fensterheber in Blockerwartung oben";
CM_ SG_ 974 HFS_SAD_Schalter "  |   Ausstelldach MD3
-----------------------------
0 | nicht_betaetigt
1 |
2 |
3 |
4 |
5 | (m) Auf
6 | (a) Auf
7 | (m) Zu
8 | (a) Zu
13| Schalter nicht verfuegbar
14| Init
15| Fehlerfall";
CM_ SG_ 974 HFS_Seitenrollo_hoch "Seitenrollo in Bewegung Richtung hoch";
CM_ SG_ 974 HFS_Seitenrollo_tief "Seitenrollo in Bewegung Richtung tief";
CM_ SG_ 974 HFS_Sperrklinke "Vorraste für Schloß

zwischen Vor- und Hauptraste Signal kurz auf 1, danach wieder auf 0 wenn Tür in Hauptraste (Tür ist sicher zu wenn Sperrklinke und Türkontakt auf 0 sind)";
CM_ SG_ 974 HFS_Status_eTAG "Status des elektrischen Tueraussengriffes Tuer Fahrerseite hinten";
CM_ SG_ 974 HFS_Status_KiSi "Status Kindersicherung hinten Fahrerseite";
CM_ SG_ 974 HFS_TAG_betaetigt "Betaetigung Türaussengriff";
CM_ SG_ 974 HFS_TCR_Mode_aktiv "Signal zeigt eine aktive mechanische Redundanz am Türschloss an.";
CM_ SG_ 974 HFS_TIG_betaetigt "Betaetigung Türinnengriff";
CM_ SG_ 974 HFS_Tuer_geoeffnet "HFS Tuer geoeffnet";
CM_ SG_ 974 HFS_Tuer_Status "Türstatus mit Fehler und Initwert";
CM_ SG_ 974 HFS_Tuer_Status_QBit "Dieses Bit gibt die Zuverlässigkeit des Türkontakts an. Ein auf dieses Bit folgender Fehlereintrag ist mit dem Sender des Bits abzustimmen (gültig ab PPE).";
CM_ SG_ 974 HFS_Tueroeffnen_Warnung "Bit wird gesetzt, wenn Tür während der Fahrt geoeffnet werden soll.";
CM_ SG_ 974 HFS_Tuerschloss_defekt "Das hintere Tuerschloss auf der Fahrerseite ist nicht mehr funktionsfähig.";
CM_ SG_ 974 HFS_UEKB_aktiviert "Überschutzbegrenzungskraft bei Reversieren";
CM_ SG_ 974 HFS_Unlock_Taster "Betaetigung Unlock Taster";
CM_ SG_ 974 HFS_Unten_Block_erw "Fensterheber in Blockerwartung unten";
CM_ SG_ 974 HFS_verriegelt "HFS Tuer verriegelt";
CM_ SG_ 974 HFS_Zuziehhilfe_aktiv "Zuziehhilfe aktiv";
CM_ SG_ 974 MTHFS_M_Taste "Betätigung M-Taste HFS";
CM_ SG_ 974 MTHFS_Pos1 "Betätigung Postionstaste 1 HFS";
CM_ SG_ 974 MTHFS_Pos2 "Betätigung Postionstaste 2 HFS
";
CM_ SG_ 974 MTHFS_Pos3 "Betätigung Postionstaste 3 HFS";
CM_ SG_ 974 SSR_HFS_Pos_Unten "Signal für die 'Global Close'. Über dieses Bit wissen die anderen TSGs, ob der SSR oder der FH verfahren werden darf.";

CM_ SG_ 618 USS_Fahrer_Texte "Textdefinitionen";
CM_ SG_ 618 USS_Fahrzeit_seit_Pause "Fahrzeit seit Pause";
CM_ SG_ 618 USS_MKE_Index "Aktuell abgeschätzter Wert Fahrerzustand. 0 - 10 mit Auflösung 1/10.";
CM_ SG_ 618 USS_MKE_Index_Anstieg "Anstieg des Indexwertes";
CM_ SG_ 618 USS_MKE_Index_Quelle_Biometrisch "Verwendung von einer biometrischen Quelle für die Berechnung MKE Index";
CM_ SG_ 618 USS_MKE_Index_Quelle_FBK "Verwendung FBK für Berechnung MKE Index (kMKE)";
CM_ SG_ 618 USS_MKE_Index_Quelle_LWS_Basis "Verwendung LWS Basis für Berechnung MKE Index";
CM_ SG_ 618 USS_MKE_Index_Quelle_LWS_Plus "Verwendung LWS Plus für Berechnung MKE Index";
CM_ SG_ 618 USS_MKE_Index_Quelle_MFK "Verwendung MFK für Berechnung MKE Index";
CM_ SG_ 618 USS_MKE_Risiko "MKE-Risikoeinschätzung des Fahrers.";

CM_ SG_ 2463978633 VAS_L_01_BZ "4bit Botschaftszähler, wird mit jeder Sendebotschaft inkrementiert";
CM_ SG_ 2463978633 VAS_L_01_CRC "Für MLB:
Berechnung siehe Lastenheft 'Kommunikationsabsicherung für FlexRay und CAN'
Ab MQB und MLBevo:
Berechnung siehe Lastenheft 'End-to-End Kommunikationsabsicherung'

Endwerte siehe Begleitdokument 'S-PDU Kennungsfolgen'";
CM_ SG_ 2463978633 VAS_L_Autobahnview_aktiv "Status ob Autobahnview aktiv ist oder nicht";
CM_ SG_ 2463978633 VAS_L_Bedien_Master "Gibt an dass das linke Steuergerät Bedien Master ist";
CM_ SG_ 2463978633 VAS_L_Heizung_Aktiv "VAS rechts Heizung aktiv";
CM_ SG_ 2463978633 VAS_L_HMI_Aktiv "Gibt an ob das HMI angezeigt wird";
CM_ SG_ 2463978633 VAS_L_Parkview_aktiv "VAS links Parkview aktiv";
CM_ SG_ 2463978633 VAS_L_Spiegelauswahl "VAS links Spiegelauswahl";
CM_ SG_ 2463978633 VAS_L_SWA_HMI_Diagnose "SWA HMI Diagnose beim VAS";
CM_ SG_ 2463978633 VAS_L_Texte "Signal uebermittelt die Fahrerhinweise zum Kombi muss E2E abgesichert werden";
CM_ SG_ 2463978633 VAS_L_Turnview_aktiv "Status Turnview Anzeige";
CM_ SG_ 2463978633 VAS_L_Verstell_Pos_X "VAS links Spiegel Verstellposition X";
CM_ SG_ 2463978633 VAS_L_Verstell_Pos_Y "VAS links Spiegel Verstellposition Y";
CM_ SG_ 2463978633 VAS_L_Zoom_Level "VAS links Zoom Level Display";

CM_ SG_ 2463978634 VAS_R_01_BZ "4bit Botschaftszähler, wird mit jeder Sendebotschaft inkrementiert";
CM_ SG_ 2463978634 VAS_R_01_CRC "Für MLB:
Berechnung siehe Lastenheft 'Kommunikationsabsicherung für FlexRay und CAN'
Ab MQB und MLBevo:
Berechnung siehe Lastenheft 'End-to-End Kommunikationsabsicherung'

Endwerte siehe Begleitdokument 'S-PDU Kennungsfolgen'";
CM_ SG_ 2463978634 VAS_R_Autobahnview_aktiv "Status der Autobahnview ob aktiv oder deaktiv";
CM_ SG_ 2463978634 VAS_R_Bedien_Master "Gibt an dass das rechte Steuergerät Bedien Master ist";
CM_ SG_ 2463978634 VAS_R_Fahrerwarnung "Signal beinhaltet alle Fahrerwarnungen welche am Kombi angezeigt werden";
CM_ SG_ 2463978634 VAS_R_Heizung_Aktiv "VAS rechts aktive Heizung";
CM_ SG_ 2463978634 VAS_R_HMI_Aktiv "Gibt an ob das HMI angezeigt wird";
CM_ SG_ 2463978634 VAS_R_Parkview_aktiv "VAS rechts Parkview aktiv";
CM_ SG_ 2463978634 VAS_R_Spiegelauswahl "VAS rechts Spiegelauswahl";
CM_ SG_ 2463978634 VAS_R_SWA_HMI_Diagnose "SWA HMI Diagnose beim VAS";
CM_ SG_ 2463978634 VAS_R_Turnview_aktiv "Status Anzeige Turnview des rechten VAS";
CM_ SG_ 2463978634 VAS_R_Verstell_Pos_X "VAS rechts Spiegel Verstellposition X";
CM_ SG_ 2463978634 VAS_R_Verstell_Pos_Y "VAS rechts Spiegel Verstellposition Y";
CM_ SG_ 2463978634 VAS_R_Zoom_Level "VAS rechts Zoom level CMS System";

CM_ SG_ 995 VD_SpannungsAnf "Anforderung Forderung des Verdecks zur Spannungsanhebung des Bordnetzes.";
CM_ SG_ 995 Verdeck_01_BZ "4bit Botschaftszähler, wird mit jeder Sendebotschaft inkrementiert";
CM_ SG_ 995 Verdeck_01_CRC "Für MLB:
Berechnung siehe Lastenheft 'Kommunikationsabsicherung für FlexRay und CAN'
Ab MQB und MLBevo:
Berechnung siehe Lastenheft 'End-to-End Kommunikationsabsicherung'

Endwerte siehe Begleitdokument 'S-PDU Kennungsfolgen'";
CM_ SG_ 995 VS_BFS_AutoHoch "automatischer Hochlauf des BFS Fenster ausgelöst durch die Verdecksteuerung";
CM_ SG_ 995 VS_BFS_AutoTief "automatischer Tieflauf des BFS Fenster ausgelöst durch die Verdecksteuerung";
CM_ SG_ 995 VS_BFS_ManHoch "manueller Hochlauf des BFS Fenster ausgelöst durch die Verdecksteuerung";
CM_ SG_ 995 VS_BFS_ManTief "manueller Tieflauf des BFS Fenster ausgelöst durch die Verdecksteuerung";
CM_ SG_ 995 VS_Buzzer "Buzzeransteuerung: 'Buzzeransteuerung' für Gong 200ms (Kombi)";
CM_ SG_ 995 VS_FH_BT_Langhub "Ansteuerung Fensterheber vom Verdecksteuergeraet";
CM_ SG_ 995 VS_FH_FT_Langhub "Ansteuerung Fensterheber vom Verdecksteuergeraet";
CM_ SG_ 995 VS_FH_HBFS_Langhub "Ansteuerung Fensterheber vom Verdecksteuergeraet";
CM_ SG_ 995 VS_FH_HFS_Langhub "Ansteuerung Fensterheber vom Verdecksteuergeraet";
CM_ SG_ 995 VS_FS_AutoHoch "automatischer Hochlauf des FS Fenster ausgelöst durch die Verdecksteuerung";
CM_ SG_ 995 VS_FS_AutoTief "automatischer Tieflauf des FS Fenster ausgelöst durch die Verdecksteuerung";
CM_ SG_ 995 VS_FS_ManHoch "manueller Hochlauf des FS Fenster ausgelöst durch die Verdecksteuerung";
CM_ SG_ 995 VS_FS_ManTief "manueller Tieflauf des FS Fenster ausgelöst durch die Verdecksteuerung";
CM_ SG_ 995 VS_Hardtop "Hardtop montiert";
CM_ SG_ 995 VS_HBFS_AutoHoch "automatischer Hochlauf des HBFS Fenster ausgelöst durch die Verdecksteuerung";
CM_ SG_ 995 VS_HBFS_AutoTief "automatischer Tieflauf des HBFS Fenster ausgelöst durch die Verdecksteuerung";
CM_ SG_ 995 VS_HBFS_ManHoch "manueller Hochlauf des HBFS Fenster ausgelöst durch die Verdecksteuerung";
CM_ SG_ 995 VS_HBFS_ManTief "manueller Tieflauf des HBFS Fenster ausgelöst durch die Verdecksteuerung";
CM_ SG_ 995 VS_HD_sperren "Bei gesetztem Signal wird der Kofferraum/Heckdeckel durch den BCM2 nicht entriegelt werden.";
CM_ SG_ 995 VS_Heckschloss_auf "Signal wird gesetzt, wenn fuer einen Verdeckbetrieb das Öffnen des Heckschlosses erforderlich ist.";
CM_ SG_ 995 VS_HFS_AutoHoch "automatischer Hochlauf des HFS Fenster ausgelöst durch die Verdecksteuerung";
CM_ SG_ 995 VS_HFS_AutoTief "automatischer Tieflauf des HFS Fenster ausgelöst durch die Verdecksteuerung";
CM_ SG_ 995 VS_HFS_ManHoch "manueller Hochlauf des HFS Fenster ausgelöst durch die Verdecksteuerung";
CM_ SG_ 995 VS_HFS_ManTief "manueller Tieflauf des HFS Fenster ausgelöst durch die Verdecksteuerung";
CM_ SG_ 995 VS_HHS_enable "Fehlende Beschreibung (Import)";
CM_ SG_ 995 VS_Lampe_Blk "Ansteuerung Lampe im Kombi

Wird aktiviert bei Aufprüfen, Verdecklauf und Fehlerfall (blinkend).


";
CM_ SG_ 995 VS_StartStopp_Info "Stopp-Freigabe und Start-Anforderung an den Start-Stopp-Koordinator";
CM_ SG_ 995 VS_VD_Bew_auf "



";
CM_ SG_ 995 VS_VD_Bew_zu "


";
CM_ SG_ 995 VS_VD_entriegelt "Zustand des Verdeck entriegelt";
CM_ SG_ 995 VS_VD_Fehler "Fehlerzustand Verdeck";
CM_ SG_ 995 VS_VD_offen_ver "Zustand des Verdecks verriegelt und offen";
CM_ SG_ 995 VS_VD_zu_ver "
";
CM_ SG_ 995 VS_VD_Zwischenposition "Verdeck in Zwischenposition";
CM_ SG_ 995 VS_VDKD_auf "Signal wird gesetzt, wenn der Verdeckkastendeckel vollstaendig geoeffnet ist



";
CM_ SG_ 995 VS_Verdeck_Anf "Verdeckanforderung (Signalisierung der Bereitschaft zur Verdeckbetaetigung ueber Komfortfunktion)";
CM_ SG_ 995 VS_Windschott_nicht_abgelegt "Windschott ist aufgestellt, in Zwischenposition oder die Position ist unbekannt";
CM_ SG_ 995 VSG_Meldungen "Meldungen fuers Kombi lt. konzernübergreifender Abstimmung

0 -> keine Meldung
1 -> 'Verdeckbetrieb RDW aktiv'
2 -> 'Verdeckbetrieb NAR aktiv'
3 -> 'stehendes Verdeck in Zwischenposition (ZP)'
4 -> 'autom. Verdeck in ZP und KL15 aus'
5 -> 'manuelle";

CM_ SG_ 1716 VIN_01_MUX "Achtung:
Die Botschaft ist nicht linear gemultiplext!!!
Sondern 0,1,0,2,0, usw.";
CM_ SG_ 1716 VIN_1 "Initwert:
0x2D bei Fahrzeugen mit Wegfahrsperrengeneration >= 5 
0x58 bei Fahrzeugen mit Wegfahrsperrengeneration < 5 (z.B. WFS-4)";
CM_ SG_ 1716 VIN_10 "Initwert:
0x2D bei Fahrzeugen mit Wegfahrsperrengeneration >= 5 
0x58 bei Fahrzeugen mit Wegfahrsperrengeneration < 5 (z.B. WFS-4)";
CM_ SG_ 1716 VIN_11 "Initwert:
0x2D bei Fahrzeugen mit Wegfahrsperrengeneration >= 5 
0x58 bei Fahrzeugen mit Wegfahrsperrengeneration < 5 (z.B. WFS-4)";
CM_ SG_ 1716 VIN_12 "Initwert:
0x2D bei Fahrzeugen mit Wegfahrsperrengeneration >= 5 
0x58 bei Fahrzeugen mit Wegfahrsperrengeneration < 5 (z.B. WFS-4)";
CM_ SG_ 1716 VIN_13 "Initwert:
0x2D bei Fahrzeugen mit Wegfahrsperrengeneration >= 5 
0x58 bei Fahrzeugen mit Wegfahrsperrengeneration < 5 (z.B. WFS-4)";
CM_ SG_ 1716 VIN_14 "Initwert:
0x2D bei Fahrzeugen mit Wegfahrsperrengeneration >= 5 
0x58 bei Fahrzeugen mit Wegfahrsperrengeneration < 5 (z.B. WFS-4)";
CM_ SG_ 1716 VIN_15 "Initwert:
0x2D bei Fahrzeugen mit Wegfahrsperrengeneration >= 5 
0x58 bei Fahrzeugen mit Wegfahrsperrengeneration < 5 (z.B. WFS-4)";
CM_ SG_ 1716 VIN_16 "Initwert:
0x2D bei Fahrzeugen mit Wegfahrsperrengeneration >= 5 
0x58 bei Fahrzeugen mit Wegfahrsperrengeneration < 5 (z.B. WFS-4)";
CM_ SG_ 1716 VIN_17 "Initwert:
0x2D bei Fahrzeugen mit Wegfahrsperrengeneration >= 5 
0x58 bei Fahrzeugen mit Wegfahrsperrengeneration < 5 (z.B. WFS-4)";
CM_ SG_ 1716 VIN_2 "Initwert:
0x2D bei Fahrzeugen mit Wegfahrsperrengeneration >= 5 
0x58 bei Fahrzeugen mit Wegfahrsperrengeneration < 5 (z.B. WFS-4)";
CM_ SG_ 1716 VIN_3 "Initwert:
0x2D bei Fahrzeugen mit Wegfahrsperrengeneration >= 5 
0x58 bei Fahrzeugen mit Wegfahrsperrengeneration < 5 (z.B. WFS-4)";
CM_ SG_ 1716 VIN_4 "Initwert:
0x2D bei Fahrzeugen mit Wegfahrsperrengeneration >= 5 
0x58 bei Fahrzeugen mit Wegfahrsperrengeneration < 5 (z.B. WFS-4)";
CM_ SG_ 1716 VIN_5 "Initwert:
0x2D bei Fahrzeugen mit Wegfahrsperrengeneration >= 5 
0x58 bei Fahrzeugen mit Wegfahrsperrengeneration < 5 (z.B. WFS-4)";
CM_ SG_ 1716 VIN_6 "Initwert:
0x2D bei Fahrzeugen mit Wegfahrsperrengeneration >= 5 
0x58 bei Fahrzeugen mit Wegfahrsperrengeneration < 5 (z.B. WFS-4)";
CM_ SG_ 1716 VIN_7 "Initwert:
0x2D bei Fahrzeugen mit Wegfahrsperrengeneration >= 5 
0x58 bei Fahrzeugen mit Wegfahrsperrengeneration < 5 (z.B. WFS-4)";
CM_ SG_ 1716 VIN_8 "Initwert:
0x2D bei Fahrzeugen mit Wegfahrsperrengeneration >= 5 
0x58 bei Fahrzeugen mit Wegfahrsperrengeneration < 5 (z.B. WFS-4)";
CM_ SG_ 1716 VIN_9 "Initwert:
0x2D bei Fahrzeugen mit Wegfahrsperrengeneration >= 5 
0x58 bei Fahrzeugen mit Wegfahrsperrengeneration < 5 (z.B. WFS-4)";

CM_ SG_ 1702 BCM1_SRA_aktiv "Status Scheinwerferreinigungsanlage";
CM_ SG_ 1702 Heckwischer_Anforderung "Das Signal beschreibt die Anforderung an den Signalausgang im BCM2 zur Ansteuerung des Heckwischers.";
CM_ SG_ 1702 Waschen_vorne_aktiv "Status: Waschen vorne aktiv";
CM_ SG_ 1702 Wischer1_Wischgeschwindigkeit "aktuelle, durch Sensorik gemessene Wischgeschwindigkeit";
CM_ SG_ 1702 Wischer_Anzeigetext "Das Signal fordert einen Kombi-Pop-Up mit entsprechenden Texten an";
CM_ SG_ 1702 Wischer_vorne_aktiv "Status: Wischer vorne";
CM_ SG_ 1702 Wischer_vorne_blockiert "Blockade Wischer vorne (z.B. durch Schnee)";
CM_ SG_ 1702 Wischer_vorne_defekt "Fehlerstatus Wischer vorne (Anzeige im Kombi)";
CM_ SG_ 1702 Wischer_vorne_Normal "Wischer Front normal aktiv";
CM_ SG_ 1702 Wischer_vorne_Parklage "Wischer Front in Parklage";
CM_ SG_ 1702 Wischer_vorne_Schnell "Wischer vorne schnell aktiv";
CM_ SG_ 1702 WWSs_01_upd "Update-Bit für die LIN-Botschaft WWSs_01.

Betroffene Signale:

Wischer_vorne_aktiv
Wischer1_Wischgeschwindigkeit";

CM_ SG_ 1411 BCM_FH_Freigabe "Funktionsfreigabe Fensterheber";
CM_ SG_ 1411 BCM_HSK_Freigabe "Handschuhkastenfreigabe";
CM_ SG_ 1411 BCM_Komfortfkt_Freigabe "globale Freigabe der Komfortfunktion";
CM_ SG_ 1411 BCM_Tankklappensteller_Fehler "Fehler: nicht Funktionalität des Tankklappenstellers";
CM_ SG_ 1411 BCM_Verdeck_Freigabe "Freigabe Verdeckbetrieb
";
CM_ SG_ 1411 DWA_aktiv "Status DWA  aktiv";
CM_ SG_ 1411 FBS_Warn_Schluessel_Batt "Kombi Prio Warnung Schluessel Batterie
'Bitte Schlüsselbatterie wechseln!'";
CM_ SG_ 1411 FFB_CarFinder "Car Finder Funktion (Blinken ohne zu entriegeln)";
CM_ SG_ 1411 FFB_Komfortoeffnen "Komfortoeffnen Funk
";
CM_ SG_ 1411 FFB_Komfortschliessen "Komfortschliessen Funk
";
CM_ SG_ 1411 HBFS_gesafet "HBFS Tuer gesafet.
Im Zustand Safe wird auch das Signal HBFS_verriegelt = 1 gesendet.";
CM_ SG_ 1411 HBFS_verriegelt "Verriegelungsstatus Tür";
CM_ SG_ 1411 HD_Hauptraste "SBL-Schloss (MQB/MLBevo): Drehfalle Heckdeckel
sonst (MQB): Hauptraste Heckdeckel";
CM_ SG_ 1411 HD_Vorraste "SBL_Schloss (MQB/MLBevo): Sperrklinke Heckdeckel
sonst (MQB): Vorraste Heckdeckel";
CM_ SG_ 1411 HFS_gesafet "HFS Tuer gesafet.
Im Zustand Safe wird auch das Signal HFS_verriegelt = 1 gesendet.";
CM_ SG_ 1411 HFS_verriegelt "HFS Tuer verriegelt";
CM_ SG_ 1411 IRUE_aktiv "Status Innenraumüberwachung
";
CM_ SG_ 1411 IRUE_Taster_Fkts_LED "Anforderung Funktions-LED IRUE-Taster (LED wird vom TSG angesteuert)
MQB: Bei Verbau eines einzelnen Taster zur Deaktivierung von IRUE und NGS wird dieses Signal zur Ansteuerung der Funktions-LED gesendet.";
CM_ SG_ 1411 ZV_BT_offen "gespiegeltes Bit BT_Tuer_geoeffnet TSG_BT_1 Botschaft";
CM_ SG_ 1411 ZV_Einzeltuerentriegelung "Einzeltürentriegelung ZV
";
CM_ SG_ 1411 ZV_FT_offen "gespiegeltes Bit FT_Tuer_geoeffnet TSG_FT_1 Botschaft";
CM_ SG_ 1411 ZV_gesafet_extern_ist "Istzustand: Fahrzeug aussen gesafet
";
CM_ SG_ 1411 ZV_gesafet_extern_soll "Sollzustand: Fahrzeug gesafet extern
";
CM_ SG_ 1411 ZV_HBFS_offen "gespiegeltes Bit HBFS_Tuer_geoeffnet TSG_HBFS_1 Botschaft";
CM_ SG_ 1411 ZV_HD_offen "Status Heckdeckel
";
CM_ SG_ 1411 ZV_Heckeinzelentriegelung "Heckdeckeleinzelentriegelung";
CM_ SG_ 1411 ZV_HFS_offen "gespiegeltes Bit HFS_Tuer_geoeffnet TSG_HFS_1 Botschaft";
CM_ SG_ 1411 ZV_HS_offen "Status Heckscheibe
";
CM_ SG_ 1411 ZV_ist_Zustand_verfuegbar "Verfügbarkeit IST-Zustand ZV

";
CM_ SG_ 1411 ZV_Oeffnungsmodus "Konfigurierter Oeffnungsmodus fuer ZV:
0 = globale Oeffnung (alle Tueren)
1 = ZV mit Einzeltuerentriegelung (FFB - nur Fahrertuer, Kessy - nur bediente Tuer)
2 = ZV individuell selektive Oeffnung (FFB - Fahrerseite, Kessy - bediente Tuer + Fahrertuer)";
CM_ SG_ 1411 ZV_Rollo_auf "Komfortöffnen des Dachrollos";
CM_ SG_ 1411 ZV_Rollo_zu "Komfortschließen des Dachrollos";
CM_ SG_ 1411 ZV_SAD_auf "Komfortöffnen des Schiebeausstelldaches";
CM_ SG_ 1411 ZV_SAD_zu "Komfortschließen des Schiebeausstelldaches";
CM_ SG_ 1411 ZV_SafeFunktion_aktiv "Statusübermittlung ob die Safe Funktion im Fzg. aktiv ist. Das Kombi benötigt das Signal, um den Text Safelock aktiv anzuzeigen. ";
CM_ SG_ 1411 ZV_Schluessel_Zugang "aktuelle Funkschlüsselnummer";
CM_ SG_ 1411 ZV_Tankklappe_offen "Öffnungsstatus der Tankklappe";
CM_ SG_ 1411 ZV_verriegelt_extern_ist "Istzustand: Verriegelung Fahrzeug aussen
";
CM_ SG_ 1411 ZV_verriegelt_extern_soll "Sollzustand: Verriegelung Fahrzeug aussen
";
CM_ SG_ 1411 ZV_verriegelt_intern_ist "Istzustand: Verriegelung Fahrzeug innen
";
CM_ SG_ 1411 ZV_verriegelt_intern_soll "Sollzustand: Verriegelung Fahrzeug innen
";
CM_ SG_ 1411 ZV_verriegelt_soll "Fahrzeug Gesamtverriegelungsstatus Sollzustand für Ladestecker- und Ladeklappenverriegelung. ";
BA_DEF_REL_ BU_SG_REL_  "GenSigTimeoutTime" INT 0 65535;
BA_DEF_ BO_  "DiagRequest" ENUM "No", "Yes";
BA_DEF_ BO_  "DiagResponse" ENUM "No", "Yes";
BA_DEF_ BO_  "DiagState" ENUM "No", "Yes";
BA_DEF_ BO_  "GenMsgChkConstant" HEX 0 4095;
BA_DEF_ BO_  "GenMsgCycleTime" INT 0 65535;
BA_DEF_ BO_  "GenMsgCycleTimeFast" INT 0 65535;
BA_DEF_ BO_  "GenMsgDelayTime" INT 0 100000;
BA_DEF_ BO_  "GenMsgILSupport" ENUM "No", "Yes";
BA_DEF_ BO_  "GenMsgNrOfRepetition" INT 0 100;
BA_DEF_ BO_  "GenMsgPDUConstants" STRING;
BA_DEF_ BO_  "GenMsgSendType" ENUM "Cyclic", "not_used", "not_used", "not_used", "not_used", "not_used", "not_used", "IfActive", "NoMsgSendType";
BA_DEF_ BO_  "GenMsgStartDelayTime" INT 0 100000;
BA_DEF_ BO_  "NmMessage" ENUM "No", "Yes";
BA_DEF_ BO_  "NmhMessage" ENUM "No", "Yes";
BA_DEF_ BO_  "MsgType" ENUM "Application", "NM ", "NMH", "TP2.0", "ISO-TP ", "BAP", "EID", "KS", "XCP_PRE_CONFIGURED", "XCP_RUNTIME_CONFIGURED";
BA_DEF_ BO_  "VAGTP20_API" HEX 0 255;
BA_DEF_ BO_  "VAGTP20_DynConnection" ENUM "No", "Yes";
BA_DEF_ BO_  "VAGTP20_DynSetup" ENUM "No", "Yes";
BA_DEF_ BO_  "VAGTP20_StatConnection" ENUM "No", "Yes";
BA_DEF_ SG_  "GenSigActiveRepetitions" INT -2147483648 2147483647;
BA_DEF_ SG_  "GenSigInactiveValue" INT -2147483648 2147483647;
BA_DEF_ SG_  "GenSigSendType" ENUM "Cyclic", "OnWrite", "OnWriteWithRepetition", "OnChange", "OnChangeWithRepetition", "IfActive", "IfActiveWithRepetition", "NoSigSendType", "OnChangeAndIfActive", "OnChangeAndIfActiveWithRepetition";
BA_DEF_ SG_  "GenSigStartValue" INT -2147483648 2147483647;
BA_DEF_ SG_  "NWM-WakeupAllowed" ENUM "No", "Yes";
BA_DEF_ SG_  "GenSigFuncType" ENUM "NoFunction", "MsgCounter", "CRC-8", "XOR", "XOR-2", "DatedBit", "SW-Kl15", "CHK", "Constant", "Protocol", "CRC-8-SAE_J1850", "CRC-32", "DataLength", "DataID", "MsgCounter16", "SOK-Signatur", "Cluster";
BA_DEF_ SG_  "GenSigSwitchedByIgnition" ENUM "No", "Yes";
BA_DEF_ SG_  "Fehlerwert" HEX 0 2147483647;
BA_DEF_ SG_  "GenSigMissingSourceValue" HEX 0 2147483647;
BA_DEF_DEF_REL_  "GenSigTimeoutTime" 0;
BA_DEF_DEF_  "DiagRequest" "No";
BA_DEF_DEF_  "DiagResponse" "No";
BA_DEF_DEF_  "DiagState" "No";
BA_DEF_DEF_  "GenMsgChkConstant" 0;
BA_DEF_DEF_  "GenMsgCycleTime" 0;
BA_DEF_DEF_  "GenMsgCycleTimeFast" 0;
BA_DEF_DEF_  "GenMsgDelayTime" 0;
BA_DEF_DEF_  "GenMsgILSupport" "No";
BA_DEF_DEF_  "GenMsgNrOfRepetition" 0;
BA_DEF_DEF_  "GenMsgPDUConstants" "";
BA_DEF_DEF_  "GenMsgSendType" "NoMsgSendType";
BA_DEF_DEF_  "GenMsgStartDelayTime" 0;
BA_DEF_DEF_  "NmMessage" "No";
BA_DEF_DEF_  "NmhMessage" "No";
BA_DEF_DEF_  "MsgType" "Application";
BA_DEF_DEF_  "VAGTP20_API" 0;
BA_DEF_DEF_  "VAGTP20_DynConnection" "No";
BA_DEF_DEF_  "VAGTP20_DynSetup" "No";
BA_DEF_DEF_  "VAGTP20_StatConnection" "No";
BA_DEF_DEF_  "GenSigActiveRepetitions" 0;
BA_DEF_DEF_  "GenSigInactiveValue" 0;
BA_DEF_DEF_  "GenSigSendType" "NoSigSendType";
BA_DEF_DEF_  "GenSigStartValue" 0;
BA_DEF_DEF_  "NWM-WakeupAllowed" "No";
BA_DEF_DEF_  "GenSigFuncType" "NoFunction";
BA_DEF_DEF_  "GenSigSwitchedByIgnition" "Yes";
BA_DEF_DEF_  "Fehlerwert" 0;
BA_DEF_DEF_  "GenSigMissingSourceValue" 0;
BA_ "GenMsgCycleTime" BO_ 977 100;
BA_ "GenMsgDelayTime" BO_ 977 20;
BA_ "GenMsgILSupport" BO_ 977 1;
BA_ "GenMsgSendType" BO_ 977 0;
BA_ "GenMsgCycleTime" BO_ 976 100;
BA_ "GenMsgDelayTime" BO_ 976 20;
BA_ "GenMsgILSupport" BO_ 976 1;
BA_ "GenMsgSendType" BO_ 976 0;
BA_ "GenMsgCycleTime" BO_ 997 100;
BA_ "GenMsgDelayTime" BO_ 997 20;
BA_ "GenMsgILSupport" BO_ 997 1;
BA_ "GenMsgPDUConstants" BO_ 997 "0xc4,0x6a,0x69,0x30,0xcf,0x61,0x58,0x51,0x1b,0x86,0x99,0xd3,0xf6,0x1d,0x9a,0x37";
BA_ "GenMsgSendType" BO_ 997 0;
BA_ "GenMsgCycleTime" BO_ 975 100;
BA_ "GenMsgDelayTime" BO_ 975 20;
BA_ "GenMsgILSupport" BO_ 975 1;
BA_ "GenMsgSendType" BO_ 975 0;
BA_ "GenMsgCycleTime" BO_ 974 100;
BA_ "GenMsgDelayTime" BO_ 974 20;
BA_ "GenMsgILSupport" BO_ 974 1;
BA_ "GenMsgSendType" BO_ 974 0;
BA_ "GenMsgCycleTime" BO_ 618 1000;
BA_ "GenMsgDelayTime" BO_ 618 100;
BA_ "GenMsgILSupport" BO_ 618 1;
BA_ "GenMsgSendType" BO_ 618 0;
BA_ "GenMsgCycleTime" BO_ 2463978633 100;
BA_ "GenMsgDelayTime" BO_ 2463978633 50;
BA_ "GenMsgILSupport" BO_ 2463978633 1;
BA_ "GenMsgPDUConstants" BO_ 2463978633 "0x81,0xad,0x54,0x1d,0x28,0xac,0x6c,0x8e,0xd4,0x6e,0xeb,0x58,0x4a,0x71,0x5a,0x3b";
BA_ "GenMsgSendType" BO_ 2463978633 0;
BA_ "GenMsgCycleTime" BO_ 2463978634 100;
BA_ "GenMsgDelayTime" BO_ 2463978634 50;
BA_ "GenMsgILSupport" BO_ 2463978634 1;
BA_ "GenMsgPDUConstants" BO_ 2463978634 "0x10,0xec,0x76,0x31,0x11,0x02,0x55,0xbe,0xa8,0xba,0x68,0x51,0x40,0x7a,0x23,0x13";
BA_ "GenMsgSendType" BO_ 2463978634 0;
BA_ "GenMsgCycleTime" BO_ 995 100;
BA_ "GenMsgCycleTimeFast" BO_ 995 50;
BA_ "GenMsgDelayTime" BO_ 995 50;
BA_ "GenMsgILSupport" BO_ 995 1;
BA_ "GenMsgNrOfRepetition" BO_ 995 5;
BA_ "GenMsgPDUConstants" BO_ 995 "0xad,0x1d,0xac,0x8e,0x6e,0x58,0x71,0x3b,0xce,0xc6,0x27,0x4f,0x06,0xca,0x65,0x84";
BA_ "GenMsgSendType" BO_ 995 0;
BA_ "GenMsgCycleTime" BO_ 1716 200;
BA_ "GenMsgILSupport" BO_ 1716 1;
BA_ "GenMsgSendType" BO_ 1716 0;
BA_ "GenMsgCycleTime" BO_ 1702 500;
BA_ "GenMsgCycleTimeFast" BO_ 1702 100;
BA_ "GenMsgDelayTime" BO_ 1702 50;
BA_ "GenMsgILSupport" BO_ 1702 1;
BA_ "GenMsgNrOfRepetition" BO_ 1702 3;
BA_ "GenMsgSendType" BO_ 1702 0;
BA_ "MsgType" BO_ 2617079296 6;
BA_ "MsgType" BO_ 2617079297 6;
BA_ "MsgType" BO_ 2617083392 6;
BA_ "MsgType" BO_ 2617083393 6;
BA_ "MsgType" BO_ 2617064960 6;
BA_ "MsgType" BO_ 2617064961 6;
BA_ "MsgType" BO_ 2617007616 6;
BA_ "MsgType" BO_ 2617007617 6;
BA_ "MsgType" BO_ 2617200128 6;
BA_ "MsgType" BO_ 2617200129 6;
BA_ "MsgType" BO_ 2617071104 6;
BA_ "MsgType" BO_ 2617071105 6;
BA_ "MsgType" BO_ 2617202176 6;
BA_ "MsgType" BO_ 2617202177 6;
BA_ "MsgType" BO_ 2617005824 6;
BA_ "MsgType" BO_ 2617005825 6;
BA_ "MsgType" BO_ 2617144832 6;
BA_ "MsgType" BO_ 2617144833 6;
BA_ "GenMsgCycleTime" BO_ 1411 200;
BA_ "GenMsgCycleTimeFast" BO_ 1411 50;
BA_ "GenMsgDelayTime" BO_ 1411 50;
BA_ "GenMsgILSupport" BO_ 1411 1;
BA_ "GenMsgNrOfRepetition" BO_ 1411 5;
BA_ "GenMsgSendType" BO_ 1411 0;
BA_ "GenSigSendType" SG_ 977 ASW_Warnung_aktiv_BFS 3;
BA_ "GenSigSwitchedByIgnition" SG_ 977 ASW_Warnung_aktiv_BFS 0;
BA_ "GenSigSendType" SG_ 977 BFS_Status_eTAG 0;
BA_ "GenSigSwitchedByIgnition" SG_ 977 BFS_Status_eTAG 0;
BA_ "Fehlerwert" SG_ 977 BFS_Status_eTAG 3;
BA_ "GenSigSendType" SG_ 977 BT_ASW_HMI_defekt 0;
BA_ "GenSigSwitchedByIgnition" SG_ 977 BT_ASW_HMI_defekt 0;
BA_ "GenSigSendType" SG_ 977 BT_EC_Spiegel_Helligkeit 3;
BA_ "GenSigSwitchedByIgnition" SG_ 977 BT_EC_Spiegel_Helligkeit 0;
BA_ "GenSigSendType" SG_ 977 BT_FH_Bew_hoch 3;
BA_ "GenSigSwitchedByIgnition" SG_ 977 BT_FH_Bew_hoch 0;
BA_ "GenSigSendType" SG_ 977 BT_FH_Bew_tief 3;
BA_ "GenSigSwitchedByIgnition" SG_ 977 BT_FH_Bew_tief 0;
BA_ "GenSigSendType" SG_ 977 BT_FH_Block 3;
BA_ "GenSigSwitchedByIgnition" SG_ 977 BT_FH_Block 0;
BA_ "GenSigSendType" SG_ 977 BT_FH_Fang 3;
BA_ "GenSigSwitchedByIgnition" SG_ 977 BT_FH_Fang 0;
BA_ "GenSigSendType" SG_ 977 BT_FH_normiert 3;
BA_ "GenSigSwitchedByIgnition" SG_ 977 BT_FH_normiert 0;
BA_ "GenSigSendType" SG_ 977 BT_FH_Oeffnung 3;
BA_ "GenSigSwitchedByIgnition" SG_ 977 BT_FH_Oeffnung 0;
BA_ "GenSigSendType" SG_ 977 BT_FH_Pos_oben 3;
BA_ "GenSigSwitchedByIgnition" SG_ 977 BT_FH_Pos_oben 0;
BA_ "GenSigSendType" SG_ 977 BT_FH_S_AutoHoch 3;
BA_ "GenSigSwitchedByIgnition" SG_ 977 BT_FH_S_AutoHoch 0;
BA_ "GenSigSendType" SG_ 977 BT_FH_S_AutoTief 3;
BA_ "GenSigSwitchedByIgnition" SG_ 977 BT_FH_S_AutoTief 0;
BA_ "GenSigSendType" SG_ 977 BT_FH_S_ManHoch 3;
BA_ "GenSigSwitchedByIgnition" SG_ 977 BT_FH_S_ManHoch 0;
BA_ "GenSigSendType" SG_ 977 BT_FH_S_ManTief 3;
BA_ "GenSigSwitchedByIgnition" SG_ 977 BT_FH_S_ManTief 0;
BA_ "GenSigSendType" SG_ 977 BT_FH_Thermo 3;
BA_ "GenSigSwitchedByIgnition" SG_ 977 BT_FH_Thermo 0;
BA_ "GenSigSendType" SG_ 977 BT_gesafet 3;
BA_ "GenSigSwitchedByIgnition" SG_ 977 BT_gesafet 0;
BA_ "GenSigSendType" SG_ 977 BT_Kisi_Fehler 3;
BA_ "GenSigSwitchedByIgnition" SG_ 977 BT_Kisi_Fehler 0;
BA_ "Fehlerwert" SG_ 977 BT_Kisi_Fehler 1;
BA_ "GenSigSendType" SG_ 977 BT_Lock_Taster 3;
BA_ "GenSigSwitchedByIgnition" SG_ 977 BT_Lock_Taster 0;
BA_ "GenSigSendType" SG_ 977 BT_Lock_Taster_inv 3;
BA_ "GenSigSwitchedByIgnition" SG_ 977 BT_Lock_Taster_inv 0;
BA_ "GenSigSendType" SG_ 977 BT_Oben_Block_erw 3;
BA_ "GenSigSwitchedByIgnition" SG_ 977 BT_Oben_Block_erw 0;
BA_ "GenSigSendType" SG_ 977 BT_Schliesstaster 3;
BA_ "GenSigSwitchedByIgnition" SG_ 977 BT_Schliesstaster 0;
BA_ "GenSigSendType" SG_ 977 BT_Schluesselschalter_auf 3;
BA_ "GenSigSwitchedByIgnition" SG_ 977 BT_Schluesselschalter_auf 0;
BA_ "GenSigSendType" SG_ 977 BT_Schluesselschalter_zu 3;
BA_ "GenSigSwitchedByIgnition" SG_ 977 BT_Schluesselschalter_zu 0;
BA_ "GenSigSendType" SG_ 977 BT_Schluesselschalter_zu_inv 3;
BA_ "GenSigSwitchedByIgnition" SG_ 977 BT_Schluesselschalter_zu_inv 0;
BA_ "GenSigSendType" SG_ 977 BT_SP_ausgerastet 3;
BA_ "GenSigSwitchedByIgnition" SG_ 977 BT_SP_ausgerastet 0;
BA_ "GenSigSendType" SG_ 977 BT_Sp_Blk_def 3;
BA_ "GenSigSwitchedByIgnition" SG_ 977 BT_Sp_Blk_def 0;
BA_ "GenSigSendType" SG_ 977 BT_SP_Heizung_aktiv 3;
BA_ "GenSigSwitchedByIgnition" SG_ 977 BT_SP_Heizung_aktiv 0;
BA_ "GenSigSendType" SG_ 977 BT_Sp_Heizung_Anf 0;
BA_ "GenSigSwitchedByIgnition" SG_ 977 BT_Sp_Heizung_Anf 0;
BA_ "GenSigSendType" SG_ 977 BT_SP_Heizung_Status 3;
BA_ "GenSigSwitchedByIgnition" SG_ 977 BT_SP_Heizung_Status 0;
BA_ "GenSigSendType" SG_ 977 BT_SP_ht_aktiv 3;
BA_ "GenSigSwitchedByIgnition" SG_ 977 BT_SP_ht_aktiv 0;
BA_ "GenSigSendType" SG_ 977 BT_SP_lr_aktiv 3;
BA_ "GenSigSwitchedByIgnition" SG_ 977 BT_SP_lr_aktiv 0;
BA_ "GenSigSendType" SG_ 977 BT_Sperrklinke 3;
BA_ "GenSigSwitchedByIgnition" SG_ 977 BT_Sperrklinke 0;
BA_ "GenSigSendType" SG_ 977 BT_SWA_HMI_defekt 0;
BA_ "GenSigSwitchedByIgnition" SG_ 977 BT_SWA_HMI_defekt 0;
BA_ "GenSigSendType" SG_ 977 BT_TAG_betaetigt 3;
BA_ "GenSigSwitchedByIgnition" SG_ 977 BT_TAG_betaetigt 0;
BA_ "GenSigSendType" SG_ 977 BT_TCR_Mode_aktiv 0;
BA_ "GenSigSwitchedByIgnition" SG_ 977 BT_TCR_Mode_aktiv 0;
BA_ "GenSigSendType" SG_ 977 BT_TIG_betaetigt 3;
BA_ "GenSigSwitchedByIgnition" SG_ 977 BT_TIG_betaetigt 0;
BA_ "GenSigSendType" SG_ 977 BT_TSG_hinten_verbaut 3;
BA_ "GenSigSwitchedByIgnition" SG_ 977 BT_TSG_hinten_verbaut 0;
BA_ "GenSigSendType" SG_ 977 BT_Tuer_geoeffnet 3;
BA_ "GenSigSwitchedByIgnition" SG_ 977 BT_Tuer_geoeffnet 0;
BA_ "GenSigSendType" SG_ 977 BT_Tuer_Status 3;
BA_ "GenSigSwitchedByIgnition" SG_ 977 BT_Tuer_Status 0;
BA_ "Fehlerwert" SG_ 977 BT_Tuer_Status 3;
BA_ "GenSigSendType" SG_ 977 BT_Tuer_Status_QBit 0;
BA_ "GenSigSwitchedByIgnition" SG_ 977 BT_Tuer_Status_QBit 0;
BA_ "GenSigSendType" SG_ 977 BT_Tueroeffnen_Warnung 3;
BA_ "GenSigSwitchedByIgnition" SG_ 977 BT_Tueroeffnen_Warnung 0;
BA_ "GenSigSendType" SG_ 977 BT_Tuerschloss_defekt 0;
BA_ "GenSigSwitchedByIgnition" SG_ 977 BT_Tuerschloss_defekt 0;
BA_ "GenSigSendType" SG_ 977 BT_UEKB_aktiviert 3;
BA_ "GenSigSwitchedByIgnition" SG_ 977 BT_UEKB_aktiviert 0;
BA_ "GenSigSendType" SG_ 977 BT_Unlock_Taster 3;
BA_ "GenSigSwitchedByIgnition" SG_ 977 BT_Unlock_Taster 0;
BA_ "GenSigSendType" SG_ 977 BT_Unten_Block_erw 3;
BA_ "GenSigSwitchedByIgnition" SG_ 977 BT_Unten_Block_erw 0;
BA_ "GenSigSendType" SG_ 977 BT_verriegelt 3;
BA_ "GenSigSwitchedByIgnition" SG_ 977 BT_verriegelt 0;
BA_ "GenSigSendType" SG_ 977 BT_Zuziehhilfe_aktiv 3;
BA_ "GenSigSwitchedByIgnition" SG_ 977 BT_Zuziehhilfe_aktiv 0;
BA_ "GenSigSendType" SG_ 976 ASW_HMI_defekt 0;
BA_ "GenSigSwitchedByIgnition" SG_ 976 ASW_HMI_defekt 0;
BA_ "GenSigSendType" SG_ 976 ASW_wakeup 3;
BA_ "GenSigSwitchedByIgnition" SG_ 976 ASW_wakeup 0;
BA_ "GenSigSendType" SG_ 976 ASW_Warnung_aktiv_FS 3;
BA_ "GenSigSwitchedByIgnition" SG_ 976 ASW_Warnung_aktiv_FS 0;
BA_ "GenSigSendType" SG_ 976 FS_Status_eTAG 3;
BA_ "GenSigSwitchedByIgnition" SG_ 976 FS_Status_eTAG 0;
BA_ "Fehlerwert" SG_ 976 FS_Status_eTAG 3;
BA_ "GenSigSendType" SG_ 976 FT_BFS_Fond_Freigabe 3;
BA_ "GenSigSwitchedByIgnition" SG_ 976 FT_BFS_Fond_Freigabe 0;
BA_ "GenSigSendType" SG_ 976 FT_Daemmglas 3;
BA_ "GenSigSwitchedByIgnition" SG_ 976 FT_Daemmglas 0;
BA_ "GenSigSendType" SG_ 976 FT_FH_Bew_hoch 3;
BA_ "GenSigSwitchedByIgnition" SG_ 976 FT_FH_Bew_hoch 0;
BA_ "GenSigSendType" SG_ 976 FT_FH_Bew_tief 3;
BA_ "GenSigSwitchedByIgnition" SG_ 976 FT_FH_Bew_tief 0;
BA_ "GenSigSendType" SG_ 976 FT_FH_Block 3;
BA_ "GenSigSwitchedByIgnition" SG_ 976 FT_FH_Block 0;
BA_ "GenSigSendType" SG_ 976 FT_FH_Fang 3;
BA_ "GenSigSwitchedByIgnition" SG_ 976 FT_FH_Fang 0;
BA_ "GenSigSendType" SG_ 976 FT_FH_normiert 3;
BA_ "GenSigSwitchedByIgnition" SG_ 976 FT_FH_normiert 0;
BA_ "GenSigSendType" SG_ 976 FT_FH_Oeffnung 3;
BA_ "GenSigSwitchedByIgnition" SG_ 976 FT_FH_Oeffnung 0;
BA_ "GenSigSendType" SG_ 976 FT_FH_Pos_oben 3;
BA_ "GenSigSwitchedByIgnition" SG_ 976 FT_FH_Pos_oben 0;
BA_ "GenSigSendType" SG_ 976 FT_FH_S_AutoHoch 3;
BA_ "GenSigSwitchedByIgnition" SG_ 976 FT_FH_S_AutoHoch 0;
BA_ "GenSigSendType" SG_ 976 FT_FH_S_AutoTief 3;
BA_ "GenSigSwitchedByIgnition" SG_ 976 FT_FH_S_AutoTief 0;
BA_ "GenSigSendType" SG_ 976 FT_FH_S_ManHoch 3;
BA_ "GenSigSwitchedByIgnition" SG_ 976 FT_FH_S_ManHoch 0;
BA_ "GenSigSendType" SG_ 976 FT_FH_S_ManTief 3;
BA_ "GenSigSwitchedByIgnition" SG_ 976 FT_FH_S_ManTief 0;
BA_ "GenSigSendType" SG_ 976 FT_FH_Thermo 3;
BA_ "GenSigSwitchedByIgnition" SG_ 976 FT_FH_Thermo 0;
BA_ "GenSigSendType" SG_ 976 FT_gesafet 3;
BA_ "GenSigSwitchedByIgnition" SG_ 976 FT_gesafet 0;
BA_ "GenSigSendType" SG_ 976 FT_HD_Taste 3;
BA_ "GenSigSwitchedByIgnition" SG_ 976 FT_HD_Taste 0;
BA_ "GenSigSendType" SG_ 976 FT_HD_Taste_2 3;
BA_ "GenSigSwitchedByIgnition" SG_ 976 FT_HD_Taste_2 0;
BA_ "GenSigSendType" SG_ 976 FT_IRUE_Taste 3;
BA_ "GenSigSwitchedByIgnition" SG_ 976 FT_IRUE_Taste 0;
BA_ "GenSigSendType" SG_ 976 FT_Kisi_Fehler 3;
BA_ "GenSigSwitchedByIgnition" SG_ 976 FT_Kisi_Fehler 0;
BA_ "Fehlerwert" SG_ 976 FT_Kisi_Fehler 1;
BA_ "GenSigSendType" SG_ 976 FT_Kisi_li_aktiv 3;
BA_ "GenSigSwitchedByIgnition" SG_ 976 FT_Kisi_li_aktiv 0;
BA_ "GenSigSendType" SG_ 976 FT_Kisi_re_aktiv 3;
BA_ "GenSigSwitchedByIgnition" SG_ 976 FT_Kisi_re_aktiv 0;
BA_ "GenSigSendType" SG_ 976 FT_Kisi_Taster_li 3;
BA_ "GenSigSwitchedByIgnition" SG_ 976 FT_Kisi_Taster_li 0;
BA_ "GenSigSendType" SG_ 976 FT_Kisi_Taster_re 3;
BA_ "GenSigSwitchedByIgnition" SG_ 976 FT_Kisi_Taster_re 0;
BA_ "GenSigSendType" SG_ 976 FT_Lock_Taster 3;
BA_ "GenSigSwitchedByIgnition" SG_ 976 FT_Lock_Taster 0;
BA_ "GenSigSendType" SG_ 976 FT_Oben_Block_erw 3;
BA_ "GenSigSwitchedByIgnition" SG_ 976 FT_Oben_Block_erw 0;
BA_ "GenSigSendType" SG_ 976 FT_Schliesstaster 3;
BA_ "GenSigSwitchedByIgnition" SG_ 976 FT_Schliesstaster 0;
BA_ "GenSigSendType" SG_ 976 FT_Schluesselschalter_auf 3;
BA_ "GenSigSwitchedByIgnition" SG_ 976 FT_Schluesselschalter_auf 0;
BA_ "GenSigSendType" SG_ 976 FT_Schluesselschalter_zu 3;
BA_ "GenSigSwitchedByIgnition" SG_ 976 FT_Schluesselschalter_zu 0;
BA_ "GenSigSendType" SG_ 976 FT_SP_ausgerastet 3;
BA_ "GenSigSwitchedByIgnition" SG_ 976 FT_SP_ausgerastet 0;
BA_ "GenSigSendType" SG_ 976 FT_Sp_Blk_def 3;
BA_ "GenSigSwitchedByIgnition" SG_ 976 FT_Sp_Blk_def 0;
BA_ "GenSigSendType" SG_ 976 FT_Sp_Heizung_Anf 0;
BA_ "GenSigSwitchedByIgnition" SG_ 976 FT_Sp_Heizung_Anf 0;
BA_ "GenSigSendType" SG_ 976 FT_SP_Heizung_Status 3;
BA_ "GenSigSwitchedByIgnition" SG_ 976 FT_SP_Heizung_Status 0;
BA_ "GenSigSendType" SG_ 976 FT_SP_ht_aktiv 3;
BA_ "GenSigSwitchedByIgnition" SG_ 976 FT_SP_ht_aktiv 0;
BA_ "GenSigSendType" SG_ 976 FT_SP_lr_aktiv 3;
BA_ "GenSigSwitchedByIgnition" SG_ 976 FT_SP_lr_aktiv 0;
BA_ "GenSigSendType" SG_ 976 FT_Sperrklinke 3;
BA_ "GenSigSwitchedByIgnition" SG_ 976 FT_Sperrklinke 0;
BA_ "GenSigSendType" SG_ 976 FT_SWA_Taster 3;
BA_ "GenSigSwitchedByIgnition" SG_ 976 FT_SWA_Taster 0;
BA_ "GenSigSendType" SG_ 976 FT_TAG_betaetigt 3;
BA_ "GenSigSwitchedByIgnition" SG_ 976 FT_TAG_betaetigt 0;
BA_ "GenSigSendType" SG_ 976 FT_TD_Taste 3;
BA_ "GenSigSwitchedByIgnition" SG_ 976 FT_TD_Taste 0;
BA_ "GenSigSendType" SG_ 976 FT_TD_Taste_Fehler 0;
BA_ "GenSigSwitchedByIgnition" SG_ 976 FT_TD_Taste_Fehler 0;
BA_ "GenSigSendType" SG_ 976 FT_TIG_betaetigt 3;
BA_ "GenSigSwitchedByIgnition" SG_ 976 FT_TIG_betaetigt 0;
BA_ "GenSigSendType" SG_ 976 FT_TSG_hinten_verbaut 3;
BA_ "GenSigSwitchedByIgnition" SG_ 976 FT_TSG_hinten_verbaut 0;
BA_ "GenSigSendType" SG_ 976 FT_Tuer_geoeffnet 3;
BA_ "GenSigSwitchedByIgnition" SG_ 976 FT_Tuer_geoeffnet 0;
BA_ "GenSigSendType" SG_ 976 FT_Tuerschloss_defekt 0;
BA_ "GenSigSwitchedByIgnition" SG_ 976 FT_Tuerschloss_defekt 0;
BA_ "GenSigSendType" SG_ 976 FT_UEKB_aktiviert 3;
BA_ "GenSigSwitchedByIgnition" SG_ 976 FT_UEKB_aktiviert 0;
BA_ "GenSigSendType" SG_ 976 FT_Unlock_Taster 3;
BA_ "GenSigSwitchedByIgnition" SG_ 976 FT_Unlock_Taster 0;
BA_ "GenSigSendType" SG_ 976 FT_Unten_Block_erw 3;
BA_ "GenSigSwitchedByIgnition" SG_ 976 FT_Unten_Block_erw 0;
BA_ "GenSigSendType" SG_ 976 FT_verriegelt 3;
BA_ "GenSigSwitchedByIgnition" SG_ 976 FT_verriegelt 0;
BA_ "GenSigSendType" SG_ 976 FT_Zuziehhilfe_aktiv 3;
BA_ "GenSigSwitchedByIgnition" SG_ 976 FT_Zuziehhilfe_aktiv 0;
BA_ "GenSigSendType" SG_ 976 SSR_Temp_Freigabe 0;
BA_ "GenSigSwitchedByIgnition" SG_ 976 SSR_Temp_Freigabe 0;
BA_ "GenSigSendType" SG_ 976 SWA_HMI_Diagnose 0;
BA_ "GenSigSwitchedByIgnition" SG_ 976 SWA_HMI_Diagnose 0;
BA_ "GenSigSendType" SG_ 997 FS_Push_Tuergriff 3;
BA_ "GenSigSwitchedByIgnition" SG_ 997 FS_Push_Tuergriff 0;
BA_ "GenSigSendType" SG_ 997 FT_BFS_Tuer_Status 3;
BA_ "GenSigSwitchedByIgnition" SG_ 997 FT_BFS_Tuer_Status 0;
BA_ "Fehlerwert" SG_ 997 FT_BFS_Tuer_Status 3;
BA_ "GenSigSendType" SG_ 997 FT_HBFS_Tuer_Status 3;
BA_ "GenSigSwitchedByIgnition" SG_ 997 FT_HBFS_Tuer_Status 0;
BA_ "Fehlerwert" SG_ 997 FT_HBFS_Tuer_Status 3;
BA_ "GenSigSendType" SG_ 997 FT_HFS_Tuer_Status 3;
BA_ "GenSigSwitchedByIgnition" SG_ 997 FT_HFS_Tuer_Status 0;
BA_ "Fehlerwert" SG_ 997 FT_HFS_Tuer_Status 3;
BA_ "GenSigSendType" SG_ 997 FT_Kisi_Taster_li_02 3;
BA_ "GenSigSwitchedByIgnition" SG_ 997 FT_Kisi_Taster_li_02 0;
BA_ "GenSigSendType" SG_ 997 FT_Kisi_Taster_re_02 3;
BA_ "GenSigSwitchedByIgnition" SG_ 997 FT_Kisi_Taster_re_02 0;
BA_ "GenSigSendType" SG_ 997 FT_Lock_Taster_02 3;
BA_ "GenSigSwitchedByIgnition" SG_ 997 FT_Lock_Taster_02 0;
BA_ "GenSigSendType" SG_ 997 FT_Schluesselschalter_zu_02 3;
BA_ "GenSigSwitchedByIgnition" SG_ 997 FT_Schluesselschalter_zu_02 0;
BA_ "GenSigSendType" SG_ 997 FT_SP_Heizung_ein 3;
BA_ "GenSigSwitchedByIgnition" SG_ 997 FT_SP_Heizung_ein 0;
BA_ "GenSigSendType" SG_ 997 FT_TCR_Mode_aktiv 3;
BA_ "GenSigSwitchedByIgnition" SG_ 997 FT_TCR_Mode_aktiv 0;
BA_ "GenSigSendType" SG_ 997 FT_TD_Taste_Status 3;
BA_ "GenSigSwitchedByIgnition" SG_ 997 FT_TD_Taste_Status 0;
BA_ "GenSigSendType" SG_ 997 FT_Tuer_Status 3;
BA_ "GenSigSwitchedByIgnition" SG_ 997 FT_Tuer_Status 0;
BA_ "Fehlerwert" SG_ 997 FT_Tuer_Status 3;
BA_ "GenSigSendType" SG_ 997 FT_Tuer_Status_QBit 3;
BA_ "GenSigSwitchedByIgnition" SG_ 997 FT_Tuer_Status_QBit 0;
BA_ "GenSigSendType" SG_ 997 FT_Tueroeffnen_Warnung 3;
BA_ "GenSigSwitchedByIgnition" SG_ 997 FT_Tueroeffnen_Warnung 0;
BA_ "GenSigSendType" SG_ 997 TSG_FT_02_BZ 0;
BA_ "GenSigFuncType" SG_ 997 TSG_FT_02_BZ 1;
BA_ "GenSigSwitchedByIgnition" SG_ 997 TSG_FT_02_BZ 0;
BA_ "GenSigSendType" SG_ 997 TSG_FT_02_CRC 0;
BA_ "GenSigFuncType" SG_ 997 TSG_FT_02_CRC 2;
BA_ "GenSigSwitchedByIgnition" SG_ 997 TSG_FT_02_CRC 0;
BA_ "GenSigSendType" SG_ 975 ASW_Warnung_aktiv_HBFS 3;
BA_ "GenSigSwitchedByIgnition" SG_ 975 ASW_Warnung_aktiv_HBFS 0;
BA_ "GenSigSendType" SG_ 975 HBFS_FH_Bew_hoch 3;
BA_ "GenSigSwitchedByIgnition" SG_ 975 HBFS_FH_Bew_hoch 0;
BA_ "GenSigSendType" SG_ 975 HBFS_FH_Bew_tief 3;
BA_ "GenSigSwitchedByIgnition" SG_ 975 HBFS_FH_Bew_tief 0;
BA_ "GenSigSendType" SG_ 975 HBFS_FH_Block 3;
BA_ "GenSigSwitchedByIgnition" SG_ 975 HBFS_FH_Block 0;
BA_ "GenSigSendType" SG_ 975 HBFS_FH_Fang 3;
BA_ "GenSigSwitchedByIgnition" SG_ 975 HBFS_FH_Fang 0;
BA_ "GenSigSendType" SG_ 975 HBFS_FH_normiert 3;
BA_ "GenSigSwitchedByIgnition" SG_ 975 HBFS_FH_normiert 0;
BA_ "GenSigSendType" SG_ 975 HBFS_FH_Oeffnung 3;
BA_ "GenSigSwitchedByIgnition" SG_ 975 HBFS_FH_Oeffnung 0;
BA_ "GenSigSendType" SG_ 975 HBFS_FH_S_AutoHoch 3;
BA_ "GenSigSwitchedByIgnition" SG_ 975 HBFS_FH_S_AutoHoch 0;
BA_ "GenSigSendType" SG_ 975 HBFS_FH_S_AutoTief 3;
BA_ "GenSigSwitchedByIgnition" SG_ 975 HBFS_FH_S_AutoTief 0;
BA_ "GenSigSendType" SG_ 975 HBFS_FH_S_HFS_AutoHoch 3;
BA_ "GenSigSwitchedByIgnition" SG_ 975 HBFS_FH_S_HFS_AutoHoch 0;
BA_ "GenSigSendType" SG_ 975 HBFS_FH_S_HFS_AutoTief 3;
BA_ "GenSigSwitchedByIgnition" SG_ 975 HBFS_FH_S_HFS_AutoTief 0;
BA_ "GenSigSendType" SG_ 975 HBFS_FH_S_HFS_ManHoch 3;
BA_ "GenSigSwitchedByIgnition" SG_ 975 HBFS_FH_S_HFS_ManHoch 0;
BA_ "GenSigSendType" SG_ 975 HBFS_FH_S_HFS_ManTief 3;
BA_ "GenSigSwitchedByIgnition" SG_ 975 HBFS_FH_S_HFS_ManTief 0;
BA_ "GenSigSendType" SG_ 975 HBFS_FH_S_ManHoch 3;
BA_ "GenSigSwitchedByIgnition" SG_ 975 HBFS_FH_S_ManHoch 0;
BA_ "GenSigSendType" SG_ 975 HBFS_FH_S_ManTief 3;
BA_ "GenSigSwitchedByIgnition" SG_ 975 HBFS_FH_S_ManTief 0;
BA_ "GenSigSendType" SG_ 975 HBFS_FH_Thermo 3;
BA_ "GenSigSwitchedByIgnition" SG_ 975 HBFS_FH_Thermo 0;
BA_ "GenSigSendType" SG_ 975 HBFS_gesafet 3;
BA_ "GenSigSwitchedByIgnition" SG_ 975 HBFS_gesafet 0;
BA_ "GenSigSendType" SG_ 975 HBFS_Heckrollotaster_betaetigt 3;
BA_ "GenSigSwitchedByIgnition" SG_ 975 HBFS_Heckrollotaster_betaetigt 0;
BA_ "GenSigSendType" SG_ 975 HBFS_Lock_Taster 3;
BA_ "GenSigSwitchedByIgnition" SG_ 975 HBFS_Lock_Taster 0;
BA_ "GenSigSendType" SG_ 975 HBFS_Lock_Taster_inv 3;
BA_ "GenSigSwitchedByIgnition" SG_ 975 HBFS_Lock_Taster_inv 0;
BA_ "GenSigSendType" SG_ 975 HBFS_MRollo_Schalter 3;
BA_ "GenSigStartValue" SG_ 975 HBFS_MRollo_Schalter 6;
BA_ "GenSigSwitchedByIgnition" SG_ 975 HBFS_MRollo_Schalter 0;
BA_ "Fehlerwert" SG_ 975 HBFS_MRollo_Schalter 7;
BA_ "GenSigSendType" SG_ 975 HBFS_Oben_Block_erw 3;
BA_ "GenSigSwitchedByIgnition" SG_ 975 HBFS_Oben_Block_erw 0;
BA_ "GenSigSendType" SG_ 975 HBFS_SAD_Schalter 3;
BA_ "GenSigStartValue" SG_ 975 HBFS_SAD_Schalter 14;
BA_ "GenSigSwitchedByIgnition" SG_ 975 HBFS_SAD_Schalter 0;
BA_ "Fehlerwert" SG_ 975 HBFS_SAD_Schalter 15;
BA_ "GenSigSendType" SG_ 975 HBFS_Seitenrollo_hoch 3;
BA_ "GenSigSwitchedByIgnition" SG_ 975 HBFS_Seitenrollo_hoch 0;
BA_ "GenSigSendType" SG_ 975 HBFS_Seitenrollo_tief 3;
BA_ "GenSigSwitchedByIgnition" SG_ 975 HBFS_Seitenrollo_tief 0;
BA_ "GenSigSendType" SG_ 975 HBFS_Sperrklinke 3;
BA_ "GenSigSwitchedByIgnition" SG_ 975 HBFS_Sperrklinke 0;
BA_ "GenSigSendType" SG_ 975 HBFS_Status_eTAG 0;
BA_ "GenSigSwitchedByIgnition" SG_ 975 HBFS_Status_eTAG 0;
BA_ "Fehlerwert" SG_ 975 HBFS_Status_eTAG 3;
BA_ "GenSigSendType" SG_ 975 HBFS_Status_KiSi 3;
BA_ "GenSigSwitchedByIgnition" SG_ 975 HBFS_Status_KiSi 0;
BA_ "GenSigSendType" SG_ 975 HBFS_Status_KiSi_inv 0;
BA_ "GenSigStartValue" SG_ 975 HBFS_Status_KiSi_inv 1;
BA_ "GenSigSwitchedByIgnition" SG_ 975 HBFS_Status_KiSi_inv 0;
BA_ "GenSigSendType" SG_ 975 HBFS_TAG_betaetigt 3;
BA_ "GenSigSwitchedByIgnition" SG_ 975 HBFS_TAG_betaetigt 0;
BA_ "GenSigSendType" SG_ 975 HBFS_TIG_betaetigt 3;
BA_ "GenSigSwitchedByIgnition" SG_ 975 HBFS_TIG_betaetigt 0;
BA_ "GenSigSendType" SG_ 975 HBFS_TIG_betaetigt_schliessen 3;
BA_ "GenSigSwitchedByIgnition" SG_ 975 HBFS_TIG_betaetigt_schliessen 0;
BA_ "GenSigSendType" SG_ 975 HBFS_Tuer_geoeffnet 3;
BA_ "GenSigSwitchedByIgnition" SG_ 975 HBFS_Tuer_geoeffnet 0;
BA_ "GenSigSendType" SG_ 975 HBFS_Tuer_Status 3;
BA_ "GenSigSwitchedByIgnition" SG_ 975 HBFS_Tuer_Status 0;
BA_ "Fehlerwert" SG_ 975 HBFS_Tuer_Status 3;
BA_ "GenSigSendType" SG_ 975 HBFS_Tuer_Status_QBit 0;
BA_ "GenSigSwitchedByIgnition" SG_ 975 HBFS_Tuer_Status_QBit 0;
BA_ "GenSigSendType" SG_ 975 HBFS_Tueroeffnen_Warnung 3;
BA_ "GenSigSwitchedByIgnition" SG_ 975 HBFS_Tueroeffnen_Warnung 0;
BA_ "GenSigSendType" SG_ 975 HBFS_Tuerschloss_defekt 0;
BA_ "GenSigSwitchedByIgnition" SG_ 975 HBFS_Tuerschloss_defekt 0;
BA_ "GenSigSendType" SG_ 975 HBFS_UEKB_aktiviert 3;
BA_ "GenSigSwitchedByIgnition" SG_ 975 HBFS_UEKB_aktiviert 0;
BA_ "GenSigSendType" SG_ 975 HBFS_Unlock_Taster 3;
BA_ "GenSigSwitchedByIgnition" SG_ 975 HBFS_Unlock_Taster 0;
BA_ "GenSigSendType" SG_ 975 HBFS_Unten_Block_erw 3;
BA_ "GenSigSwitchedByIgnition" SG_ 975 HBFS_Unten_Block_erw 0;
BA_ "GenSigSendType" SG_ 975 HBFS_verriegelt 3;
BA_ "GenSigSwitchedByIgnition" SG_ 975 HBFS_verriegelt 0;
BA_ "GenSigSendType" SG_ 975 HBFS_Zuziehhilfe_aktiv 3;
BA_ "GenSigSwitchedByIgnition" SG_ 975 HBFS_Zuziehhilfe_aktiv 0;
BA_ "GenSigSendType" SG_ 975 MTHBFS_M_Taste 3;
BA_ "GenSigSwitchedByIgnition" SG_ 975 MTHBFS_M_Taste 0;
BA_ "GenSigSendType" SG_ 975 MTHBFS_Pos1 3;
BA_ "GenSigSwitchedByIgnition" SG_ 975 MTHBFS_Pos1 0;
BA_ "GenSigSendType" SG_ 975 MTHBFS_Pos2 3;
BA_ "GenSigSwitchedByIgnition" SG_ 975 MTHBFS_Pos2 0;
BA_ "GenSigSendType" SG_ 975 MTHBFS_Pos3 3;
BA_ "GenSigSwitchedByIgnition" SG_ 975 MTHBFS_Pos3 0;
BA_ "GenSigSendType" SG_ 975 SSR_HBFS_Pos_Unten 0;
BA_ "GenSigSwitchedByIgnition" SG_ 975 SSR_HBFS_Pos_Unten 0;
BA_ "GenSigSendType" SG_ 974 ASW_Warnung_aktiv_HFS 3;
BA_ "GenSigSwitchedByIgnition" SG_ 974 ASW_Warnung_aktiv_HFS 0;
BA_ "GenSigSendType" SG_ 974 HFS_FH_Bew_hoch 3;
BA_ "GenSigSwitchedByIgnition" SG_ 974 HFS_FH_Bew_hoch 0;
BA_ "GenSigSendType" SG_ 974 HFS_FH_Bew_tief 3;
BA_ "GenSigSwitchedByIgnition" SG_ 974 HFS_FH_Bew_tief 0;
BA_ "GenSigSendType" SG_ 974 HFS_FH_Block 3;
BA_ "GenSigSwitchedByIgnition" SG_ 974 HFS_FH_Block 0;
BA_ "GenSigSendType" SG_ 974 HFS_FH_Fang 3;
BA_ "GenSigSwitchedByIgnition" SG_ 974 HFS_FH_Fang 0;
BA_ "GenSigSendType" SG_ 974 HFS_FH_normiert 3;
BA_ "GenSigSwitchedByIgnition" SG_ 974 HFS_FH_normiert 0;
BA_ "GenSigSendType" SG_ 974 HFS_FH_Oeffnung 3;
BA_ "GenSigSwitchedByIgnition" SG_ 974 HFS_FH_Oeffnung 0;
BA_ "GenSigSendType" SG_ 974 HFS_FH_S_AutoHoch 3;
BA_ "GenSigSwitchedByIgnition" SG_ 974 HFS_FH_S_AutoHoch 0;
BA_ "GenSigSendType" SG_ 974 HFS_FH_S_AutoTief 3;
BA_ "GenSigSwitchedByIgnition" SG_ 974 HFS_FH_S_AutoTief 0;
BA_ "GenSigSendType" SG_ 974 HFS_FH_S_HBFS_AutoHoch 3;
BA_ "GenSigSwitchedByIgnition" SG_ 974 HFS_FH_S_HBFS_AutoHoch 0;
BA_ "GenSigSendType" SG_ 974 HFS_FH_S_HBFS_AutoTief 3;
BA_ "GenSigSwitchedByIgnition" SG_ 974 HFS_FH_S_HBFS_AutoTief 0;
BA_ "GenSigSendType" SG_ 974 HFS_FH_S_HBFS_ManHoch 3;
BA_ "GenSigSwitchedByIgnition" SG_ 974 HFS_FH_S_HBFS_ManHoch 0;
BA_ "GenSigSendType" SG_ 974 HFS_FH_S_HBFS_ManTief 3;
BA_ "GenSigSwitchedByIgnition" SG_ 974 HFS_FH_S_HBFS_ManTief 0;
BA_ "GenSigSendType" SG_ 974 HFS_FH_S_ManHoch 3;
BA_ "GenSigSwitchedByIgnition" SG_ 974 HFS_FH_S_ManHoch 0;
BA_ "GenSigSendType" SG_ 974 HFS_FH_S_ManTief 3;
BA_ "GenSigSwitchedByIgnition" SG_ 974 HFS_FH_S_ManTief 0;
BA_ "GenSigSendType" SG_ 974 HFS_FH_Thermo 3;
BA_ "GenSigSwitchedByIgnition" SG_ 974 HFS_FH_Thermo 0;
BA_ "GenSigSendType" SG_ 974 HFS_gesafet 3;
BA_ "GenSigSwitchedByIgnition" SG_ 974 HFS_gesafet 0;
BA_ "GenSigSendType" SG_ 974 HFS_Heckrollotaster_betaetigt 3;
BA_ "GenSigSwitchedByIgnition" SG_ 974 HFS_Heckrollotaster_betaetigt 0;
BA_ "GenSigSendType" SG_ 974 HFS_Lock_Taster 3;
BA_ "GenSigSwitchedByIgnition" SG_ 974 HFS_Lock_Taster 0;
BA_ "GenSigSendType" SG_ 974 HFS_Lock_Taster_inv 3;
BA_ "GenSigSwitchedByIgnition" SG_ 974 HFS_Lock_Taster_inv 0;
BA_ "GenSigSendType" SG_ 974 HFS_MRollo_Schalter 3;
BA_ "GenSigStartValue" SG_ 974 HFS_MRollo_Schalter 6;
BA_ "GenSigSwitchedByIgnition" SG_ 974 HFS_MRollo_Schalter 0;
BA_ "Fehlerwert" SG_ 974 HFS_MRollo_Schalter 7;
BA_ "GenSigSendType" SG_ 974 HFS_Oben_Block_erw 3;
BA_ "GenSigSwitchedByIgnition" SG_ 974 HFS_Oben_Block_erw 0;
BA_ "GenSigSendType" SG_ 974 HFS_SAD_Schalter 3;
BA_ "GenSigStartValue" SG_ 974 HFS_SAD_Schalter 14;
BA_ "GenSigSwitchedByIgnition" SG_ 974 HFS_SAD_Schalter 0;
BA_ "Fehlerwert" SG_ 974 HFS_SAD_Schalter 15;
BA_ "GenSigSendType" SG_ 974 HFS_Seitenrollo_hoch 3;
BA_ "GenSigSwitchedByIgnition" SG_ 974 HFS_Seitenrollo_hoch 0;
BA_ "GenSigSendType" SG_ 974 HFS_Seitenrollo_tief 3;
BA_ "GenSigSwitchedByIgnition" SG_ 974 HFS_Seitenrollo_tief 0;
BA_ "GenSigSendType" SG_ 974 HFS_Sperrklinke 3;
BA_ "GenSigSwitchedByIgnition" SG_ 974 HFS_Sperrklinke 0;
BA_ "GenSigSendType" SG_ 974 HFS_Status_eTAG 0;
BA_ "GenSigSwitchedByIgnition" SG_ 974 HFS_Status_eTAG 0;
BA_ "Fehlerwert" SG_ 974 HFS_Status_eTAG 3;
BA_ "GenSigSendType" SG_ 974 HFS_Status_KiSi 3;
BA_ "GenSigSwitchedByIgnition" SG_ 974 HFS_Status_KiSi 0;
BA_ "GenSigSendType" SG_ 974 HFS_TAG_betaetigt 3;
BA_ "GenSigSwitchedByIgnition" SG_ 974 HFS_TAG_betaetigt 0;
BA_ "GenSigSendType" SG_ 974 HFS_TCR_Mode_aktiv 3;
BA_ "GenSigSwitchedByIgnition" SG_ 974 HFS_TCR_Mode_aktiv 0;
BA_ "GenSigSendType" SG_ 974 HFS_TIG_betaetigt 3;
BA_ "GenSigSwitchedByIgnition" SG_ 974 HFS_TIG_betaetigt 0;
BA_ "GenSigSendType" SG_ 974 HFS_Tuer_geoeffnet 3;
BA_ "GenSigSwitchedByIgnition" SG_ 974 HFS_Tuer_geoeffnet 0;
BA_ "GenSigSendType" SG_ 974 HFS_Tuer_Status 3;
BA_ "GenSigSwitchedByIgnition" SG_ 974 HFS_Tuer_Status 0;
BA_ "Fehlerwert" SG_ 974 HFS_Tuer_Status 3;
BA_ "GenSigSendType" SG_ 974 HFS_Tuer_Status_QBit 0;
BA_ "GenSigSwitchedByIgnition" SG_ 974 HFS_Tuer_Status_QBit 0;
BA_ "GenSigSendType" SG_ 974 HFS_Tueroeffnen_Warnung 3;
BA_ "GenSigSwitchedByIgnition" SG_ 974 HFS_Tueroeffnen_Warnung 0;
BA_ "GenSigSendType" SG_ 974 HFS_Tuerschloss_defekt 0;
BA_ "GenSigSwitchedByIgnition" SG_ 974 HFS_Tuerschloss_defekt 0;
BA_ "GenSigSendType" SG_ 974 HFS_UEKB_aktiviert 3;
BA_ "GenSigSwitchedByIgnition" SG_ 974 HFS_UEKB_aktiviert 0;
BA_ "GenSigSendType" SG_ 974 HFS_Unlock_Taster 3;
BA_ "GenSigSwitchedByIgnition" SG_ 974 HFS_Unlock_Taster 0;
BA_ "GenSigSendType" SG_ 974 HFS_Unten_Block_erw 3;
BA_ "GenSigSwitchedByIgnition" SG_ 974 HFS_Unten_Block_erw 0;
BA_ "GenSigSendType" SG_ 974 HFS_verriegelt 3;
BA_ "GenSigSwitchedByIgnition" SG_ 974 HFS_verriegelt 0;
BA_ "GenSigSendType" SG_ 974 HFS_Zuziehhilfe_aktiv 3;
BA_ "GenSigSwitchedByIgnition" SG_ 974 HFS_Zuziehhilfe_aktiv 0;
BA_ "GenSigSendType" SG_ 974 MTHFS_M_Taste 3;
BA_ "GenSigSwitchedByIgnition" SG_ 974 MTHFS_M_Taste 0;
BA_ "GenSigSendType" SG_ 974 MTHFS_Pos1 3;
BA_ "GenSigSwitchedByIgnition" SG_ 974 MTHFS_Pos1 0;
BA_ "GenSigSendType" SG_ 974 MTHFS_Pos2 3;
BA_ "GenSigSwitchedByIgnition" SG_ 974 MTHFS_Pos2 0;
BA_ "GenSigSendType" SG_ 974 MTHFS_Pos3 3;
BA_ "GenSigSwitchedByIgnition" SG_ 974 MTHFS_Pos3 0;
BA_ "GenSigSendType" SG_ 974 SSR_HFS_Pos_Unten 0;
BA_ "GenSigSwitchedByIgnition" SG_ 974 SSR_HFS_Pos_Unten 0;
BA_ "GenSigSendType" SG_ 618 USS_Fahrer_Texte 3;
BA_ "GenSigSwitchedByIgnition" SG_ 618 USS_Fahrer_Texte 0;
BA_ "GenSigSendType" SG_ 618 USS_Fahrzeit_seit_Pause 0;
BA_ "GenSigStartValue" SG_ 618 USS_Fahrzeit_seit_Pause 1022;
BA_ "GenSigSwitchedByIgnition" SG_ 618 USS_Fahrzeit_seit_Pause 0;
BA_ "Fehlerwert" SG_ 618 USS_Fahrzeit_seit_Pause 1023;
BA_ "GenSigSendType" SG_ 618 USS_MKE_Index 0;
BA_ "GenSigStartValue" SG_ 618 USS_MKE_Index 126;
BA_ "GenSigSwitchedByIgnition" SG_ 618 USS_MKE_Index 0;
BA_ "Fehlerwert" SG_ 618 USS_MKE_Index 127;
BA_ "GenSigSendType" SG_ 618 USS_MKE_Index_Anstieg 0;
BA_ "GenSigStartValue" SG_ 618 USS_MKE_Index_Anstieg 5;
BA_ "GenSigSwitchedByIgnition" SG_ 618 USS_MKE_Index_Anstieg 0;
BA_ "GenSigSendType" SG_ 618 USS_MKE_Index_Quelle_Biometrisch 0;
BA_ "GenSigSwitchedByIgnition" SG_ 618 USS_MKE_Index_Quelle_Biometrisch 0;
BA_ "GenSigSendType" SG_ 618 USS_MKE_Index_Quelle_FBK 0;
BA_ "GenSigSwitchedByIgnition" SG_ 618 USS_MKE_Index_Quelle_FBK 0;
BA_ "GenSigSendType" SG_ 618 USS_MKE_Index_Quelle_LWS_Basis 0;
BA_ "GenSigSwitchedByIgnition" SG_ 618 USS_MKE_Index_Quelle_LWS_Basis 0;
BA_ "GenSigSendType" SG_ 618 USS_MKE_Index_Quelle_LWS_Plus 0;
BA_ "GenSigSwitchedByIgnition" SG_ 618 USS_MKE_Index_Quelle_LWS_Plus 0;
BA_ "GenSigSendType" SG_ 618 USS_MKE_Index_Quelle_MFK 0;
BA_ "GenSigSwitchedByIgnition" SG_ 618 USS_MKE_Index_Quelle_MFK 0;
BA_ "GenSigSendType" SG_ 618 USS_MKE_Risiko 0;
BA_ "GenSigStartValue" SG_ 618 USS_MKE_Risiko 3;
BA_ "GenSigSwitchedByIgnition" SG_ 618 USS_MKE_Risiko 0;
BA_ "GenSigSendType" SG_ 2463978633 VAS_L_01_BZ 0;
BA_ "GenSigFuncType" SG_ 2463978633 VAS_L_01_BZ 1;
BA_ "GenSigSwitchedByIgnition" SG_ 2463978633 VAS_L_01_BZ 0;
BA_ "GenSigSendType" SG_ 2463978633 VAS_L_01_CRC 0;
BA_ "GenSigFuncType" SG_ 2463978633 VAS_L_01_CRC 2;
BA_ "GenSigSwitchedByIgnition" SG_ 2463978633 VAS_L_01_CRC 0;
BA_ "GenSigSendType" SG_ 2463978633 VAS_L_Autobahnview_aktiv 3;
BA_ "GenSigSwitchedByIgnition" SG_ 2463978633 VAS_L_Autobahnview_aktiv 0;
BA_ "GenSigSendType" SG_ 2463978633 VAS_L_Bedien_Master 3;
BA_ "GenSigSwitchedByIgnition" SG_ 2463978633 VAS_L_Bedien_Master 0;
BA_ "GenSigSendType" SG_ 2463978633 VAS_L_Heizung_Aktiv 3;
BA_ "GenSigSwitchedByIgnition" SG_ 2463978633 VAS_L_Heizung_Aktiv 0;
BA_ "Fehlerwert" SG_ 2463978633 VAS_L_Heizung_Aktiv 127;
BA_ "GenSigSendType" SG_ 2463978633 VAS_L_HMI_Aktiv 3;
BA_ "GenSigSwitchedByIgnition" SG_ 2463978633 VAS_L_HMI_Aktiv 0;
BA_ "GenSigSendType" SG_ 2463978633 VAS_L_Parkview_aktiv 3;
BA_ "GenSigSwitchedByIgnition" SG_ 2463978633 VAS_L_Parkview_aktiv 0;
BA_ "GenSigSendType" SG_ 2463978633 VAS_L_Spiegelauswahl 3;
BA_ "GenSigSwitchedByIgnition" SG_ 2463978633 VAS_L_Spiegelauswahl 0;
BA_ "GenSigSendType" SG_ 2463978633 VAS_L_SWA_HMI_Diagnose 0;
BA_ "GenSigSwitchedByIgnition" SG_ 2463978633 VAS_L_SWA_HMI_Diagnose 0;
BA_ "GenSigSendType" SG_ 2463978633 VAS_L_Texte 3;
BA_ "GenSigStartValue" SG_ 2463978633 VAS_L_Texte 7;
BA_ "GenSigSwitchedByIgnition" SG_ 2463978633 VAS_L_Texte 0;
BA_ "GenSigSendType" SG_ 2463978633 VAS_L_Turnview_aktiv 3;
BA_ "GenSigSwitchedByIgnition" SG_ 2463978633 VAS_L_Turnview_aktiv 0;
BA_ "GenSigSendType" SG_ 2463978633 VAS_L_Verstell_Pos_X 3;
BA_ "GenSigSwitchedByIgnition" SG_ 2463978633 VAS_L_Verstell_Pos_X 0;
BA_ "Fehlerwert" SG_ 2463978633 VAS_L_Verstell_Pos_X 511;
BA_ "GenSigSendType" SG_ 2463978633 VAS_L_Verstell_Pos_Y 3;
BA_ "GenSigSwitchedByIgnition" SG_ 2463978633 VAS_L_Verstell_Pos_Y 0;
BA_ "Fehlerwert" SG_ 2463978633 VAS_L_Verstell_Pos_Y 511;
BA_ "GenSigSendType" SG_ 2463978633 VAS_L_Zoom_Level 3;
BA_ "GenSigSwitchedByIgnition" SG_ 2463978633 VAS_L_Zoom_Level 0;
BA_ "Fehlerwert" SG_ 2463978633 VAS_L_Zoom_Level 127;
BA_ "GenSigSendType" SG_ 2463978634 VAS_R_01_BZ 0;
BA_ "GenSigFuncType" SG_ 2463978634 VAS_R_01_BZ 1;
BA_ "GenSigSwitchedByIgnition" SG_ 2463978634 VAS_R_01_BZ 0;
BA_ "GenSigSendType" SG_ 2463978634 VAS_R_01_CRC 0;
BA_ "GenSigFuncType" SG_ 2463978634 VAS_R_01_CRC 2;
BA_ "GenSigSwitchedByIgnition" SG_ 2463978634 VAS_R_01_CRC 0;
BA_ "GenSigSendType" SG_ 2463978634 VAS_R_Autobahnview_aktiv 3;
BA_ "GenSigSwitchedByIgnition" SG_ 2463978634 VAS_R_Autobahnview_aktiv 0;
BA_ "GenSigSendType" SG_ 2463978634 VAS_R_Bedien_Master 3;
BA_ "GenSigSwitchedByIgnition" SG_ 2463978634 VAS_R_Bedien_Master 0;
BA_ "GenSigSendType" SG_ 2463978634 VAS_R_Fahrerwarnung 3;
BA_ "GenSigStartValue" SG_ 2463978634 VAS_R_Fahrerwarnung 7;
BA_ "GenSigSwitchedByIgnition" SG_ 2463978634 VAS_R_Fahrerwarnung 0;
BA_ "GenSigSendType" SG_ 2463978634 VAS_R_Heizung_Aktiv 3;
BA_ "GenSigSwitchedByIgnition" SG_ 2463978634 VAS_R_Heizung_Aktiv 0;
BA_ "Fehlerwert" SG_ 2463978634 VAS_R_Heizung_Aktiv 127;
BA_ "GenSigSendType" SG_ 2463978634 VAS_R_HMI_Aktiv 3;
BA_ "GenSigSwitchedByIgnition" SG_ 2463978634 VAS_R_HMI_Aktiv 0;
BA_ "GenSigSendType" SG_ 2463978634 VAS_R_Parkview_aktiv 3;
BA_ "GenSigSwitchedByIgnition" SG_ 2463978634 VAS_R_Parkview_aktiv 0;
BA_ "GenSigSendType" SG_ 2463978634 VAS_R_Spiegelauswahl 3;
BA_ "GenSigSwitchedByIgnition" SG_ 2463978634 VAS_R_Spiegelauswahl 0;
BA_ "GenSigSendType" SG_ 2463978634 VAS_R_SWA_HMI_Diagnose 0;
BA_ "GenSigSwitchedByIgnition" SG_ 2463978634 VAS_R_SWA_HMI_Diagnose 0;
BA_ "GenSigSendType" SG_ 2463978634 VAS_R_Turnview_aktiv 3;
BA_ "GenSigSwitchedByIgnition" SG_ 2463978634 VAS_R_Turnview_aktiv 0;
BA_ "GenSigSendType" SG_ 2463978634 VAS_R_Verstell_Pos_X 3;
BA_ "GenSigSwitchedByIgnition" SG_ 2463978634 VAS_R_Verstell_Pos_X 0;
BA_ "Fehlerwert" SG_ 2463978634 VAS_R_Verstell_Pos_X 511;
BA_ "GenSigSendType" SG_ 2463978634 VAS_R_Verstell_Pos_Y 3;
BA_ "GenSigSwitchedByIgnition" SG_ 2463978634 VAS_R_Verstell_Pos_Y 0;
BA_ "Fehlerwert" SG_ 2463978634 VAS_R_Verstell_Pos_Y 511;
BA_ "GenSigSendType" SG_ 2463978634 VAS_R_Zoom_Level 3;
BA_ "GenSigStartValue" SG_ 2463978634 VAS_R_Zoom_Level 70;
BA_ "GenSigSwitchedByIgnition" SG_ 2463978634 VAS_R_Zoom_Level 0;
BA_ "Fehlerwert" SG_ 2463978634 VAS_R_Zoom_Level 127;
BA_ "GenSigSendType" SG_ 995 VD_SpannungsAnf 3;
BA_ "GenSigSwitchedByIgnition" SG_ 995 VD_SpannungsAnf 0;
BA_ "GenSigSendType" SG_ 995 Verdeck_01_BZ 0;
BA_ "GenSigFuncType" SG_ 995 Verdeck_01_BZ 1;
BA_ "GenSigSwitchedByIgnition" SG_ 995 Verdeck_01_BZ 0;
BA_ "GenSigSendType" SG_ 995 Verdeck_01_CRC 0;
BA_ "GenSigFuncType" SG_ 995 Verdeck_01_CRC 2;
BA_ "GenSigActiveRepetitions" SG_ 995 VS_BFS_AutoHoch 5;
BA_ "GenSigSendType" SG_ 995 VS_BFS_AutoHoch 4;
BA_ "GenSigSwitchedByIgnition" SG_ 995 VS_BFS_AutoHoch 0;
BA_ "GenSigActiveRepetitions" SG_ 995 VS_BFS_AutoTief 5;
BA_ "GenSigSendType" SG_ 995 VS_BFS_AutoTief 4;
BA_ "GenSigSwitchedByIgnition" SG_ 995 VS_BFS_AutoTief 0;
BA_ "GenSigActiveRepetitions" SG_ 995 VS_BFS_ManHoch 5;
BA_ "GenSigSendType" SG_ 995 VS_BFS_ManHoch 4;
BA_ "GenSigSwitchedByIgnition" SG_ 995 VS_BFS_ManHoch 0;
BA_ "GenSigActiveRepetitions" SG_ 995 VS_BFS_ManTief 5;
BA_ "GenSigSendType" SG_ 995 VS_BFS_ManTief 4;
BA_ "GenSigSwitchedByIgnition" SG_ 995 VS_BFS_ManTief 0;
BA_ "GenSigSendType" SG_ 995 VS_Buzzer 3;
BA_ "GenSigSwitchedByIgnition" SG_ 995 VS_Buzzer 0;
BA_ "GenSigSendType" SG_ 995 VS_FH_BT_Langhub 3;
BA_ "GenSigSwitchedByIgnition" SG_ 995 VS_FH_BT_Langhub 0;
BA_ "GenSigSendType" SG_ 995 VS_FH_FT_Langhub 3;
BA_ "GenSigSwitchedByIgnition" SG_ 995 VS_FH_FT_Langhub 0;
BA_ "GenSigSendType" SG_ 995 VS_FH_HBFS_Langhub 3;
BA_ "GenSigSwitchedByIgnition" SG_ 995 VS_FH_HBFS_Langhub 0;
BA_ "GenSigSendType" SG_ 995 VS_FH_HFS_Langhub 3;
BA_ "GenSigSwitchedByIgnition" SG_ 995 VS_FH_HFS_Langhub 0;
BA_ "GenSigActiveRepetitions" SG_ 995 VS_FS_AutoHoch 5;
BA_ "GenSigSendType" SG_ 995 VS_FS_AutoHoch 4;
BA_ "GenSigSwitchedByIgnition" SG_ 995 VS_FS_AutoHoch 0;
BA_ "GenSigActiveRepetitions" SG_ 995 VS_FS_AutoTief 5;
BA_ "GenSigSendType" SG_ 995 VS_FS_AutoTief 4;
BA_ "GenSigSwitchedByIgnition" SG_ 995 VS_FS_AutoTief 0;
BA_ "GenSigActiveRepetitions" SG_ 995 VS_FS_ManHoch 5;
BA_ "GenSigSendType" SG_ 995 VS_FS_ManHoch 4;
BA_ "GenSigSwitchedByIgnition" SG_ 995 VS_FS_ManHoch 0;
BA_ "GenSigActiveRepetitions" SG_ 995 VS_FS_ManTief 5;
BA_ "GenSigSendType" SG_ 995 VS_FS_ManTief 4;
BA_ "GenSigSwitchedByIgnition" SG_ 995 VS_FS_ManTief 0;
BA_ "GenSigSendType" SG_ 995 VS_Hardtop 3;
BA_ "GenSigSwitchedByIgnition" SG_ 995 VS_Hardtop 0;
BA_ "GenSigActiveRepetitions" SG_ 995 VS_HBFS_AutoHoch 5;
BA_ "GenSigSendType" SG_ 995 VS_HBFS_AutoHoch 4;
BA_ "GenSigSwitchedByIgnition" SG_ 995 VS_HBFS_AutoHoch 0;
BA_ "GenSigActiveRepetitions" SG_ 995 VS_HBFS_AutoTief 5;
BA_ "GenSigSendType" SG_ 995 VS_HBFS_AutoTief 4;
BA_ "GenSigSwitchedByIgnition" SG_ 995 VS_HBFS_AutoTief 0;
BA_ "GenSigActiveRepetitions" SG_ 995 VS_HBFS_ManHoch 5;
BA_ "GenSigSendType" SG_ 995 VS_HBFS_ManHoch 4;
BA_ "GenSigSwitchedByIgnition" SG_ 995 VS_HBFS_ManHoch 0;
BA_ "GenSigActiveRepetitions" SG_ 995 VS_HBFS_ManTief 5;
BA_ "GenSigSendType" SG_ 995 VS_HBFS_ManTief 4;
BA_ "GenSigSwitchedByIgnition" SG_ 995 VS_HBFS_ManTief 0;
BA_ "GenSigSendType" SG_ 995 VS_HD_sperren 3;
BA_ "GenSigSwitchedByIgnition" SG_ 995 VS_HD_sperren 0;
BA_ "GenSigSendType" SG_ 995 VS_Heckschloss_auf 3;
BA_ "GenSigSwitchedByIgnition" SG_ 995 VS_Heckschloss_auf 0;
BA_ "GenSigActiveRepetitions" SG_ 995 VS_HFS_AutoHoch 5;
BA_ "GenSigSendType" SG_ 995 VS_HFS_AutoHoch 4;
BA_ "GenSigSwitchedByIgnition" SG_ 995 VS_HFS_AutoHoch 0;
BA_ "GenSigActiveRepetitions" SG_ 995 VS_HFS_AutoTief 5;
BA_ "GenSigSendType" SG_ 995 VS_HFS_AutoTief 4;
BA_ "GenSigSwitchedByIgnition" SG_ 995 VS_HFS_AutoTief 0;
BA_ "GenSigActiveRepetitions" SG_ 995 VS_HFS_ManHoch 5;
BA_ "GenSigSendType" SG_ 995 VS_HFS_ManHoch 4;
BA_ "GenSigSwitchedByIgnition" SG_ 995 VS_HFS_ManHoch 0;
BA_ "GenSigActiveRepetitions" SG_ 995 VS_HFS_ManTief 5;
BA_ "GenSigSendType" SG_ 995 VS_HFS_ManTief 4;
BA_ "GenSigSwitchedByIgnition" SG_ 995 VS_HFS_ManTief 0;
BA_ "GenSigSendType" SG_ 995 VS_HHS_enable 3;
BA_ "GenSigSwitchedByIgnition" SG_ 995 VS_HHS_enable 0;
BA_ "GenSigSendType" SG_ 995 VS_Lampe_Blk 3;
BA_ "GenSigSwitchedByIgnition" SG_ 995 VS_Lampe_Blk 0;
BA_ "GenSigSendType" SG_ 995 VS_StartStopp_Info 3;
BA_ "GenSigSwitchedByIgnition" SG_ 995 VS_StartStopp_Info 0;
BA_ "Fehlerwert" SG_ 995 VS_StartStopp_Info 3;
BA_ "GenSigSendType" SG_ 995 VS_VD_Bew_auf 3;
BA_ "GenSigSwitchedByIgnition" SG_ 995 VS_VD_Bew_auf 0;
BA_ "GenSigSendType" SG_ 995 VS_VD_Bew_zu 3;
BA_ "GenSigSwitchedByIgnition" SG_ 995 VS_VD_Bew_zu 0;
BA_ "GenSigSendType" SG_ 995 VS_VD_entriegelt 3;
BA_ "GenSigSwitchedByIgnition" SG_ 995 VS_VD_entriegelt 0;
BA_ "GenSigSendType" SG_ 995 VS_VD_Fehler 3;
BA_ "GenSigSwitchedByIgnition" SG_ 995 VS_VD_Fehler 0;
BA_ "GenSigSendType" SG_ 995 VS_VD_offen_ver 3;
BA_ "GenSigSwitchedByIgnition" SG_ 995 VS_VD_offen_ver 0;
BA_ "GenSigSendType" SG_ 995 VS_VD_zu_ver 3;
BA_ "GenSigSwitchedByIgnition" SG_ 995 VS_VD_zu_ver 0;
BA_ "GenSigSendType" SG_ 995 VS_VD_Zwischenposition 3;
BA_ "GenSigSwitchedByIgnition" SG_ 995 VS_VD_Zwischenposition 0;
BA_ "GenSigSendType" SG_ 995 VS_VDKD_auf 3;
BA_ "GenSigSwitchedByIgnition" SG_ 995 VS_VDKD_auf 0;
BA_ "GenSigSendType" SG_ 995 VS_Verdeck_Anf 3;
BA_ "GenSigSwitchedByIgnition" SG_ 995 VS_Verdeck_Anf 0;
BA_ "GenSigSendType" SG_ 995 VS_Windschott_nicht_abgelegt 3;
BA_ "GenSigSwitchedByIgnition" SG_ 995 VS_Windschott_nicht_abgelegt 0;
BA_ "GenSigSendType" SG_ 995 VSG_Meldungen 3;
BA_ "GenSigSwitchedByIgnition" SG_ 995 VSG_Meldungen 0;
BA_ "GenSigSwitchedByIgnition" SG_ 1716 KS_Geheimnis_1 0;
BA_ "GenSigSwitchedByIgnition" SG_ 1716 KS_Geheimnis_2 0;
BA_ "GenSigSwitchedByIgnition" SG_ 1716 KS_Geheimnis_3 0;
BA_ "GenSigSwitchedByIgnition" SG_ 1716 KS_Geheimnis_4 0;
BA_ "GenSigSendType" SG_ 1716 VIN_01_MUX 0;
BA_ "GenSigSwitchedByIgnition" SG_ 1716 VIN_01_MUX 0;
BA_ "GenSigStartValue" SG_ 1716 VIN_1 45;
BA_ "GenSigSwitchedByIgnition" SG_ 1716 VIN_1 0;
BA_ "GenSigStartValue" SG_ 1716 VIN_10 45;
BA_ "GenSigSwitchedByIgnition" SG_ 1716 VIN_10 0;
BA_ "GenSigStartValue" SG_ 1716 VIN_11 45;
BA_ "GenSigSwitchedByIgnition" SG_ 1716 VIN_11 0;
BA_ "GenSigStartValue" SG_ 1716 VIN_12 45;
BA_ "GenSigSwitchedByIgnition" SG_ 1716 VIN_12 0;
BA_ "GenSigStartValue" SG_ 1716 VIN_13 45;
BA_ "GenSigSwitchedByIgnition" SG_ 1716 VIN_13 0;
BA_ "GenSigStartValue" SG_ 1716 VIN_14 45;
BA_ "GenSigSwitchedByIgnition" SG_ 1716 VIN_14 0;
BA_ "GenSigStartValue" SG_ 1716 VIN_15 45;
BA_ "GenSigSwitchedByIgnition" SG_ 1716 VIN_15 0;
BA_ "GenSigStartValue" SG_ 1716 VIN_16 45;
BA_ "GenSigSwitchedByIgnition" SG_ 1716 VIN_16 0;
BA_ "GenSigStartValue" SG_ 1716 VIN_17 45;
BA_ "GenSigSwitchedByIgnition" SG_ 1716 VIN_17 0;
BA_ "GenSigStartValue" SG_ 1716 VIN_2 45;
BA_ "GenSigSwitchedByIgnition" SG_ 1716 VIN_2 0;
BA_ "GenSigStartValue" SG_ 1716 VIN_3 45;
BA_ "GenSigSwitchedByIgnition" SG_ 1716 VIN_3 0;
BA_ "GenSigStartValue" SG_ 1716 VIN_4 45;
BA_ "GenSigSwitchedByIgnition" SG_ 1716 VIN_4 0;
BA_ "GenSigStartValue" SG_ 1716 VIN_5 45;
BA_ "GenSigSwitchedByIgnition" SG_ 1716 VIN_5 0;
BA_ "GenSigStartValue" SG_ 1716 VIN_6 45;
BA_ "GenSigSwitchedByIgnition" SG_ 1716 VIN_6 0;
BA_ "GenSigStartValue" SG_ 1716 VIN_7 45;
BA_ "GenSigSwitchedByIgnition" SG_ 1716 VIN_7 0;
BA_ "GenSigStartValue" SG_ 1716 VIN_8 45;
BA_ "GenSigSwitchedByIgnition" SG_ 1716 VIN_8 0;
BA_ "GenSigStartValue" SG_ 1716 VIN_9 45;
BA_ "GenSigSwitchedByIgnition" SG_ 1716 VIN_9 0;
BA_ "GenSigSendType" SG_ 1702 BCM1_SRA_aktiv 3;
BA_ "GenSigSwitchedByIgnition" SG_ 1702 BCM1_SRA_aktiv 0;
BA_ "GenSigActiveRepetitions" SG_ 1702 Heckwischer_Anforderung 3;
BA_ "GenSigSendType" SG_ 1702 Heckwischer_Anforderung 4;
BA_ "GenSigSwitchedByIgnition" SG_ 1702 Heckwischer_Anforderung 0;
BA_ "GenSigSendType" SG_ 1702 Waschen_vorne_aktiv 3;
BA_ "GenSigSwitchedByIgnition" SG_ 1702 Waschen_vorne_aktiv 0;
BA_ "GenSigSendType" SG_ 1702 Wischer1_Wischgeschwindigkeit 0;
BA_ "GenSigStartValue" SG_ 1702 Wischer1_Wischgeschwindigkeit 62;
BA_ "GenSigSwitchedByIgnition" SG_ 1702 Wischer1_Wischgeschwindigkeit 0;
BA_ "Fehlerwert" SG_ 1702 Wischer1_Wischgeschwindigkeit 63;
BA_ "GenSigSendType" SG_ 1702 Wischer_Anzeigetext 3;
BA_ "GenSigSwitchedByIgnition" SG_ 1702 Wischer_Anzeigetext 0;
BA_ "GenSigSendType" SG_ 1702 Wischer_vorne_aktiv 3;
BA_ "GenSigSwitchedByIgnition" SG_ 1702 Wischer_vorne_aktiv 0;
BA_ "GenSigSendType" SG_ 1702 Wischer_vorne_blockiert 3;
BA_ "GenSigSwitchedByIgnition" SG_ 1702 Wischer_vorne_blockiert 0;
BA_ "GenSigSendType" SG_ 1702 Wischer_vorne_defekt 3;
BA_ "GenSigSwitchedByIgnition" SG_ 1702 Wischer_vorne_defekt 0;
BA_ "GenSigSendType" SG_ 1702 Wischer_vorne_Normal 3;
BA_ "GenSigSwitchedByIgnition" SG_ 1702 Wischer_vorne_Normal 0;
BA_ "GenSigSendType" SG_ 1702 Wischer_vorne_Parklage 3;
BA_ "GenSigStartValue" SG_ 1702 Wischer_vorne_Parklage 1;
BA_ "GenSigSwitchedByIgnition" SG_ 1702 Wischer_vorne_Parklage 0;
BA_ "GenSigSendType" SG_ 1702 Wischer_vorne_Schnell 3;
BA_ "GenSigSwitchedByIgnition" SG_ 1702 Wischer_vorne_Schnell 0;
BA_ "GenSigSendType" SG_ 1702 WWSs_01_upd 0;
BA_ "GenSigFuncType" SG_ 1702 WWSs_01_upd 5;
BA_ "GenSigSwitchedByIgnition" SG_ 1702 WWSs_01_upd 0;
BA_ "GenSigSwitchedByIgnition" SG_ 2617079296 XCP_AEM_CRO_01_Data 0;
BA_ "GenSigSwitchedByIgnition" SG_ 2617083392 XCP_FLA_CRO_01_Data 0;
BA_ "GenSigSwitchedByIgnition" SG_ 2617064960 XCP_Nightvision_CRO_01_Data 0;
BA_ "GenSigSwitchedByIgnition" SG_ 2617007616 XCP_RDK_CRO_01_Data 0;
BA_ "GenSigSwitchedByIgnition" SG_ 2617007617 XCP_RDK_DTO_01_Data 0;
BA_ "GenSigSwitchedByIgnition" SG_ 2617200128 XCP_TopView_CRO_01_Data 0;
BA_ "GenSigSwitchedByIgnition" SG_ 2617200129 XCP_TopView_DTO_01_Data 0;
BA_ "GenSigSwitchedByIgnition" SG_ 2617071104 XCP_SCR_CRO_01_Data 0;
BA_ "GenSigSwitchedByIgnition" SG_ 2617071105 XCP_SCR_DTO_01_Data 0;
BA_ "GenSigSwitchedByIgnition" SG_ 2617202176 XCP_STH_CRO_01_Data 0;
BA_ "GenSigSwitchedByIgnition" SG_ 2617202177 XCP_STH_DTO_01_Data 0;
BA_ "GenSigSwitchedByIgnition" SG_ 2617005824 XCP_SWA_2_CRO_01_Data 0;
BA_ "GenSigSwitchedByIgnition" SG_ 2617005825 XCP_SWA_2_DTO_01_Data 0;
BA_ "GenSigSwitchedByIgnition" SG_ 2617144832 XCP_SWA_CRO_01_Data 0;
BA_ "GenSigSwitchedByIgnition" SG_ 2617144833 XCP_SWA_DTO_01_Data 0;
BA_ "GenSigSendType" SG_ 1411 BCM_FH_Freigabe 3;
BA_ "GenSigSwitchedByIgnition" SG_ 1411 BCM_FH_Freigabe 0;
BA_ "GenSigSendType" SG_ 1411 BCM_HSK_Freigabe 3;
BA_ "GenSigSwitchedByIgnition" SG_ 1411 BCM_HSK_Freigabe 0;
BA_ "GenSigSendType" SG_ 1411 BCM_Komfortfkt_Freigabe 3;
BA_ "GenSigSwitchedByIgnition" SG_ 1411 BCM_Komfortfkt_Freigabe 0;
BA_ "GenSigSendType" SG_ 1411 BCM_Tankklappensteller_Fehler 0;
BA_ "GenSigSwitchedByIgnition" SG_ 1411 BCM_Tankklappensteller_Fehler 0;
BA_ "Fehlerwert" SG_ 1411 BCM_Tankklappensteller_Fehler 1;
BA_ "GenSigSendType" SG_ 1411 BCM_Verdeck_Freigabe 3;
BA_ "GenSigSwitchedByIgnition" SG_ 1411 BCM_Verdeck_Freigabe 0;
BA_ "GenSigSendType" SG_ 1411 DWA_aktiv 3;
BA_ "GenSigSwitchedByIgnition" SG_ 1411 DWA_aktiv 0;
BA_ "GenSigSendType" SG_ 1411 FBS_Warn_Schluessel_Batt 3;
BA_ "GenSigSwitchedByIgnition" SG_ 1411 FBS_Warn_Schluessel_Batt 0;
BA_ "GenSigActiveRepetitions" SG_ 1411 FFB_CarFinder 5;
BA_ "GenSigSendType" SG_ 1411 FFB_CarFinder 2;
BA_ "GenSigSwitchedByIgnition" SG_ 1411 FFB_CarFinder 0;
BA_ "GenSigActiveRepetitions" SG_ 1411 FFB_Komfortoeffnen 5;
BA_ "GenSigSendType" SG_ 1411 FFB_Komfortoeffnen 2;
BA_ "GenSigSwitchedByIgnition" SG_ 1411 FFB_Komfortoeffnen 0;
BA_ "GenSigActiveRepetitions" SG_ 1411 FFB_Komfortschliessen 5;
BA_ "GenSigSendType" SG_ 1411 FFB_Komfortschliessen 2;
BA_ "GenSigSwitchedByIgnition" SG_ 1411 FFB_Komfortschliessen 0;
BA_ "GenSigSendType" SG_ 1411 HBFS_gesafet 3;
BA_ "GenSigSwitchedByIgnition" SG_ 1411 HBFS_gesafet 0;
BA_ "GenSigSendType" SG_ 1411 HBFS_verriegelt 3;
BA_ "GenSigSwitchedByIgnition" SG_ 1411 HBFS_verriegelt 0;
BA_ "GenSigSendType" SG_ 1411 HD_Hauptraste 3;
BA_ "GenSigSwitchedByIgnition" SG_ 1411 HD_Hauptraste 0;
BA_ "GenSigSendType" SG_ 1411 HD_Vorraste 3;
BA_ "GenSigSwitchedByIgnition" SG_ 1411 HD_Vorraste 0;
BA_ "GenSigSendType" SG_ 1411 HFS_gesafet 3;
BA_ "GenSigSwitchedByIgnition" SG_ 1411 HFS_gesafet 0;
BA_ "GenSigSendType" SG_ 1411 HFS_verriegelt 3;
BA_ "GenSigSwitchedByIgnition" SG_ 1411 HFS_verriegelt 0;
BA_ "GenSigSendType" SG_ 1411 IRUE_aktiv 3;
BA_ "GenSigSwitchedByIgnition" SG_ 1411 IRUE_aktiv 0;
BA_ "GenSigSendType" SG_ 1411 IRUE_Taster_Fkts_LED 3;
BA_ "GenSigSwitchedByIgnition" SG_ 1411 IRUE_Taster_Fkts_LED 0;
BA_ "GenSigSendType" SG_ 1411 ZV_BT_offen 3;
BA_ "GenSigSwitchedByIgnition" SG_ 1411 ZV_BT_offen 0;
BA_ "GenSigSendType" SG_ 1411 ZV_Einzeltuerentriegelung 3;
BA_ "GenSigSwitchedByIgnition" SG_ 1411 ZV_Einzeltuerentriegelung 0;
BA_ "GenSigSendType" SG_ 1411 ZV_FT_offen 3;
BA_ "GenSigSwitchedByIgnition" SG_ 1411 ZV_FT_offen 0;
BA_ "GenSigSendType" SG_ 1411 ZV_gesafet_extern_ist 3;
BA_ "GenSigSwitchedByIgnition" SG_ 1411 ZV_gesafet_extern_ist 0;
BA_ "GenSigSendType" SG_ 1411 ZV_gesafet_extern_soll 3;
BA_ "GenSigSwitchedByIgnition" SG_ 1411 ZV_gesafet_extern_soll 0;
BA_ "GenSigSendType" SG_ 1411 ZV_HBFS_offen 3;
BA_ "GenSigSwitchedByIgnition" SG_ 1411 ZV_HBFS_offen 0;
BA_ "GenSigSendType" SG_ 1411 ZV_HD_offen 3;
BA_ "GenSigSwitchedByIgnition" SG_ 1411 ZV_HD_offen 0;
BA_ "GenSigSendType" SG_ 1411 ZV_Heckeinzelentriegelung 3;
BA_ "GenSigSwitchedByIgnition" SG_ 1411 ZV_Heckeinzelentriegelung 0;
BA_ "GenSigSendType" SG_ 1411 ZV_HFS_offen 3;
BA_ "GenSigSwitchedByIgnition" SG_ 1411 ZV_HFS_offen 0;
BA_ "GenSigSendType" SG_ 1411 ZV_HS_offen 3;
BA_ "GenSigSwitchedByIgnition" SG_ 1411 ZV_HS_offen 0;
BA_ "GenSigSendType" SG_ 1411 ZV_ist_Zustand_verfuegbar 3;
BA_ "GenSigSwitchedByIgnition" SG_ 1411 ZV_ist_Zustand_verfuegbar 0;
BA_ "GenSigSendType" SG_ 1411 ZV_Oeffnungsmodus 3;
BA_ "GenSigSwitchedByIgnition" SG_ 1411 ZV_Oeffnungsmodus 0;
BA_ "GenSigSendType" SG_ 1411 ZV_Rollo_auf 3;
BA_ "GenSigSwitchedByIgnition" SG_ 1411 ZV_Rollo_auf 0;
BA_ "GenSigSendType" SG_ 1411 ZV_Rollo_zu 3;
BA_ "GenSigSwitchedByIgnition" SG_ 1411 ZV_Rollo_zu 0;
BA_ "GenSigSendType" SG_ 1411 ZV_SAD_auf 3;
BA_ "GenSigSwitchedByIgnition" SG_ 1411 ZV_SAD_auf 0;
BA_ "GenSigSendType" SG_ 1411 ZV_SAD_zu 3;
BA_ "GenSigSwitchedByIgnition" SG_ 1411 ZV_SAD_zu 0;
BA_ "GenSigSendType" SG_ 1411 ZV_SafeFunktion_aktiv 3;
BA_ "GenSigSwitchedByIgnition" SG_ 1411 ZV_SafeFunktion_aktiv 0;
BA_ "GenSigActiveRepetitions" SG_ 1411 ZV_Schluessel_Zugang 5;
BA_ "GenSigSendType" SG_ 1411 ZV_Schluessel_Zugang 4;
BA_ "GenSigSwitchedByIgnition" SG_ 1411 ZV_Schluessel_Zugang 0;
BA_ "GenSigSendType" SG_ 1411 ZV_Tankklappe_offen 0;
BA_ "GenSigSwitchedByIgnition" SG_ 1411 ZV_Tankklappe_offen 0;
BA_ "GenSigSendType" SG_ 1411 ZV_verriegelt_extern_ist 3;
BA_ "GenSigSwitchedByIgnition" SG_ 1411 ZV_verriegelt_extern_ist 0;
BA_ "GenSigSendType" SG_ 1411 ZV_verriegelt_extern_soll 3;
BA_ "GenSigSwitchedByIgnition" SG_ 1411 ZV_verriegelt_extern_soll 0;
BA_ "GenSigSendType" SG_ 1411 ZV_verriegelt_intern_ist 3;
BA_ "GenSigSwitchedByIgnition" SG_ 1411 ZV_verriegelt_intern_ist 0;
BA_ "GenSigSendType" SG_ 1411 ZV_verriegelt_intern_soll 3;
BA_ "GenSigSwitchedByIgnition" SG_ 1411 ZV_verriegelt_intern_soll 0;
BA_ "GenSigSendType" SG_ 1411 ZV_verriegelt_soll 3;
BA_ "GenSigSwitchedByIgnition" SG_ 1411 ZV_verriegelt_soll 0;
BA_REL_ "GenSigTimeoutTime" BU_SG_REL_ AEM SG_ 1716 VIN_01_MUX 2000;
BA_REL_ "GenSigTimeoutTime" BU_SG_REL_ AEM SG_ 1716 VIN_4 2000;
BA_REL_ "GenSigTimeoutTime" BU_SG_REL_ AEM SG_ 1716 VIN_11 2000;
BA_REL_ "GenSigTimeoutTime" BU_SG_REL_ AEM SG_ 1716 VIN_5 2000;
BA_REL_ "GenSigTimeoutTime" BU_SG_REL_ AEM SG_ 1716 VIN_12 2000;
BA_REL_ "GenSigTimeoutTime" BU_SG_REL_ AEM SG_ 1716 VIN_6 2000;
BA_REL_ "GenSigTimeoutTime" BU_SG_REL_ AEM SG_ 1716 VIN_13 2000;
BA_REL_ "GenSigTimeoutTime" BU_SG_REL_ AEM SG_ 1716 VIN_7 2000;
BA_REL_ "GenSigTimeoutTime" BU_SG_REL_ AEM SG_ 1716 VIN_14 2000;
BA_REL_ "GenSigTimeoutTime" BU_SG_REL_ AEM SG_ 1716 VIN_1 2000;
BA_REL_ "GenSigTimeoutTime" BU_SG_REL_ AEM SG_ 1716 VIN_8 2000;
BA_REL_ "GenSigTimeoutTime" BU_SG_REL_ AEM SG_ 1716 VIN_15 2000;
BA_REL_ "GenSigTimeoutTime" BU_SG_REL_ AEM SG_ 1716 VIN_2 2000;
BA_REL_ "GenSigTimeoutTime" BU_SG_REL_ AEM SG_ 1716 VIN_9 2000;
BA_REL_ "GenSigTimeoutTime" BU_SG_REL_ AEM SG_ 1716 VIN_16 2000;
BA_REL_ "GenSigTimeoutTime" BU_SG_REL_ AEM SG_ 1716 VIN_3 2000;
BA_REL_ "GenSigTimeoutTime" BU_SG_REL_ AEM SG_ 1716 VIN_10 2000;
BA_REL_ "GenSigTimeoutTime" BU_SG_REL_ AEM SG_ 1716 VIN_17 2000;
BA_REL_ "GenSigTimeoutTime" BU_SG_REL_ E_Sound SG_ 1716 VIN_01_MUX 2000;
BA_REL_ "GenSigTimeoutTime" BU_SG_REL_ E_Sound SG_ 1716 VIN_4 2000;
BA_REL_ "GenSigTimeoutTime" BU_SG_REL_ E_Sound SG_ 1716 VIN_11 2000;
BA_REL_ "GenSigTimeoutTime" BU_SG_REL_ E_Sound SG_ 1716 VIN_5 2000;
BA_REL_ "GenSigTimeoutTime" BU_SG_REL_ E_Sound SG_ 1716 VIN_12 2000;
BA_REL_ "GenSigTimeoutTime" BU_SG_REL_ E_Sound SG_ 1716 VIN_6 2000;
BA_REL_ "GenSigTimeoutTime" BU_SG_REL_ E_Sound SG_ 1716 VIN_13 2000;
BA_REL_ "GenSigTimeoutTime" BU_SG_REL_ E_Sound SG_ 1716 VIN_7 2000;
BA_REL_ "GenSigTimeoutTime" BU_SG_REL_ E_Sound SG_ 1716 VIN_14 2000;
BA_REL_ "GenSigTimeoutTime" BU_SG_REL_ E_Sound SG_ 1716 VIN_1 2000;
BA_REL_ "GenSigTimeoutTime" BU_SG_REL_ E_Sound SG_ 1716 VIN_8 2000;
BA_REL_ "GenSigTimeoutTime" BU_SG_REL_ E_Sound SG_ 1716 VIN_15 2000;
BA_REL_ "GenSigTimeoutTime" BU_SG_REL_ E_Sound SG_ 1716 VIN_2 2000;
BA_REL_ "GenSigTimeoutTime" BU_SG_REL_ E_Sound SG_ 1716 VIN_9 2000;
BA_REL_ "GenSigTimeoutTime" BU_SG_REL_ E_Sound SG_ 1716 VIN_16 2000;
BA_REL_ "GenSigTimeoutTime" BU_SG_REL_ E_Sound SG_ 1716 VIN_3 2000;
BA_REL_ "GenSigTimeoutTime" BU_SG_REL_ E_Sound SG_ 1716 VIN_10 2000;
BA_REL_ "GenSigTimeoutTime" BU_SG_REL_ E_Sound SG_ 1716 VIN_17 2000;
BA_REL_ "GenSigTimeoutTime" BU_SG_REL_ FBK SG_ 997 FT_Tuer_Status 1000;
BA_REL_ "GenSigTimeoutTime" BU_SG_REL_ FBK SG_ 997 FT_Tuer_Status_QBit 1000;
BA_REL_ "GenSigTimeoutTime" BU_SG_REL_ ISE SG_ 995 VS_VD_zu_ver 1000;
BA_REL_ "GenSigTimeoutTime" BU_SG_REL_ ISE SG_ 995 VS_VD_offen_ver 1000;
BA_REL_ "GenSigTimeoutTime" BU_SG_REL_ ISE SG_ 1716 VIN_01_MUX 2000;
BA_REL_ "GenSigTimeoutTime" BU_SG_REL_ ISE SG_ 1716 VIN_4 2000;
BA_REL_ "GenSigTimeoutTime" BU_SG_REL_ ISE SG_ 1716 VIN_11 2000;
BA_REL_ "GenSigTimeoutTime" BU_SG_REL_ ISE SG_ 1716 VIN_5 2000;
BA_REL_ "GenSigTimeoutTime" BU_SG_REL_ ISE SG_ 1716 VIN_12 2000;
BA_REL_ "GenSigTimeoutTime" BU_SG_REL_ ISE SG_ 1716 VIN_6 2000;
BA_REL_ "GenSigTimeoutTime" BU_SG_REL_ ISE SG_ 1716 VIN_13 2000;
BA_REL_ "GenSigTimeoutTime" BU_SG_REL_ ISE SG_ 1716 VIN_7 2000;
BA_REL_ "GenSigTimeoutTime" BU_SG_REL_ ISE SG_ 1716 VIN_14 2000;
BA_REL_ "GenSigTimeoutTime" BU_SG_REL_ ISE SG_ 1716 VIN_1 2000;
BA_REL_ "GenSigTimeoutTime" BU_SG_REL_ ISE SG_ 1716 VIN_8 2000;
BA_REL_ "GenSigTimeoutTime" BU_SG_REL_ ISE SG_ 1716 VIN_15 2000;
BA_REL_ "GenSigTimeoutTime" BU_SG_REL_ ISE SG_ 1716 VIN_2 2000;
BA_REL_ "GenSigTimeoutTime" BU_SG_REL_ ISE SG_ 1716 VIN_9 2000;
BA_REL_ "GenSigTimeoutTime" BU_SG_REL_ ISE SG_ 1716 VIN_16 2000;
BA_REL_ "GenSigTimeoutTime" BU_SG_REL_ ISE SG_ 1716 VIN_3 2000;
BA_REL_ "GenSigTimeoutTime" BU_SG_REL_ ISE SG_ 1716 VIN_10 2000;
BA_REL_ "GenSigTimeoutTime" BU_SG_REL_ ISE SG_ 1716 VIN_17 2000;
BA_REL_ "GenSigTimeoutTime" BU_SG_REL_ NightVision SG_ 618 USS_MKE_Risiko 5000;
BA_REL_ "GenSigTimeoutTime" BU_SG_REL_ NightVision SG_ 618 USS_MKE_Index_Anstieg 5000;
BA_REL_ "GenSigTimeoutTime" BU_SG_REL_ NightVision SG_ 618 USS_MKE_Index_Quelle_LWS_Basis 5000;
BA_REL_ "GenSigTimeoutTime" BU_SG_REL_ NightVision SG_ 618 USS_MKE_Index_Quelle_LWS_Plus 5000;
BA_REL_ "GenSigTimeoutTime" BU_SG_REL_ NightVision SG_ 618 USS_MKE_Index_Quelle_MFK 5000;
BA_REL_ "GenSigTimeoutTime" BU_SG_REL_ NightVision SG_ 618 USS_MKE_Index_Quelle_FBK 5000;
BA_REL_ "GenSigTimeoutTime" BU_SG_REL_ NightVision SG_ 618 USS_MKE_Index 5000;
BA_REL_ "GenSigTimeoutTime" BU_SG_REL_ NightVision SG_ 618 USS_MKE_Index_Quelle_Biometrisch 5000;
BA_REL_ "GenSigTimeoutTime" BU_SG_REL_ NightVision SG_ 618 USS_Fahrzeit_seit_Pause 5000;
BA_REL_ "GenSigTimeoutTime" BU_SG_REL_ NightVision SG_ 618 USS_Fahrer_Texte 5000;
BA_REL_ "GenSigTimeoutTime" BU_SG_REL_ NightVision SG_ 1716 VIN_01_MUX 2000;
BA_REL_ "GenSigTimeoutTime" BU_SG_REL_ NightVision SG_ 1716 VIN_4 2000;
BA_REL_ "GenSigTimeoutTime" BU_SG_REL_ NightVision SG_ 1716 VIN_11 2000;
BA_REL_ "GenSigTimeoutTime" BU_SG_REL_ NightVision SG_ 1716 VIN_5 2000;
BA_REL_ "GenSigTimeoutTime" BU_SG_REL_ NightVision SG_ 1716 VIN_12 2000;
BA_REL_ "GenSigTimeoutTime" BU_SG_REL_ NightVision SG_ 1716 VIN_6 2000;
BA_REL_ "GenSigTimeoutTime" BU_SG_REL_ NightVision SG_ 1716 VIN_13 2000;
BA_REL_ "GenSigTimeoutTime" BU_SG_REL_ NightVision SG_ 1716 VIN_7 2000;
BA_REL_ "GenSigTimeoutTime" BU_SG_REL_ NightVision SG_ 1716 VIN_14 2000;
BA_REL_ "GenSigTimeoutTime" BU_SG_REL_ NightVision SG_ 1716 VIN_1 2000;
BA_REL_ "GenSigTimeoutTime" BU_SG_REL_ NightVision SG_ 1716 VIN_8 2000;
BA_REL_ "GenSigTimeoutTime" BU_SG_REL_ NightVision SG_ 1716 VIN_15 2000;
BA_REL_ "GenSigTimeoutTime" BU_SG_REL_ NightVision SG_ 1716 VIN_2 2000;
BA_REL_ "GenSigTimeoutTime" BU_SG_REL_ NightVision SG_ 1716 VIN_9 2000;
BA_REL_ "GenSigTimeoutTime" BU_SG_REL_ NightVision SG_ 1716 VIN_16 2000;
BA_REL_ "GenSigTimeoutTime" BU_SG_REL_ NightVision SG_ 1716 VIN_3 2000;
BA_REL_ "GenSigTimeoutTime" BU_SG_REL_ NightVision SG_ 1716 VIN_10 2000;
BA_REL_ "GenSigTimeoutTime" BU_SG_REL_ NightVision SG_ 1716 VIN_17 2000;
BA_REL_ "GenSigTimeoutTime" BU_SG_REL_ NightVision SG_ 1702 BCM1_SRA_aktiv 5000;
BA_REL_ "GenSigTimeoutTime" BU_SG_REL_ SAK SG_ 995 VS_VD_zu_ver 1000;
BA_REL_ "GenSigTimeoutTime" BU_SG_REL_ SAK SG_ 995 VS_VD_entriegelt 1000;
BA_REL_ "GenSigTimeoutTime" BU_SG_REL_ SAK SG_ 995 VS_VD_offen_ver 1000;
BA_REL_ "GenSigTimeoutTime" BU_SG_REL_ SAK SG_ 995 VS_VD_Zwischenposition 1000;
BA_REL_ "GenSigTimeoutTime" BU_SG_REL_ SAK SG_ 1716 VIN_01_MUX 2000;
BA_REL_ "GenSigTimeoutTime" BU_SG_REL_ SAK SG_ 1716 VIN_4 2000;
BA_REL_ "GenSigTimeoutTime" BU_SG_REL_ SAK SG_ 1716 VIN_11 2000;
BA_REL_ "GenSigTimeoutTime" BU_SG_REL_ SAK SG_ 1716 VIN_5 2000;
BA_REL_ "GenSigTimeoutTime" BU_SG_REL_ SAK SG_ 1716 VIN_12 2000;
BA_REL_ "GenSigTimeoutTime" BU_SG_REL_ SAK SG_ 1716 VIN_6 2000;
BA_REL_ "GenSigTimeoutTime" BU_SG_REL_ SAK SG_ 1716 VIN_13 2000;
BA_REL_ "GenSigTimeoutTime" BU_SG_REL_ SAK SG_ 1716 VIN_7 2000;
BA_REL_ "GenSigTimeoutTime" BU_SG_REL_ SAK SG_ 1716 VIN_14 2000;
BA_REL_ "GenSigTimeoutTime" BU_SG_REL_ SAK SG_ 1716 VIN_1 2000;
BA_REL_ "GenSigTimeoutTime" BU_SG_REL_ SAK SG_ 1716 VIN_8 2000;
BA_REL_ "GenSigTimeoutTime" BU_SG_REL_ SAK SG_ 1716 VIN_15 2000;
BA_REL_ "GenSigTimeoutTime" BU_SG_REL_ SAK SG_ 1716 VIN_2 2000;
BA_REL_ "GenSigTimeoutTime" BU_SG_REL_ SAK SG_ 1716 VIN_9 2000;
BA_REL_ "GenSigTimeoutTime" BU_SG_REL_ SAK SG_ 1716 VIN_16 2000;
BA_REL_ "GenSigTimeoutTime" BU_SG_REL_ SAK SG_ 1716 VIN_3 2000;
BA_REL_ "GenSigTimeoutTime" BU_SG_REL_ SAK SG_ 1716 VIN_10 2000;
BA_REL_ "GenSigTimeoutTime" BU_SG_REL_ SAK SG_ 1716 VIN_17 2000;
BA_REL_ "GenSigTimeoutTime" BU_SG_REL_ SAK2 SG_ 995 VS_VD_zu_ver 1000;
BA_REL_ "GenSigTimeoutTime" BU_SG_REL_ SAK2 SG_ 995 VS_VD_entriegelt 1000;
BA_REL_ "GenSigTimeoutTime" BU_SG_REL_ SAK2 SG_ 995 VS_VD_offen_ver 1000;
BA_REL_ "GenSigTimeoutTime" BU_SG_REL_ SAK2 SG_ 995 VS_VD_Zwischenposition 1000;
BA_REL_ "GenSigTimeoutTime" BU_SG_REL_ SAK2 SG_ 1716 VIN_01_MUX 2000;
BA_REL_ "GenSigTimeoutTime" BU_SG_REL_ SAK2 SG_ 1716 VIN_4 2000;
BA_REL_ "GenSigTimeoutTime" BU_SG_REL_ SAK2 SG_ 1716 VIN_11 2000;
BA_REL_ "GenSigTimeoutTime" BU_SG_REL_ SAK2 SG_ 1716 VIN_5 2000;
BA_REL_ "GenSigTimeoutTime" BU_SG_REL_ SAK2 SG_ 1716 VIN_12 2000;
BA_REL_ "GenSigTimeoutTime" BU_SG_REL_ SAK2 SG_ 1716 VIN_6 2000;
BA_REL_ "GenSigTimeoutTime" BU_SG_REL_ SAK2 SG_ 1716 VIN_13 2000;
BA_REL_ "GenSigTimeoutTime" BU_SG_REL_ SAK2 SG_ 1716 VIN_7 2000;
BA_REL_ "GenSigTimeoutTime" BU_SG_REL_ SAK2 SG_ 1716 VIN_14 2000;
BA_REL_ "GenSigTimeoutTime" BU_SG_REL_ SAK2 SG_ 1716 VIN_1 2000;
BA_REL_ "GenSigTimeoutTime" BU_SG_REL_ SAK2 SG_ 1716 VIN_8 2000;
BA_REL_ "GenSigTimeoutTime" BU_SG_REL_ SAK2 SG_ 1716 VIN_15 2000;
BA_REL_ "GenSigTimeoutTime" BU_SG_REL_ SAK2 SG_ 1716 VIN_2 2000;
BA_REL_ "GenSigTimeoutTime" BU_SG_REL_ SAK2 SG_ 1716 VIN_9 2000;
BA_REL_ "GenSigTimeoutTime" BU_SG_REL_ SAK2 SG_ 1716 VIN_16 2000;
BA_REL_ "GenSigTimeoutTime" BU_SG_REL_ SAK2 SG_ 1716 VIN_3 2000;
BA_REL_ "GenSigTimeoutTime" BU_SG_REL_ SAK2 SG_ 1716 VIN_10 2000;
BA_REL_ "GenSigTimeoutTime" BU_SG_REL_ SAK2 SG_ 1716 VIN_17 2000;
BA_REL_ "GenSigTimeoutTime" BU_SG_REL_ SCR SG_ 1716 VIN_01_MUX 2000;
BA_REL_ "GenSigTimeoutTime" BU_SG_REL_ SCR SG_ 1716 VIN_7 2000;
BA_REL_ "GenSigTimeoutTime" BU_SG_REL_ SCR SG_ 1716 VIN_8 2000;
BA_REL_ "GenSigTimeoutTime" BU_SG_REL_ SCR SG_ 1716 VIN_17 2000;
BA_REL_ "GenSigTimeoutTime" BU_SG_REL_ TopView SG_ 1411 ZV_FT_offen 2000;
BA_REL_ "GenSigTimeoutTime" BU_SG_REL_ TopView SG_ 1411 ZV_BT_offen 2000;
BA_REL_ "GenSigTimeoutTime" BU_SG_REL_ TopView SG_ 1411 ZV_HD_offen 2000;
VAL_ null AB_Sg_Status_02_CompID 217 "Init" ;
VAL_ null BT_Tuer_Status 0 "Init" 1 "Tuer_geschlossen" 2 "Tuer_offen" 3 "Fehler" ;
VAL_ null FT_Tuer_Status 0 "Init" 1 "Tuer_geschlossen" 2 "Tuer_offen" 3 "Fehler" ;
VAL_ null AB_GSCH_Reihe1_FA 0 "nicht_verbaut" 1 "nicht_verfügbar" 2 "nicht_gesteckt" 3 "gesteckt" ;
VAL_ null AB_GSCH_Reihe1_BF 0 "nicht_verbaut" 1 "nicht_verfügbar" 2 "nicht_gesteckt" 3 "gesteckt" ;
VAL_ null VDSO_Vx3d 65534 "Init" 65535 "Fehler" ;
VAL_ 977 BT_Tuer_geoeffnet 0 "geschlossen" 1 "offen" ;
VAL_ 977 BT_verriegelt 0 "Init" 1 "verriegelt" ;
VAL_ 977 BT_gesafet 0 "Init" 1 "gesafet" ;
VAL_ 977 BT_Schluesselschalter_auf 0 "Init" 1 "Schluesselschalter_auf_betaetigt" ;
VAL_ 977 BT_Schluesselschalter_zu 0 "Init" 1 "Schluesselschalter_zu_betaetigt" ;
VAL_ 977 BT_Unlock_Taster 0 "Init" 1 "Unlock_Taster_betaetigt" ;
VAL_ 977 BT_Lock_Taster 0 "Init" 1 "Lock_Taster_betaetigt" ;
VAL_ 977 BT_Sperrklinke 0 "Schloss_in_Vorraste_und_Hauptraste" 1 "Tuer_auf_oder_Tuer_Position_zwischen_Vor_und_Hauptraste" ;
VAL_ 977 BT_TAG_betaetigt 0 "Init" 1 "Tuerinnengriff_betaetigt" ;
VAL_ 977 BT_TIG_betaetigt 0 "Init" 1 "Tuerinnengriff_betaetigt" ;
VAL_ 977 BT_Tuer_Status 0 "Init" 1 "Tuer_geschlossen" 2 "Tuer_offen" 3 "Fehler" ;
VAL_ 977 BT_TSG_hinten_verbaut 0 "nicht verbaut" 1 "verbaut" ;
VAL_ 977 BT_Sp_Blk_def 0 "iO" 1 "Spiegel_Blinker_defekt" ;
VAL_ 977 BT_FH_S_ManHoch 0 "Init" 1 "FH_Schalter_man_hoch_gedrueckt" ;
VAL_ 977 BT_FH_S_AutoHoch 0 "Init" 1 "FH_Schalter_auto_hoch_gedrueckt" ;
VAL_ 977 BT_FH_S_ManTief 0 "Init" 1 "FH_Schalter_man_tief_gedrueckt" ;
VAL_ 977 BT_FH_S_AutoTief 0 "Init" 1 "FH_Schalter_auto_tief_gedrueckt" ;
VAL_ 977 BT_FH_Bew_hoch 0 "Init" 1 "FH_ist_in_Bewegung_hoch" ;
VAL_ 977 BT_FH_Bew_tief 0 "Init" 1 "FH_ist_in_Bewegung_tief" ;
VAL_ 977 BT_FH_Fang 0 "ausserhalb_Fangbereich" 1 "innerhalb_Fangbereich" ;
VAL_ 977 BT_FH_Block 0 "Init" 1 "Fensterheber_Block" ;
VAL_ 977 BT_FH_Thermo 0 "Init" 1 "Thermoschutz_aktiv" ;
VAL_ 977 BT_UEKB_aktiviert 0 "Init" 1 "aktiv" ;
VAL_ 977 BT_Kisi_Fehler 0 "kein_Fehler" 1 "Fehler" ;
VAL_ 977 BT_FH_normiert 0 "Init" 1 "Fenster_normiert" ;
VAL_ 977 BT_Schliesstaster 1 "betaetigt" ;
VAL_ 977 BT_Zuziehhilfe_aktiv 0 "Init" 1 "Zuziehhilfe_aktiv" ;
VAL_ 977 BT_SP_ausgerastet 0 "Init" 1 "Spiegel_ausgerastet" ;
VAL_ 977 BT_SP_lr_aktiv 0 "Init" 1 "Spiegel_xAchse_aktiv" ;
VAL_ 977 BT_SP_ht_aktiv 0 "Init" 1 "Spiegel_yAchse_aktiv" ;
VAL_ 977 BT_SP_Heizung_aktiv 1 "BF Spiegelheizung ein" ;
VAL_ 977 BT_Oben_Block_erw 0 "Fensterheber_nicht_in_Blockerwar" 1 "Fensterheber_in_Blockerwartung_o" ;
VAL_ 977 BT_Unten_Block_erw 0 "Fensterheber_nicht_in_Blockerwar" 1 "Fensterheber_in_Blockerwartung_u" ;
VAL_ 977 BT_Tuer_Status_QBit 0 "Status_Tuerkontakt_sicher" 1 "Status_Tuerkontakt_unsicher" ;
VAL_ 977 BFS_Status_eTAG 0 "Init" 1 "Griff_ausgefahren" 2 "Griff_eingefahren" 3 "Fehler" ;
VAL_ 977 BT_TCR_Mode_aktiv 0 "TCR_Mode_deaktiv" 1 "TCR_Mode_aktiv" ;
VAL_ 977 BT_SP_Heizung_Status 0 "Init" 1 "Status_Spiegelheizung_ein" ;
VAL_ 977 ASW_Warnung_aktiv_BFS 0 "nicht_angefordert" 1 "angefordert" ;
VAL_ 977 BT_FH_Pos_oben 1 "Scheibe oben (nach Absenken auf Position) " ;
VAL_ 977 BT_Tuerschloss_defekt 0 "Tuerschloss_funktionsfaehig" 1 "Tuerschloss_defekt" ;
VAL_ 977 BT_Tueroeffnen_Warnung 0 "Tuerwarnung_nicht_aktiv" 1 "Tuerwarnung_aktiv" ;
VAL_ 977 BT_Lock_Taster_inv 0 "Lock Taster betätigt" 1 "Lock Taster nicht betätigt" ;
VAL_ 977 BT_Schluesselschalter_zu_inv 0 "Schlüsselschalter betätigt" 1 "Schlüsselschalter nicht betätigt" ;
VAL_ 977 BT_SWA_HMI_defekt 0 "SWA_kein_Fehler" 1 "SWA_Fehler" ;
VAL_ 977 BT_ASW_HMI_defekt 0 "ASW_kein_Fehler" 1 "ASW_Fehler" ;
VAL_ 976 FT_Tuer_geoeffnet 0 "geschlossen" 1 "Tuer_offen" ;
VAL_ 976 FT_verriegelt 0 "Init" 1 "verriegelt" ;
VAL_ 976 FT_gesafet 0 "Init" 1 "gesafet" ;
VAL_ 976 FT_Schluesselschalter_auf 0 "Init" 1 "Schluesselschalter_auf_betaetigt" ;
VAL_ 976 FT_Schluesselschalter_zu 1 "Schluesselschalter zu betaetigt" ;
VAL_ 976 FT_Unlock_Taster 0 "Init" 1 "Unlock_Taster_betaetigt" ;
VAL_ 976 FT_Lock_Taster 0 "Init" 1 "Lock_Taster_betaetigt" ;
VAL_ 976 FT_Sperrklinke 0 "Schloss_in_Vorraste_und_Hauptraste" 1 "Tuer_auf_oder_Tuer_Position_zwischen_Vor_und_Hauptraste" ;
VAL_ 976 FT_TAG_betaetigt 0 "nicht_betaetigt" 1 "betaetigt" ;
VAL_ 976 FT_TIG_betaetigt 0 "nicht_betaetigt" 1 "betaetigt" ;
VAL_ 976 FT_IRUE_Taste 0 "Init" 1 "IRUE_Taste_betaetigt" ;
VAL_ 976 FT_HD_Taste 0 "nicht_betaetigt" 1 "Heckdeckeltaste_betaetigt" ;
VAL_ 976 FT_TD_Taste_Fehler 0 "iO" 1 "defekt" ;
VAL_ 976 FT_TD_Taste 0 "Init" 1 "Tankdeckel_Taster_betaetigt" ;
VAL_ 976 SSR_Temp_Freigabe 0 "SSR_Deaktiviert" 1 "SSR_Freigegeben" ;
VAL_ 976 FT_HD_Taste_2 0 "Taste_nicht_gedrueckt" 1 "Taste_gedrueckt" ;
VAL_ 976 FT_TSG_hinten_verbaut 0 "nicht verbaut" 1 "verbaut" ;
VAL_ 976 FT_Sp_Blk_def 0 "iO" 1 "defekt" ;
VAL_ 976 FT_FH_S_ManHoch 0 "Init" 1 "FH_Schalter_man_hoch_betaetigt" ;
VAL_ 976 FT_FH_S_AutoHoch 0 "Init" 1 "FH_Schalter_auto_hoch_betaetigt" ;
VAL_ 976 FT_FH_S_ManTief 0 "Init" 1 "FH_Schalter_man_tief_betaetigt" ;
VAL_ 976 FT_FH_S_AutoTief 0 "Init" 1 "FH_Schalter_auto_tief_betaetigt" ;
VAL_ 976 FT_FH_Bew_hoch 0 "Init" 1 "FH_in_Bewegung_hoch" ;
VAL_ 976 FT_FH_Bew_tief 0 "Init" 1 "FH_in_Bewegung_tief" ;
VAL_ 976 FT_FH_Fang 0 "ausserhalb_Fangbereich" 1 "innerhalb_Fangbereich" ;
VAL_ 976 FT_FH_Block 0 "Init" 1 "Fenster_Block" ;
VAL_ 976 FT_FH_Thermo 0 "Init" 1 "Thermoschutz_aktiv" ;
VAL_ 976 FT_UEKB_aktiviert 0 "Init" 1 "UEKB_aktiv" ;
VAL_ 976 ASW_HMI_defekt 0 "iO" 1 "defekt" ;
VAL_ 976 FT_FH_normiert 0 "Init" 1 "Fenster_normiert" ;
VAL_ 976 FT_Schliesstaster 1 "Schliesstaster_betaetigt" ;
VAL_ 976 FT_Zuziehhilfe_aktiv 0 "Init" 1 "Zuziehilfe_aktiv" ;
VAL_ 976 FT_SP_ausgerastet 0 "Init" 1 "Spiegel_ausgerastet" ;
VAL_ 976 FT_SP_lr_aktiv 0 "Init" 1 "Spiegel_xAchse_aktiv" ;
VAL_ 976 FT_SP_ht_aktiv 0 "Init" 1 "Spiegel_yAchse_aktiv" ;
VAL_ 976 ASW_wakeup 0 "Sleep" 1 "Wakeup" ;
VAL_ 976 FT_Oben_Block_erw 0 "Fensterheber_nicht_in_Blockerwar" 1 "Fensterheber_in_Blockerwartung_o" ;
VAL_ 976 FT_Unten_Block_erw 0 "Fensterheber_nicht_in_Blockerwar" 1 "Fensterheber_in_Blockerwartung_u" ;
VAL_ 976 FT_Kisi_li_aktiv 0 "inaktiv" 1 "aktiv" ;
VAL_ 976 FT_Kisi_re_aktiv 0 "inaktiv" 1 "aktiv" ;
VAL_ 976 FT_Kisi_Taster_li 0 "nicht_betaetigt" 1 "betaetigt" ;
VAL_ 976 FT_Kisi_Taster_re 0 "nicht_betaetigt" 1 "betaetigt" ;
VAL_ 976 FT_BFS_Fond_Freigabe 0 "Init" 1 "Freigabe_fuer_Fondbedienung_BFS" ;
VAL_ 976 FT_Kisi_Fehler 0 "kein_Fehler" 1 "Fehler" ;
VAL_ 976 FT_Daemmglas 0 "Normalglas_verbaut" 1 "Daemmglas_verbaut" ;
VAL_ 976 FT_SP_Heizung_Status 0 "Init" 1 "Status_Spiegelheizung_ein" ;
VAL_ 976 ASW_Warnung_aktiv_FS 0 "nicht_angefordert" 1 "angefordert" ;
VAL_ 976 FT_FH_Pos_oben 1 "Scheibe oben (nach Absenken auf Position) " ;
VAL_ 976 FT_Tuerschloss_defekt 0 "Tuerschloss_funktionsfaehig" 1 "Tuerschloss_defekt" ;
VAL_ 976 FT_SWA_Taster 0 "Taster_nicht_betaetigt" 1 "Taster_betaetigt" ;
VAL_ 976 SWA_HMI_Diagnose 0 "kein_Fehler_erkannt" 1 "Fehler_Taster_erkannt" 2 "Fehler_LED_erkannt" 3 "Fehler_LED_und_Taster_erkannt" ;
VAL_ 976 FS_Status_eTAG 0 "Init" 1 "Griff_ausgefahren" 2 "Griff_eingefahren" 3 "Fehler" ;
VAL_ 997 FT_Tuer_Status 0 "Init" 1 "Tuer_geschlossen" 2 "Tuer_offen" 3 "Fehler" ;
VAL_ 997 FT_Tuer_Status_QBit 0 "Status_Tuerkontakt_sicher" 1 "Status_Tuerkontakt_unsicher" ;
VAL_ 997 FT_Lock_Taster_02 0 "nicht_betaetigt" 1 "betaetigt" ;
VAL_ 997 FT_Schluesselschalter_zu_02 0 "nicht_betaetigt" 1 "betaetigt" ;
VAL_ 997 FT_BFS_Tuer_Status 0 "Init" 1 "Tuer_geschlossen" 2 "Tuer_offen" 3 "Fehler" ;
VAL_ 997 FT_HBFS_Tuer_Status 0 "Init" 1 "Tuer_geschlossen" 2 "Tuer_offen" 3 "Fehler" ;
VAL_ 997 FT_HFS_Tuer_Status 0 "Init" 1 "Tuer_geschlossen" 2 "Tuer_offen" 3 "Fehler" ;
VAL_ 997 FT_Tueroeffnen_Warnung 0 "Tuerwarnung_nicht_aktiv" 1 "Tuerwarnung_aktiv" ;
VAL_ 997 FT_SP_Heizung_ein 0 "Aus" 1 "Ein" ;
VAL_ 997 FT_Kisi_Taster_li_02 0 "nicht_betaetigt" 1 "betaetigt" ;
VAL_ 997 FT_Kisi_Taster_re_02 0 "nicht_betaetigt" 1 "betaetigt" ;
VAL_ 997 FT_TD_Taste_Status 0 "kein_Fehler" 1 "Kurzschluss_nach_Minus" 2 "Kurzschluss_nach_Plus" 3 "Leitungsunterbrechung" ;
VAL_ 997 FT_TCR_Mode_aktiv 0 "TCR_Mode_deaktiv" 1 "TCR_Mode_aktiv" ;
VAL_ 997 FS_Push_Tuergriff 0 "nicht_erkannt" 1 "erkannt" ;
VAL_ 975 HBFS_Tuer_geoeffnet 0 "geschlossen" 1 "offen" ;
VAL_ 975 HBFS_verriegelt 0 "nicht_verriegelt" 1 "verriegelt" ;
VAL_ 975 HBFS_gesafet 0 "nicht_gesafet" 1 "gesafet" ;
VAL_ 975 HBFS_Heckrollotaster_betaetigt 0 "keine_Verfahranweisung_in_Richtung_Hoch" 1 "In_Richtung_Hoch_Verfahren" ;
VAL_ 975 HBFS_Tuerschloss_defekt 0 "Tuerschloss_funktionsfaehig" 1 "Tuerschloss_defekt" ;
VAL_ 975 HBFS_Unlock_Taster 0 "nicht_betaetigt" 1 "betaetigt" ;
VAL_ 975 HBFS_Lock_Taster 0 "nicht_betaetigt" 1 "betaetigt" ;
VAL_ 975 HBFS_Sperrklinke 0 "Schloss_in_Vorraste_und_Hauptraste" 1 "Tuer_auf_oder_Tuer_Position_zwischen_Vor_und_Hauptraste" ;
VAL_ 975 HBFS_TAG_betaetigt 0 "nicht_betaetigt" 1 "betaetigt" ;
VAL_ 975 HBFS_TIG_betaetigt 0 "nicht_betaetigt" 1 "betaetigt" ;
VAL_ 975 HBFS_FH_S_HFS_AutoHoch 0 "keine_Bedienung" 1 "Automatiklauf_Angefordert" ;
VAL_ 975 HBFS_FH_S_HFS_AutoTief 0 "keine_Bedienung" 1 "Automatiklauf_Angefordert" ;
VAL_ 975 HBFS_FH_S_HFS_ManHoch 0 "keine_Bedienung" 1 "Manueller_Lauf_Angefordert" ;
VAL_ 975 HBFS_FH_S_HFS_ManTief 0 "keine_Bedienung" 1 "Manueller_Lauf_Angefordert" ;
VAL_ 975 HBFS_Tuer_Status 0 "Init" 1 "Tuer_geschlossen" 2 "Tuer_offen" 3 "Fehler" ;
VAL_ 975 HBFS_SAD_Schalter 0 "nicht_betaetigt" 5 "AUF_manuell" 6 "AUF_automatik" 7 "ZU_manuell" 8 "ZU_automatik" 13 "nicht_verfuegbar" 14 "Init" 15 "Fehler" ;
VAL_ 975 HBFS_FH_S_ManHoch 0 "nicht_betaetigt" 1 "betaetigt" ;
VAL_ 975 HBFS_FH_S_AutoHoch 0 "nicht_betaetigt" 1 "betaetigt" ;
VAL_ 975 HBFS_FH_S_ManTief 0 "nicht_betaetigt" 1 "betaetigt" ;
VAL_ 975 HBFS_FH_S_AutoTief 0 "nicht_betaetigt" 1 "betaetigt" ;
VAL_ 975 HBFS_FH_Bew_hoch 0 "inaktiv" 1 "aktiv" ;
VAL_ 975 HBFS_FH_Bew_tief 0 "inaktiv" 1 "aktiv" ;
VAL_ 975 HBFS_FH_Fang 0 "ausserhalb_Fangbereich" 1 "innerhalb_Fangbereich" ;
VAL_ 975 HBFS_FH_Block 0 "inaktiv" 1 "aktiv" ;
VAL_ 975 HBFS_FH_Thermo 0 "inaktiv" 1 "aktiv" ;
VAL_ 975 HBFS_UEKB_aktiviert 0 "inaktiv" 1 "aktiv" ;
VAL_ 975 HBFS_Tueroeffnen_Warnung 0 "Tuerwarnung_nicht_aktiv" 1 "Tuerwarnung_aktiv" ;
VAL_ 975 HBFS_FH_normiert 0 "inaktiv" 1 "aktiv" ;
VAL_ 975 ASW_Warnung_aktiv_HBFS 0 "nicht_angefordert" 1 "angefordert" ;
VAL_ 975 HBFS_Zuziehhilfe_aktiv 0 "Init" 1 "Zuziehhilfe_aktiv" ;
VAL_ 975 HBFS_Seitenrollo_hoch 1 "Seitenrollo_in_Bewegung_hoch" ;
VAL_ 975 HBFS_Seitenrollo_tief 0 "Init" 1 "Seitenrollo_in_Bewegung_tief" ;
VAL_ 975 HBFS_Status_KiSi 0 "inaktiv" 1 "aktiv" ;
VAL_ 975 SSR_HBFS_Pos_Unten 0 "SSR_Oben" 1 "SSR_Unten" ;
VAL_ 975 HBFS_Oben_Block_erw 0 "Fensterheber_nicht_in_Blockerwar" 1 "Fensterheber_in_Blockerwartung_o" ;
VAL_ 975 HBFS_Unten_Block_erw 0 "Fensterheber_nicht_in_Blockerwar" 1 "Fensterheber_in_Blockerwartung_u" ;
VAL_ 975 MTHBFS_M_Taste 0 "nicht_betaetigt" 1 "betaetigt" ;
VAL_ 975 MTHBFS_Pos1 0 "nicht_betaetigt" 1 "betaetigt" ;
VAL_ 975 MTHBFS_Pos2 0 "nicht_betaetigt" 1 "betaetigt" ;
VAL_ 975 MTHBFS_Pos3 0 "nicht_betaetigt" 1 "betaetigt" ;
VAL_ 975 HBFS_MRollo_Schalter 0 "nicht_betaetigt" 1 "ZU_manuell" 2 "ZU_automatik" 3 "AUF_manuell" 4 "AUF_automatik" 5 "nicht_verfuegbar" 6 "Init" 7 "Fehler" ;
VAL_ 975 HBFS_Lock_Taster_inv 0 "Lock Taster betätgit" 1 "Lock Taster nicht betätigt" ;
VAL_ 975 HBFS_Status_KiSi_inv 0 "aktiv" 1 "inaktiv" ;
VAL_ 975 HBFS_Status_eTAG 0 "Init" 1 "Griff_ausgefahren" 2 "Griff_eingefahren" 3 "Fehler" ;
VAL_ 975 HBFS_Tuer_Status_QBit 0 "Status_Tuerkontakt_sicher" 1 "Status_Tuerkontakt_unsicher" ;
VAL_ 975 HBFS_TIG_betaetigt_schliessen 0 "nicht_betaetigt" 1 "betaetigt" ;
VAL_ 974 HFS_Tuer_geoeffnet 0 "geschlossen" 1 "offen" ;
VAL_ 974 HFS_verriegelt 0 "nicht_verriegelt" 1 "verriegelt" ;
VAL_ 974 HFS_gesafet 0 "nicht_gesafet" 1 "gesafet" ;
VAL_ 974 HFS_Heckrollotaster_betaetigt 0 "keine_Verfahranweisung_in_Richtung_Hoch" 1 "In_Richtung_Hoch_Verfahren" ;
VAL_ 974 HFS_Tuerschloss_defekt 0 "Tuerschloss_funktionsfaehig" 1 "Tuerschloss_defekt" ;
VAL_ 974 HFS_Unlock_Taster 0 "nicht_betaetigt" 1 "betaetigt" ;
VAL_ 974 HFS_Lock_Taster 0 "nicht_betaetigt" 1 "betaetigt" ;
VAL_ 974 HFS_Sperrklinke 0 "Schloss_in_Vorraste_und_Hauptraste" 1 "Tuer_auf_oder_Tuer_Position_zwischen_Vor_und_Hauptraste" ;
VAL_ 974 HFS_TAG_betaetigt 0 "nicht_betaetigt" 1 "betaetigt" ;
VAL_ 974 HFS_TIG_betaetigt 0 "nicht_betaetigt" 1 "betaetigt" ;
VAL_ 974 HFS_FH_S_HBFS_AutoHoch 0 "keine_Bedienung" 1 "Automatiklauf_Angefordert" ;
VAL_ 974 HFS_FH_S_HBFS_AutoTief 0 "keine_Bedienung" 1 "Automatiklauf_Angefordert" ;
VAL_ 974 HFS_FH_S_HBFS_ManHoch 0 "keine_Bedienung" 1 "Manueller_Lauf_Angefordert" ;
VAL_ 974 HFS_FH_S_HBFS_ManTief 0 "keine_Bedienung" 1 "Manueller_Lauf_Angefordert" ;
VAL_ 974 HFS_Tuer_Status 0 "Init" 1 "Tuer_geschlossen" 2 "Tuer_offen" 3 "Fehler" ;
VAL_ 974 HFS_SAD_Schalter 0 "nicht_betaetigt" 5 "AUF_manuell" 6 "AUF_automatik" 7 "ZU_manuell" 8 "ZU_automatik" 13 "nicht_verfuegbar" 14 "Init" 15 "Fehler" ;
VAL_ 974 HFS_FH_S_ManHoch 0 "nicht_betaetigt" 1 "betaetigt" ;
VAL_ 974 HFS_FH_S_AutoHoch 0 "nicht_betaetigt" 1 "betaetigt" ;
VAL_ 974 HFS_FH_S_ManTief 0 "nicht_betaetigt" 1 "betaetigt" ;
VAL_ 974 HFS_FH_S_AutoTief 0 "nicht_betaetigt" 1 "betaetigt" ;
VAL_ 974 HFS_FH_Bew_hoch 0 "inaktiv" 1 "aktiv" ;
VAL_ 974 HFS_FH_Bew_tief 0 "inaktiv" 1 "aktiv" ;
VAL_ 974 HFS_FH_Fang 0 "ausserhalb_Fangbereich" 1 "innerhalb_Fangbereich" ;
VAL_ 974 HFS_FH_Block 0 "inaktiv" 1 "aktiv" ;
VAL_ 974 HFS_FH_Thermo 0 "inaktiv" 1 "aktiv" ;
VAL_ 974 HFS_UEKB_aktiviert 0 "inaktiv" 1 "aktiv" ;
VAL_ 974 HFS_Tueroeffnen_Warnung 0 "Tuerwarnung_nicht_aktiv" 1 "Tuerwarnung_aktiv" ;
VAL_ 974 HFS_FH_normiert 0 "inaktiv" 1 "aktiv" ;
VAL_ 974 ASW_Warnung_aktiv_HFS 0 "nicht_angefordert" 1 "angefordert" ;
VAL_ 974 HFS_Zuziehhilfe_aktiv 0 "Init" 1 "Zuziehhilfe_aktiv" ;
VAL_ 974 HFS_Seitenrollo_hoch 0 "Init" 1 "Seitenrollo_in_Bewegung_hoch" ;
VAL_ 974 HFS_Seitenrollo_tief 0 "Init" 1 "Seitenrollo_in_Bewegung_tief" ;
VAL_ 974 HFS_Status_KiSi 0 "inaktiv" 1 "aktiv" ;
VAL_ 974 SSR_HFS_Pos_Unten 0 "SSR_Oben" 1 "SSR_Unten" ;
VAL_ 974 HFS_Oben_Block_erw 0 "Fensterheber_nicht_in_Blockerwar" 1 "Fensterheber_in_Blockerwartung_o" ;
VAL_ 974 HFS_Unten_Block_erw 0 "Fensterheber_nicht_in_Blockerwar" 1 "Fensterheber_in_Blockerwartung_u" ;
VAL_ 974 MTHFS_M_Taste 0 "nicht_betaetigt" 1 "betaetigt" ;
VAL_ 974 MTHFS_Pos1 0 "nicht_betaetigt" 1 "betaetigt" ;
VAL_ 974 MTHFS_Pos2 0 "nicht_betaetigt" 1 "betaetigt" ;
VAL_ 974 MTHFS_Pos3 0 "nicht_betaetigt" 1 "betaetigt" ;
VAL_ 974 HFS_MRollo_Schalter 0 "nicht_betaetigt" 1 "ZU_manuell" 2 "ZU_automatik" 3 "AUF_manuell" 4 "AUF_automatik" 5 "nicht_verfuegbar" 6 "Init" 7 "Fehler" ;
VAL_ 974 HFS_Lock_Taster_inv 0 "Lock Taster betätgit" 1 "Lock Taster nicht betätigt" ;
VAL_ 974 HFS_Status_eTAG 0 "Init" 1 "Griff_ausgefahren" 2 "Griff_eingefahren" 3 "Fehler" ;
VAL_ 974 HFS_Tuer_Status_QBit 0 "Status_Tuerkontakt_sicher" 1 "Status_Tuerkontakt_unsicher" ;
VAL_ 974 HFS_TCR_Mode_aktiv 0 "TCR_Mode_deaktiv" 1 "TCR_Mode_aktiv" ;
VAL_ 618 USS_MKE_Risiko 0 "gering" 1 "mittel" 2 "hoch" 3 "unbekannt" ;
VAL_ 618 USS_MKE_Index_Anstieg 0 "stark_abfallend" 1 "leicht_abfallend" 2 "gleichbleibend" 3 "leicht_ansteigend" 4 "stark_ansteigend" 5 "unbekannt" ;
VAL_ 618 USS_MKE_Index_Quelle_LWS_Basis 0 "nicht_verwendet" 1 "verwendet" ;
VAL_ 618 USS_MKE_Index_Quelle_LWS_Plus 0 "nicht_verwendet" 1 "verwendet" ;
VAL_ 618 USS_MKE_Index_Quelle_MFK 0 "nicht_verwendet" 1 "verwendet" ;
VAL_ 618 USS_MKE_Index_Quelle_FBK 0 "nicht_verwendet" 1 "verwendet" ;
VAL_ 618 USS_MKE_Index 126 "Init" 127 "Fehler" ;
VAL_ 618 USS_MKE_Index_Quelle_Biometrisch 0 "nicht_verwendet" 1 "verwendet" ;
VAL_ 618 USS_Fahrzeit_seit_Pause 1022 "keine_Fahrzeit_vorhanden" 1023 "Fehler" ;
VAL_ 618 USS_Fahrer_Texte 0 "keine_Anzeige" 1 "MKE_Warnstufe_1" 2 "MKE_Warnstufe_2" ;
VAL_ null USSDM_FakeDetected 0 "No_fake_detected" 1 "Fake_detected" ;
VAL_ null USSDM_EyesClosed 0 "Eyes_not_closed" 1 "Eyes_closed" 2 "Unknown" 3 "No_eyes_found" ;
VAL_ null USSDM_EyesFound 0 "Eyes_not_found" 1 "Eyes_found" ;
VAL_ null USSDM_EyesOnRoad 0 "Eyes_not_on_road" 1 "Eyes_on_road" 2 "Reserved" 3 "Unknown" 4 "Init" 5 "Fehler" ;
VAL_ null USSDM_Microsleep 0 "No_microsleep_detected" 1 "Microsleep_imminent" 2 "Microsleep_detected" 6 "Init" 7 "Fehler" ;
VAL_ null USSDM_MicrosleepQual 13 "Unknown" 14 "Init" 15 "Fehler" ;
VAL_ null USSDM_HeadFound 0 "Head_not_found" 1 "Head_found" ;
VAL_ null USSDM_HeadBasedMirrorSelection 0 "intermediate_area" 1 "driver_side_mirror" 2 "passenger_side_mirror" 3 "unplausible_init" ;
VAL_ null USSDM_EyesOffRoadTime 509 "Unknown" 510 "Init" 511 "Fehler" ;
VAL_ null USSDM_EyesOnRoadQual 14 "Init" 15 "Fehler" ;
VAL_ null USSDM_CalibrationStatus 0 "Pending" 1 "Complete" 2 "Not_initialized" 6 "Init" 7 "Fehler" ;
VAL_ null USSDM_DriverPresence 0 "No_driver_present" 1 "Driver_present" 2 "Driver_present_and_buckled" 6 "Init" 7 "Fehler" ;
VAL_ null USSDM_Status 0 "Inactive" 1 "Running" 2 "Not_available" 6 "Init" 7 "Fehler" ;
VAL_ null USSDM_EyesOpen 0 "Eyes_not_open" 1 "Eyes_open" 2 "Unknown" 3 "No_eyes_found" ;
VAL_ null USSDM_VisualDistractionQual 14 "Init" 15 "Fehler" ;
VAL_ null USSDM_VisualDistractionLevel 0 "Not_distracted" 1 "Slightly_distracted" 2 "Distracted" 3 "Very_distracted" 5 "Unknown" 6 "Init" 7 "Fehler" ;
VAL_ null USSDM_Blindness 0 "No_blindness" 1 "Temporary_blindness" 2 "Permanent_blindness" 3 "Steering_wheel_blindness" 6 "Init" 7 "Fehler" ;
VAL_ null USSDM_TotDurEyesNotOnTfc 1021 "Unknown" 1022 "Init" 1023 "Fehler" ;
VAL_ null USSDM_DurEyesOffTfc 508 "Max_value_reached" 509 "Unknown" 510 "Init" 511 "Fehler" ;
VAL_ null USSDM_DetectionMode 0 "Gaze" 1 "Head_pose" 2 "Combined" 3 "None" 6 "Init" 7 "Fehler" ;
VAL_ null USSDM_ProbScndTsk 125 "Unknown" 126 "Init" 127 "Fehler" ;
VAL_ null USSDM_EyesOnTrafficQual 13 "Unknown" 14 "Init" 15 "Fehler" ;
VAL_ null USSDM_SpaAttDstrAr_01 0 "Unknown" 1 "Windshield_top_left" 2 "Windshield_top_right" 3 "Windshield_bottom_left" 4 "Windshield_bottom_center" 5 "Windshield_bottom_right" 6 "Windshield_bottom_far_right" 7 "Light_switch" 8 "Sidemirror_left" 9 "Sidemirror_right" 10 "Rear_view_mirror" 11 "Instrument_cluster" 12 "Dashboard" 13 "Steering_wheel" 14 "Infotainment_display" 15 "Center_console" 16 "Driver_lap" 17 "Glovebox" 18 "Far_left" 19 "Far_right" 30 "Init" 31 "Fehler" ;
VAL_ null USSDM_SpaAttDstrAr_02 0 "Unknown" 1 "Windshield_top_left" 2 "Windshield_top_right" 3 "Windshield_bottom_left" 4 "Windshield_bottom_center" 5 "Windshield_bottom_right" 6 "Windshield_bottom_far_right" 7 "Light_switch" 8 "Sidemirror_left" 9 "Sidemirror_right" 10 "Rear_view_mirror" 11 "Instrument_cluster" 12 "Dashboard" 13 "Steering_wheel" 14 "Infotainment_display" 15 "Center_console" 16 "Driver_lap" 17 "Glovebox" 18 "Far_left" 19 "Far_right" 30 "Init" 31 "Fehler" ;
VAL_ null USSDM_SpaAttDstrAr_03 0 "Unknown" 1 "Windshield_top_left" 2 "Windshield_top_right" 3 "Windshield_bottom_left" 4 "Windshield_bottom_center" 5 "Windshield_bottom_right" 6 "Windshield_bottom_far_right" 7 "Light_switch" 8 "Sidemirror_left" 9 "Sidemirror_right" 10 "Rear_view_mirror" 11 "Instrument_cluster" 12 "Dashboard" 13 "Steering_wheel" 14 "Infotainment_display" 15 "Center_console" 16 "Driver_lap" 17 "Glovebox" 18 "Far_left" 19 "Far_right" 30 "Init" 31 "Fehler" ;
VAL_ null USSDM_SpaAttDstrProb_01 13 "Unknown" 14 "Init" 15 "Fehler" ;
VAL_ null USSDM_SpaAttDstrProb_02 13 "Unknown" 14 "Init" 15 "Fehler" ;
VAL_ null USSDM_SpaAttDstrProb_03 13 "Unknown" 14 "Init" 15 "Fehler" ;
VAL_ null USSDM_DurEyesCl 124 "Max_value_reached" 125 "Unknown" 126 "Init" 127 "Fehler" ;
VAL_ null USSDM_PercentageEyesOnTraffic 125 "Unknown" 126 "Init" 127 "Fehler" ;
VAL_ null USSDM_ViewingDirectionQuality 14 "Init" 15 "Fehler" ;
VAL_ null USSDM_ViewingDirectionYaw 254 "Init" 255 "Fehler" ;
VAL_ null USSDM_ViewingDirectionPitch 126 "Init" 127 "Fehler" ;
VAL_ null USSDM_DurEyesNotOnTfc 508 "Max_value_reached" 509 "Unknown" 510 "Init" 511 "Fehler" ;
VAL_ null USSDM_DrowsinessLevel 0 "Extremely_alert" 1 "Very_alert" 2 "Alert" 3 "Fairly_alert" 4 "Neither_alert_nor_sleepy" 5 "Signs_of_sleepiness" 6 "Sleepy_no_effort" 7 "Sleepy_some_effort" 8 "Very_Sleepy" 13 "Unknown" 14 "Init" 15 "Fehler" ;
VAL_ null USSDM_DrowsinessQual 14 "Init" 15 "Fehler" ;
VAL_ null USSDM_UnusualHeadPose 0 "No_unusual_head_pose" 1 "Unusual_head_pose" 2 "Unknown" 6 "Init" 7 "Fehler" ;
VAL_ null USSDM_DriverChange 0 "No_driver_change_detected" 1 "Driver_change_detected" ;
VAL_ null USSDM_DriverSpeaking 0 "Driver_not_speaking" 1 "Driver_speaking" ;
VAL_ null USSDM_BlinkRate 28 "Max_reached" 29 "Unknown" 30 "Init" 31 "Fehler" ;
VAL_ null USSDM_DriverYawning 0 "No_yawning_detected" 1 "Yawning_detected" 4 "Unknown" 5 "Not_installed" 6 "Init" 7 "Fehler" ;
VAL_ null USSDM_DriverPhoneUsage 0 "No_phone_usage_detected" 1 "Phone_usage_detected" 4 "Unknown" 5 "Not_installed" 6 "Init" 7 "Fehler" ;
VAL_ null USSDM_DriverPhoneUsageQual 13 "Unknown" 14 "Init" 15 "Fehler" ;
VAL_ null USSDM_DriverYawningQual 13 "Unknown" 14 "Init" 15 "Fehler" ;
VAL_ null USSDM_DriverSmokingQual 13 "Unknown" 14 "Init" 15 "Fehler" ;
VAL_ null USSDM_UnusualHeadPoseQual 13 "Unknown" 14 "Init" 15 "Fehler" ;
VAL_ null USSDM_DriverSmoking 0 "No_smoking_detected" 1 "Smoking_detected" 4 "Unknown" 5 "Not_installed" 6 "Init" 7 "Fehler" ;
VAL_ 2463978633 VAS_L_Bedien_Master 0 "Bedien_Slave" 1 "Bedien_Master" ;
VAL_ 2463978633 VAS_L_Parkview_aktiv 0 "Parkview_nicht_aktiv" 1 "Parkview_aktiv" ;
VAL_ 2463978633 VAS_L_Autobahnview_aktiv 0 "Autobahnview_nicht_aktiv" 1 "Autobahnview_aktiv" ;
VAL_ 2463978633 VAS_L_Turnview_aktiv 0 "Turnview_nicht_aktiv" 1 "Turnview_aktiv" ;
VAL_ 2463978633 VAS_L_HMI_Aktiv 0 "HMI_Inaktiv" 1 "HMI_Aktiv" ;
VAL_ 2463978633 VAS_L_SWA_HMI_Diagnose 0 "kein_Fehler_erkannt" 1 "Fehler_erkannt" ;
VAL_ 2463978633 VAS_L_Texte 0 "keine_Stoerung" 1 "Kameras_verschmutzt" 2 "Systemstoerung_links" 3 "Systemstoerung_rechts" 4 "allgemeine_Systemstoerung" 7 "Init" ;
VAL_ 2463978633 VAS_L_Spiegelauswahl 0 "Spiegel_links" 1 "Spiegel_rechts" ;
VAL_ 2463978633 VAS_L_Verstell_Pos_X 511 "Fehler" ;
VAL_ 2463978633 VAS_L_Heizung_Aktiv 127 "Fehler" ;
VAL_ 2463978633 VAS_L_Verstell_Pos_Y 511 "Fehler" ;
VAL_ 2463978633 VAS_L_Zoom_Level 127 "Fehler" ;
VAL_ 2463978634 VAS_R_Bedien_Master 0 "Bedien_Slave" 1 "Bedien_Master" ;
VAL_ 2463978634 VAS_R_Autobahnview_aktiv 0 "Autobahnview_nicht_aktiv" 1 "Autobahnview_aktiv" ;
VAL_ 2463978634 VAS_R_Parkview_aktiv 0 "Parkview_nicht_aktiv" 1 "Parkview_aktiv" ;
VAL_ 2463978634 VAS_R_Turnview_aktiv 0 "Turnview_nicht_aktiv" 1 "Turnview_aktiv" ;
VAL_ 2463978634 VAS_R_HMI_Aktiv 0 "HMI_Inaktiv" 1 "HMI_Aktiv" ;
VAL_ 2463978634 VAS_R_SWA_HMI_Diagnose 0 "kein_Fehler_erkannt" 1 "Fehler_erkannt" ;
VAL_ 2463978634 VAS_R_Fahrerwarnung 0 "keine_Stoerung" 1 "Kameras_verschmutzt" 2 "Systemstoerung_links" 3 "Systemstoerung_rechts" 4 "allgemeine_Systemstoerung" 7 "Init" ;
VAL_ 2463978634 VAS_R_Spiegelauswahl 0 "Spiegel_links" 1 "Spiegel_rechts" ;
VAL_ 2463978634 VAS_R_Verstell_Pos_X 511 "Fehler" ;
VAL_ 2463978634 VAS_R_Heizung_Aktiv 127 "Fehler" ;
VAL_ 2463978634 VAS_R_Verstell_Pos_Y 511 "Fehler" ;
VAL_ 2463978634 VAS_R_Zoom_Level 127 "Fehler" ;
VAL_ 995 VS_VD_zu_ver 1 "Zustand des Verdecks verriegelt und geschlossen" ;
VAL_ 995 VS_VD_entriegelt 0 "Init" 1 "Zustand_des_Verdeck_entriegelt" ;
VAL_ 995 VS_VD_offen_ver 0 "Init" 1 "Verdeck_verriegelt_und_offen" ;
VAL_ 995 VS_VD_Zwischenposition 0 "Init" 1 "Verdeck_in_Zwischenposition" ;
VAL_ 995 VS_VD_Bew_auf 1 "Verdeck in Bewegung auf" ;
VAL_ 995 VS_VD_Bew_zu 1 "Verdeck in Bewegung zu" ;
VAL_ 995 VS_Verdeck_Anf 0 "init_nicht_aktiv" 1 "aktiv" ;
VAL_ 995 VS_Hardtop 0 "Init" 1 "Hardtop_montiert" ;
VAL_ 995 VS_VD_Fehler 0 "Init" 1 "Fehlerzustand Verdeck" ;
VAL_ 995 VS_Lampe_Blk 0 "Kontrollleuchte_inaktiv" 1 "Kontrollleuchte_aktiv" ;
VAL_ 995 VS_HD_sperren 0 "HD Entriegelung freigegeben" 1 "HD Entriegelung gesperrt" ;
VAL_ 995 VS_HHS_enable 0 "Init" 1 "Freigabe HHS" ;
VAL_ 995 VD_SpannungsAnf 0 "keine_Anforderung" 1 "Anforderung_Stufe1" 2 "Anforderung_Stufe2" 3 "Anforderung_Stufe3" ;
VAL_ 995 VS_VDKD_auf 0 "VDKD_nicht_vollst_auf" 1 "VDKD_vollstaendig_auf" ;
VAL_ 995 VS_FS_AutoHoch 0 "Keine_Verfahranforderung" 1 "Automatischer_Hochlauf" ;
VAL_ 995 VS_FS_AutoTief 0 "Keine_Verfahranforderung" 1 "Automatischer_Tieflauf" ;
VAL_ 995 VS_FS_ManHoch 0 "Keine_Verfahranforderung" 1 "Manueller_Hochlauf" ;
VAL_ 995 VS_FS_ManTief 0 "Keine_Verfahranforderung" 1 "Manueller_Tieflauf" ;
VAL_ 995 VS_BFS_AutoHoch 0 "Keine_Verfahranforderung" 1 "Automatischer_Hochlauf" ;
VAL_ 995 VS_BFS_AutoTief 0 "Keine_Verfahranforderung" 1 "Automatischer_Tieflauf" ;
VAL_ 995 VS_BFS_ManHoch 0 "Keine_Verfahranforderung" 1 "Manueller_Hochlauf" ;
VAL_ 995 VS_BFS_ManTief 0 "Keine_Verfahranforderung" 1 "Manueller_Tieflauf" ;
VAL_ 995 VS_HFS_AutoHoch 0 "Keine_Verfahranforderung" 1 "Automatischer_Hochlauf" ;
VAL_ 995 VS_HFS_AutoTief 0 "Keine_Verfahranforderung" 1 "Automatischer_Tieflauf" ;
VAL_ 995 VS_HFS_ManHoch 0 "Keine_Verfahranforderung" 1 "Manueller_Hochlauf" ;
VAL_ 995 VS_HFS_ManTief 0 "Keine_Verfahranforderung" 1 "Manueller_Tieflauf" ;
VAL_ 995 VS_HBFS_AutoHoch 0 "Keine_Verfahranforderung" 1 "Automatischer_Hochlauf" ;
VAL_ 995 VS_HBFS_AutoTief 0 "Keine_Verfahranforderung" 1 "Automatischer_Tieflauf" ;
VAL_ 995 VS_HBFS_ManHoch 0 "Keine_Verfahranforderung" 1 "Manueller_Hochlauf" ;
VAL_ 995 VS_HBFS_ManTief 0 "Keine_Verfahranforderung" 1 "Manueller_Tieflauf" ;
VAL_ 995 VS_FH_FT_Langhub 0 "Init" ;
VAL_ 995 VS_Windschott_nicht_abgelegt 0 "inaktiv" 1 "aktiv" ;
VAL_ 995 VS_FH_BT_Langhub 0 "Init" ;
VAL_ 995 VS_FH_HFS_Langhub 0 "Init" ;
VAL_ 995 VS_Heckschloss_auf 0 "kein_Oeffnen" 1 "Heckschloss_oeffnen" ;
VAL_ 995 VS_FH_HBFS_Langhub 0 "Init" ;
VAL_ 995 VSG_Meldungen 0 "keine_Meldung" ;
VAL_ 995 VS_StartStopp_Info 0 "Stoppfreigabe" 1 "Stoppverbot" 2 "Startanforderung" 3 "Fehler" ;
VAL_ 1702 Wischer_vorne_aktiv 0 "Init" 1 "Wischer_vorne_laeuft" ;
VAL_ 1702 Waschen_vorne_aktiv 0 "inaktiv" 1 "Waschen_aktiv" ;
VAL_ 1702 Wischer_vorne_Normal 1 "Wischer Front normal aktiv" ;
VAL_ 1702 Wischer_vorne_Schnell 1 "Wischer vorne schnell aktiv" ;
VAL_ 1702 Wischer_vorne_Parklage 0 "Wischer_Front_nicht_in_Parklage" 1 "Wischer_Front_in_Parklage__Initialzustand" ;
VAL_ 1702 Wischer_vorne_defekt 0 "Init" 1 "Wischer vorne defekt" ;
VAL_ 1702 Wischer_vorne_blockiert 1 "Wischer vorne blockiert" ;
VAL_ 1702 Wischer1_Wischgeschwindigkeit 0 "0 U/min" 62 "Init" 63 "Fehler" ;
VAL_ 1702 BCM1_SRA_aktiv 0 "nicht aktiv" 1 "aktiv" ;
VAL_ 1702 Heckwischer_Anforderung 0 "Aus" 1 "Ein" ;
VAL_ 1702 WWSs_01_upd 0 "nicht_aktuell" 1 "aktuell" ;
VAL_ 1702 Wischer_Anzeigetext 0 "keine_Anzeige" 1 "Hinweis_Service_Position" 2 "void" 3 "void" ;
VAL_ 1411 BCM_FH_Freigabe 1 "Funktionsfreigabe Fensterheber" ;
VAL_ 1411 BCM_Komfortfkt_Freigabe 0 "Komfortfunktion gesperrt" 1 "globale Freigabe der Komfortfunktion erteilt" ;
VAL_ 1411 BCM_HSK_Freigabe 0 "erlauben" 1 "sperren" ;
VAL_ 1411 BCM_Verdeck_Freigabe 0 "Verdeckbetrieb nicht erlaubt" 1 "Verdeckbetrieb erlaubt" ;
VAL_ 1411 ZV_verriegelt_intern_ist 1 "Fahrzeug innen verriegelt; Istzustand" ;
VAL_ 1411 ZV_verriegelt_extern_ist 1 "Fahrzeug_aussen_verriegelt_Istzustand" ;
VAL_ 1411 ZV_verriegelt_intern_soll 1 "Fahrzeug verriegelt intern; Sollzusstand" ;
VAL_ 1411 ZV_verriegelt_extern_soll 1 "Fahrzeug verriegelt extern; Sollzusstand" ;
VAL_ 1411 ZV_gesafet_extern_ist 1 "Fahrzeug aussen gesafet; Istzustand" ;
VAL_ 1411 ZV_gesafet_extern_soll 1 "Fahrzeug_aussen_gesafet_Sollzustand" ;
VAL_ 1411 ZV_Einzeltuerentriegelung 1 "Fahrzeug an Einzeltuer entriegelt" ;
VAL_ 1411 ZV_Heckeinzelentriegelung 1 "Heckdeckeleinzelentriegelung" ;
VAL_ 1411 ZV_FT_offen 0 "FT_geschlossen" 1 "FT_geoeffnet" ;
VAL_ 1411 ZV_BT_offen 0 "BT_geschlossen" 1 "BT_geoeffnet" ;
VAL_ 1411 ZV_HFS_offen 0 "geschlossen" 1 "offen" ;
VAL_ 1411 ZV_HBFS_offen 0 "geschlossen" 1 "offen" ;
VAL_ 1411 ZV_HD_offen 1 "Heckdeckel_auf" ;
VAL_ 1411 ZV_HS_offen 0 "Heckscheibe_geschlossen" 1 "Heckscheibe auf" ;
VAL_ 1411 IRUE_aktiv 0 "unscharf" 1 "scharf" ;
VAL_ 1411 DWA_aktiv 0 "unscharf" 1 "scharf" ;
VAL_ 1411 HD_Hauptraste 0 "geschlossen" 1 "offen" ;
VAL_ 1411 HD_Vorraste 0 "geschlossen" 1 "offen" ;
VAL_ 1411 FFB_CarFinder 0 "nicht aktiv" 1 "aktiv" ;
VAL_ 1411 FFB_Komfortoeffnen 0 "kein_Komfortoeffnen_empfangen" 1 "Komfortoeffnen ueber Funk empfangen" ;
VAL_ 1411 FFB_Komfortschliessen 0 "kein_Komfortschliessen_empfangen" 1 "Komfortschliessen ueber Funk empfangen" ;
VAL_ 1411 ZV_Schluessel_Zugang 0 "kein_auth_Schluessel_erkannt" 1 "aktive_Funkschluessel_Nr_01" 2 "aktive_Funkschluessel_Nr_02" 3 "aktive_Funkschluessel_Nr_03" 4 "aktive_Funkschluessel_Nr_04" 5 "aktive_Funkschluessel_Nr_05" 6 "aktive_Funkschluessel_Nr_06" 7 "aktive_Funkschluessel_Nr_07" 8 "aktive_Funkschluessel_Nr_08" 9 "aktive_SmartDevice_Nr_09" 10 "ungueltig_10" 11 "ungueltig_11" 12 "ungueltig_12" 13 "ungueltig_13" 14 "ungueltig_14" 15 "ungueltig_15" ;
VAL_ 1411 ZV_SafeFunktion_aktiv 0 "inaktiv" 1 "aktiv" ;
VAL_ 1411 FBS_Warn_Schluessel_Batt 0 "i.O." 1 "defekt" ;
VAL_ 1411 ZV_Oeffnungsmodus 0 "globale_Oeffnung" 1 "ZV_mit_Einzeltuerentr" 2 "ZV_individuell_selektiv" 3 "ZV_seitenselektiv" ;
VAL_ 1411 HFS_verriegelt 0 "nicht_verriegelt" 1 "verriegelt" ;
VAL_ 1411 HFS_gesafet 0 "nicht_gesafet" 1 "gesafet" ;
VAL_ 1411 HBFS_verriegelt 0 "nicht_verriegelt" 1 "verriegelt" ;
VAL_ 1411 HBFS_gesafet 0 "nicht_gesafet" 1 "gesafet" ;
VAL_ 1411 ZV_ist_Zustand_verfuegbar 0 "nicht_verfuegbar" 1 "verfuegbar_alle_TSGs_am_Bus" ;
VAL_ 1411 IRUE_Taster_Fkts_LED 0 "LED_aus" 1 "LED_ein" ;
VAL_ 1411 ZV_Tankklappe_offen 0 "Tankklappe_geschlossen" 1 "Tankklappe_offen" ;
VAL_ 1411 ZV_Rollo_auf 0 "inaktiv" 1 "aktiv" ;
VAL_ 1411 ZV_Rollo_zu 0 "inaktiv" 1 "aktiv" ;
VAL_ 1411 ZV_SAD_auf 0 "inaktiv" 1 "aktiv" ;
VAL_ 1411 ZV_SAD_zu 0 "inaktiv" 1 "aktiv" ;
VAL_ 1411 BCM_Tankklappensteller_Fehler 0 "kein_Fehler" 1 "Fehler" ;
VAL_ 1411 ZV_verriegelt_soll 0 "Init" 1 "nicht_verriegelt" 2 "verriegelt" ;
